VERSION ""

NS_ :

BS_ :

BU_ : CAB FED HAD JDL OBT OBT_FA PDU POD VTV XCP DC1 MTU

BO_ 2565406513 Acknowledgment_CAB: 8 CAB

BO_ 2565406664 Acknowledgment_DC1: 8 DC1

BO_ 2565406698 Acknowledgment_FED: 8 FED

BO_ 2565406699 Acknowledgment_HAD: 8 HAD

BO_ 2565406555 Acknowledgment_POD: 8 POD

BO_ 2565392433 Acknowledgment_TX_CAB_RX_DC1: 8 CAB

BO_ 2565401137 Acknowledgment_TX_CAB_RX_FED: 8 CAB

BO_ 2565401393 Acknowledgment_TX_CAB_RX_HAD: 8 CAB

BO_ 2565364529 Acknowledgment_TX_CAB_RX_POD: 8 CAB

BO_ 2565353928 Acknowledgment_TX_DC1_RX_CAB: 8 DC1

BO_ 2565401288 Acknowledgment_TX_DC1_RX_FED: 8 DC1

BO_ 2565401544 Acknowledgment_TX_DC1_RX_HAD: 8 DC1

BO_ 2565364680 Acknowledgment_TX_DC1_RX_POD: 8 DC1

BO_ 2565353962 Acknowledgment_TX_FED_RX_CAB: 8 FED

BO_ 2565392618 Acknowledgment_TX_FED_RX_DC1: 8 FED

BO_ 2565401578 Acknowledgment_TX_FED_RX_HAD: 8 FED

BO_ 2565364714 Acknowledgment_TX_FED_RX_POD: 8 FED

BO_ 2565353963 Acknowledgment_TX_HAD_RX_CAB: 8 HAD

BO_ 2565392619 Acknowledgment_TX_HAD_RX_DC1: 8 HAD

BO_ 2565401323 Acknowledgment_TX_HAD_RX_FED: 8 HAD

BO_ 2565364715 Acknowledgment_TX_HAD_RX_POD: 8 HAD

BO_ 2565353819 Acknowledgment_TX_POD_RX_CAB: 8 POD

BO_ 2565392475 Acknowledgment_TX_POD_RX_DC1: 8 POD

BO_ 2565401179 Acknowledgment_TX_POD_RX_FED: 8 POD

BO_ 2565401435 Acknowledgment_TX_POD_RX_HAD: 8 POD

BO_ 2565799729 Address_Claimed_CAB: 8 CAB

BO_ 2565799880 Address_Claimed_DC1: 8 DC1

BO_ 2565799914 Address_Claimed_FED: 8 FED

BO_ 2565799915 Address_Claimed_HAD: 8 HAD

BO_ 2565799771 Address_Claimed_POD: 8 POD

BO_ 2566757374 AfteDiesExhaFluiInfo_Vector__XXX: 8 Vector__XXX
 SG_ AftrtrtmntDEFConc : 8|8@1+ (0.25,0) [0|62.5] ""  JDL
 SG_ AftrtrtmntDEFProp : 40|4@1+ (1,0) [0|15] ""  JDL

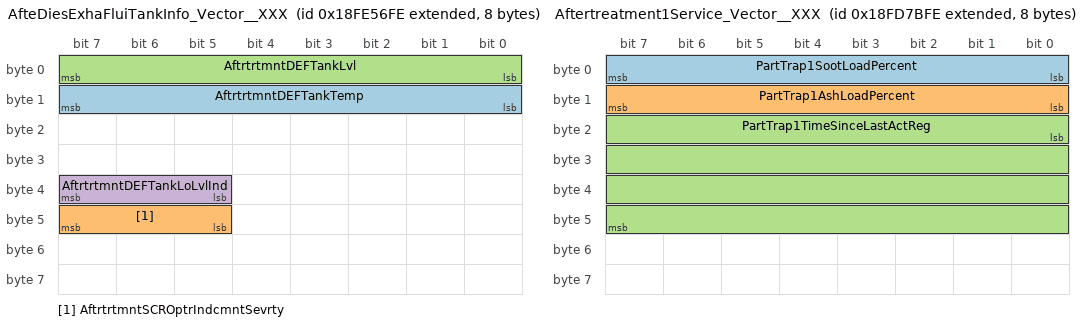
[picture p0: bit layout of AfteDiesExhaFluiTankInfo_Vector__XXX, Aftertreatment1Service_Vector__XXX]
BO_ 2566805246 AfteDiesExhaFluiTankInfo_Vector__XXX: 8 Vector__XXX
 SG_ AftrtrtmntDEFTankTemp : 8|8@1+ (1,-40) [-40|210] ""  JDL
 SG_ AftrtrtmntSCROptrIndcmntSevrty : 45|3@1+ (1,0) [0|7] ""  JDL
 SG_ AftrtrtmntDEFTankLvl : 0|8@1+ (0.4,0) [0|100] ""  PDU
 SG_ AftrtrtmntDEFTankLoLvlInd : 37|3@1+ (1,0) [0|7] ""  PDU

BO_ 2566749182 Aftertreatment1Service_Vector__XXX: 8 Vector__XXX
 SG_ PartTrap1SootLoadPercent : 0|8@1+ (1,0) [0|2.5] ""  JDL
 SG_ PartTrap1AshLoadPercent : 8|8@1+ (1,0) [0|2.5] ""  JDL
 SG_ PartTrap1TimeSinceLastActReg : 16|32@1+ (1,0) [0|4211081215] ""  JDL

BO_ 2566763518 AftertreatmentOutletGas2_Vector__XXX: 8 Vector__XXX
 SG_ AftrDiesPartFltrOutlGasTemp : 16|16@1+ (0.03125,-273) [-273|1735] ""  JDL

BO_ 2566700542 AfteSCRServInfo2_Vector__XXX: 8 Vector__XXX
 SG_ AftrtrtmntTotalDEFUsed : 0|32@1+ (0.5,0) [0|2105540607.5] ""  JDL

BO_ 2565874686 AfteTreaSCRDosiSystInfo_Vector__XXX: 8 Vector__XXX
 SG_ AftrTrtmDiesExhsFldActDsngQty : 0|16@1+ (0.3,0) [0|19276.5] ""  JDL

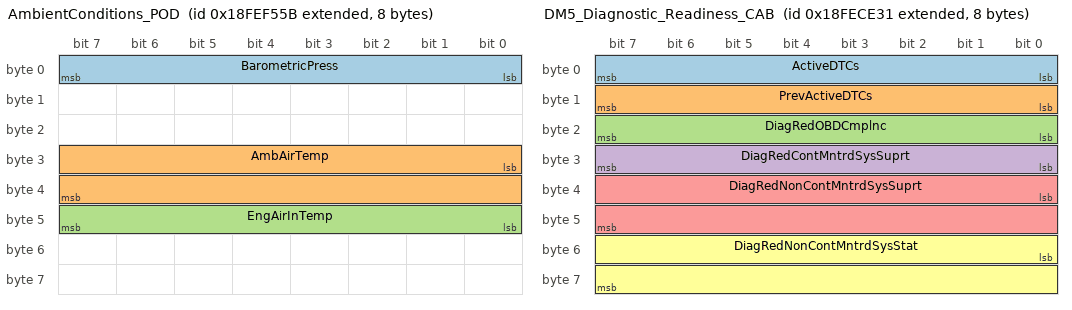
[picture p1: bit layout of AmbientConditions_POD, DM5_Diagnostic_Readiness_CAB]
BO_ 2566845787 AmbientConditions_POD: 8 POD
 SG_ BarometricPress : 0|8@1+ (0.5,0) [0|125] ""  CAB
 SG_ AmbAirTemp : 24|16@1+ (0.03125,-273) [-273|1735] "NoUnit3"  CAB,HAD
 SG_ EngAirInTemp : 40|8@1+ (1,-40) [-40|210] ""  CAB,HAD

BO_ 2564292401 Binary_Data_Transfer_CAB: 8 CAB

BO_ 2628399614 ClieECUtoFileServ_TX_Vector__XXX_RX_CAB: 8 Vector__XXX

BO_ 2628438270 ClieECUtoFileServ_TX_Vector__XXX_RX_DC1: 8 Vector__XXX

BO_ 2628446974 ClieECUtoFileServ_TX_Vector__XXX_RX_FED: 8 Vector__XXX

BO_ 2628447230 ClieECUtoFileServ_TX_Vector__XXX_RX_HAD: 8 Vector__XXX

BO_ 2628410366 ClieECUtoFileServ_TX_Vector__XXX_RX_POD: 8 Vector__XXX

BO_ 2628452350 Client_ECU_to_File_Server_Vector__XXX: 8 Vector__XXX

BO_ 2432635995 ClosSyst5JDHWSmarFeedNewSp_POD: 8 POD
 SG_ HarvestSmartPauseResumeCmd : 58|2@1+ (1,0) [0|3] ""  VTV

BO_ 2566838321 Commanded_Address_CAB: 9 CAB

BO_ 2566838472 Commanded_Address_DC1: 9 DC1

BO_ 2566838506 Commanded_Address_FED: 9 FED

BO_ 2566838507 Commanded_Address_HAD: 9 HAD

BO_ 2566838363 Commanded_Address_POD: 9 POD

BO_ 2298409307 CruiseControlVehicleSpeed_POD: 8 POD
 SG_ WheelBasedVehicleSpeed : 8|16@1+ (0.00390625,0) [0|250.996] "KiloMtrPerHr"  CAB,FED,HAD,PDU,VTV,DC1
 SG_ BrakeSwitch : 28|2@1+ (1,0) [0|3] ""  CAB,VTV

BO_ 2499738715 DashDisplay_POD: 8 POD
 SG_ FuelLevel : 8|8@1+ (0.4,0) [0|100] ""  PDU,VTV

BO_ 2566850865 DiagDeviIdenTLA_CAB: 8 CAB
 SG_ DIAGTLA : 0|24@1+ (1,0) [0|0] ""  FED,HAD,POD,DC1

BO_ 2566851016 DiagDeviIdenTLA_DC1: 8 DC1
 SG_ DIAGTLA : 0|24@1+ (1,0) [0|0] ""  CAB,FED,HAD,POD

BO_ 2566851050 DiagDeviIdenTLA_FED: 8 FED
 SG_ DIAGTLA : 0|24@1+ (1,0) [0|0] ""  CAB,HAD,POD,DC1

BO_ 2566851051 DiagDeviIdenTLA_HAD: 8 HAD
 SG_ DIAGTLA : 0|24@1+ (1,0) [0|0] ""  CAB,FED,POD,DC1

BO_ 2566850907 DiagDeviIdenTLA_POD: 8 POD
 SG_ DIAGTLA : 0|24@1+ (1,0) [0|0] ""  CAB,FED,HAD,DC1

BO_ 2566730440 Diagnostic_Protocol_DC1: 8 DC1

BO_ 2566730474 Diagnostic_Protocol_FED: 8 FED

BO_ 2566730475 Diagnostic_Protocol_HAD: 8 HAD

BO_ 2566730331 Diagnostic_Protocol_POD: 8 POD

BO_ 2562719537 Diagnostic_Window_Shade_CAB: 8 CAB

BO_ 2562719722 Diagnostic_Window_Shade_FED: 8 FED

BO_ 2562719723 Diagnostic_Window_Shade_HAD: 8 HAD

BO_ 2562719579 Diagnostic_Window_Shade_POD: 8 POD

BO_ 2566749438 DiesPartFiltCont1_Vector__XXX: 8 Vector__XXX
 SG_ CANExhstSysHighTempLmpCmd : 50|3@1+ (1,0) [0|7] ""  PDU

BO_ 2566719270 DirectLampControlCommand_VTV: 8 VTV
 SG_ EngRedStopLmpCmd : 4|2@1+ (1,0) [0|3] ""  FED,HAD,POD

BO_ 2566837041 DM11ClearResetofActiveDTCs_CAB: 8 CAB

BO_ 2566837192 DM11ClearResetofActiveDTCs_DC1: 8 DC1

BO_ 2566837226 DM11ClearResetofActiveDTCs_FED: 8 FED

BO_ 2566837227 DM11ClearResetofActiveDTCs_HAD: 8 HAD

BO_ 2566837083 DM11ClearResetofActiveDTCs_POD: 8 POD

BO_ 2564816894 DM13_StopStart_Broadcast_Vector__XXX: 8 Vector__XXX

BO_ 2566834737 DM1ActiDiagTrouCode_CAB: 6 CAB

BO_ 2566834888 DM1ActiDiagTrouCode_DC1: 6 DC1

BO_ 2566834922 DM1ActiDiagTrouCode_FED: 6 FED

BO_ 2566834923 DM1ActiDiagTrouCode_HAD: 6 HAD

BO_ 2566834779 DM1ActiDiagTrouCode_POD: 6 POD

BO_ 2566834993 DM2PrevActiDiagTrouCode_CAB: 6 CAB

BO_ 2566835144 DM2PrevActiDiagTrouCode_DC1: 6 DC1

BO_ 2566835178 DM2PrevActiDiagTrouCode_FED: 6 FED

BO_ 2566835179 DM2PrevActiDiagTrouCode_HAD: 6 HAD

BO_ 2566835035 DM2PrevActiDiagTrouCode_POD: 6 POD

BO_ 2566835249 DM3CleaResePrevActiDTCs_CAB: 8 CAB

BO_ 2566835400 DM3CleaResePrevActiDTCs_DC1: 8 DC1

BO_ 2566835434 DM3CleaResePrevActiDTCs_FED: 8 FED

BO_ 2566835435 DM3CleaResePrevActiDTCs_HAD: 8 HAD

BO_ 2566835291 DM3CleaResePrevActiDTCs_POD: 8 POD

BO_ 2566835690 DM4_Freeze_Frame_FED: 14 FED

BO_ 2566835691 DM4_Freeze_Frame_HAD: 14 HAD

BO_ 2566835547 DM4_Freeze_Frame_POD: 14 POD

BO_ 2566835761 DM5_Diagnostic_Readiness_CAB: 8 CAB
 SG_ ActiveDTCs : 0|8@1+ (1,0) [0|0] ""  Vector__XXX
 SG_ PrevActiveDTCs : 8|8@1+ (1,0) [0|0] ""  Vector__XXX
 SG_ DiagRedOBDCmplnc : 16|8@1+ (1,0) [0|0] ""  Vector__XXX
 SG_ DiagRedContMntrdSysSuprt : 24|8@1+ (1,0) [0|0] ""  Vector__XXX
 SG_ DiagRedNonContMntrdSysSuprt : 32|16@1+ (1,0) [0|0] ""  Vector__XXX
 SG_ DiagRedNonContMntrdSysStat : 48|16@1+ (1,0) [0|0] ""  Vector__XXX

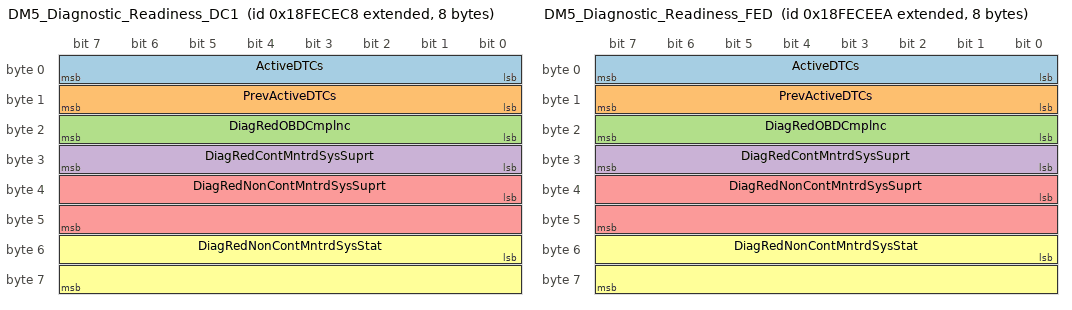
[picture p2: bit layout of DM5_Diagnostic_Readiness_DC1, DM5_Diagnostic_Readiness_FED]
BO_ 2566835912 DM5_Diagnostic_Readiness_DC1: 8 DC1
 SG_ ActiveDTCs : 0|8@1+ (1,0) [0|0] ""  Vector__XXX
 SG_ PrevActiveDTCs : 8|8@1+ (1,0) [0|0] ""  Vector__XXX
 SG_ DiagRedOBDCmplnc : 16|8@1+ (1,0) [0|0] ""  Vector__XXX
 SG_ DiagRedContMntrdSysSuprt : 24|8@1+ (1,0) [0|0] ""  Vector__XXX
 SG_ DiagRedNonContMntrdSysSuprt : 32|16@1+ (1,0) [0|0] ""  Vector__XXX
 SG_ DiagRedNonContMntrdSysStat : 48|16@1+ (1,0) [0|0] ""  Vector__XXX

BO_ 2566835946 DM5_Diagnostic_Readiness_FED: 8 FED
 SG_ ActiveDTCs : 0|8@1+ (1,0) [0|0] ""  Vector__XXX
 SG_ PrevActiveDTCs : 8|8@1+ (1,0) [0|0] ""  Vector__XXX
 SG_ DiagRedOBDCmplnc : 16|8@1+ (1,0) [0|0] ""  Vector__XXX
 SG_ DiagRedContMntrdSysSuprt : 24|8@1+ (1,0) [0|0] ""  Vector__XXX
 SG_ DiagRedNonContMntrdSysSuprt : 32|16@1+ (1,0) [0|0] ""  Vector__XXX
 SG_ DiagRedNonContMntrdSysStat : 48|16@1+ (1,0) [0|0] ""  Vector__XXX

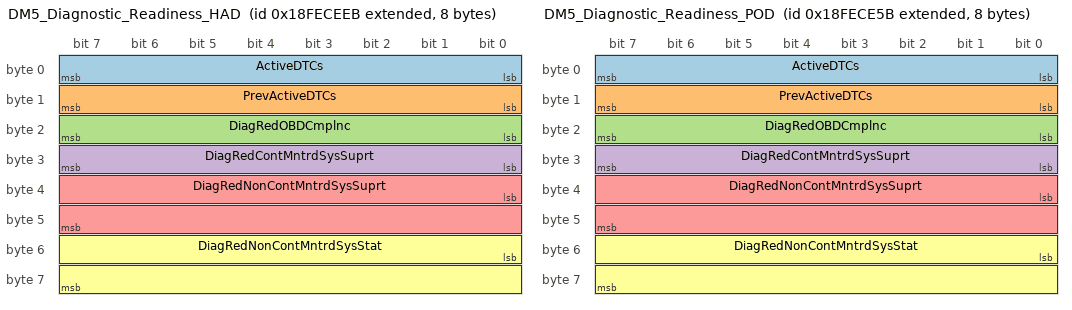
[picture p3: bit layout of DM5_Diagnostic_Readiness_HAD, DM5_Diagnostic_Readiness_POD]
BO_ 2566835947 DM5_Diagnostic_Readiness_HAD: 8 HAD
 SG_ ActiveDTCs : 0|8@1+ (1,0) [0|0] ""  Vector__XXX
 SG_ PrevActiveDTCs : 8|8@1+ (1,0) [0|0] ""  Vector__XXX
 SG_ DiagRedOBDCmplnc : 16|8@1+ (1,0) [0|0] ""  Vector__XXX
 SG_ DiagRedContMntrdSysSuprt : 24|8@1+ (1,0) [0|0] ""  Vector__XXX
 SG_ DiagRedNonContMntrdSysSuprt : 32|16@1+ (1,0) [0|0] ""  Vector__XXX
 SG_ DiagRedNonContMntrdSysStat : 48|16@1+ (1,0) [0|0] ""  Vector__XXX

BO_ 2566835803 DM5_Diagnostic_Readiness_POD: 8 POD
 SG_ ActiveDTCs : 0|8@1+ (1,0) [0|0] ""  Vector__XXX
 SG_ PrevActiveDTCs : 8|8@1+ (1,0) [0|0] ""  Vector__XXX
 SG_ DiagRedOBDCmplnc : 16|8@1+ (1,0) [0|0] ""  Vector__XXX
 SG_ DiagRedContMntrdSysSuprt : 24|8@1+ (1,0) [0|0] ""  Vector__XXX
 SG_ DiagRedNonContMntrdSysSuprt : 32|16@1+ (1,0) [0|0] ""  Vector__XXX
 SG_ DiagRedNonContMntrdSysStat : 48|16@1+ (1,0) [0|0] ""  Vector__XXX

BO_ 2566767921 ECUIdentificationInformation_CAB: 1 CAB

BO_ 2566768072 ECUIdentificationInformation_DC1: 1 DC1

BO_ 2566768106 ECUIdentificationInformation_FED: 1 FED

BO_ 2566768107 ECUIdentificationInformation_HAD: 1 HAD

BO_ 2566768088 ECUIdentificationInformation_MTU: 1 MTU

BO_ 2566767963 ECUIdentificationInformation_POD: 1 POD

BO_ 2565326897 ECUtoVirtTerm_TX_CAB_RX_DC1: 8 CAB

BO_ 2565335601 ECUtoVirtTerm_TX_CAB_RX_FED: 8 CAB

BO_ 2565335857 ECUtoVirtTerm_TX_CAB_RX_HAD: 8 CAB

BO_ 2565298993 ECUtoVirtTerm_TX_CAB_RX_POD: 8 CAB

BO_ 2565288392 ECUtoVirtTerm_TX_DC1_RX_CAB: 8 DC1

BO_ 2565335752 ECUtoVirtTerm_TX_DC1_RX_FED: 8 DC1

BO_ 2565336008 ECUtoVirtTerm_TX_DC1_RX_HAD: 8 DC1

BO_ 2565299144 ECUtoVirtTerm_TX_DC1_RX_POD: 8 DC1

BO_ 2565288426 ECUtoVirtTerm_TX_FED_RX_CAB: 8 FED

BO_ 2565327082 ECUtoVirtTerm_TX_FED_RX_DC1: 8 FED

BO_ 2565336042 ECUtoVirtTerm_TX_FED_RX_HAD: 8 FED

BO_ 2565299178 ECUtoVirtTerm_TX_FED_RX_POD: 8 FED

BO_ 2565288427 ECUtoVirtTerm_TX_HAD_RX_CAB: 8 HAD

BO_ 2565327083 ECUtoVirtTerm_TX_HAD_RX_DC1: 8 HAD

BO_ 2565335787 ECUtoVirtTerm_TX_HAD_RX_FED: 8 HAD

BO_ 2565299179 ECUtoVirtTerm_TX_HAD_RX_POD: 8 HAD

BO_ 2565288283 ECUtoVirtTerm_TX_POD_RX_CAB: 8 POD

BO_ 2565326939 ECUtoVirtTerm_TX_POD_RX_DC1: 8 POD

BO_ 2565335643 ECUtoVirtTerm_TX_POD_RX_FED: 8 POD

BO_ 2565335899 ECUtoVirtTerm_TX_POD_RX_HAD: 8 POD

BO_ 2565340977 ECUtoVirtual_Terminal_CAB: 8 CAB

BO_ 2565341128 ECUtoVirtual_Terminal_DC1: 8 DC1

BO_ 2565341162 ECUtoVirtual_Terminal_FED: 8 FED

BO_ 2565341163 ECUtoVirtual_Terminal_HAD: 8 HAD

BO_ 2565341019 ECUtoVirtual_Terminal_POD: 8 POD

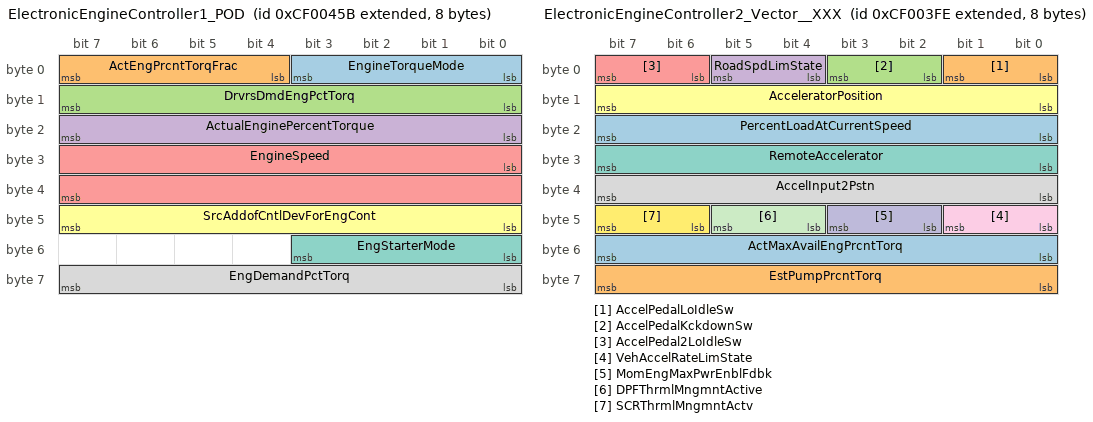
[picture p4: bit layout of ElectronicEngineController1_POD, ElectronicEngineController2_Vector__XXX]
BO_ 2364539995 ElectronicEngineController1_POD: 8 POD
 SG_ EngineTorqueMode : 0|4@1+ (1,0) [0|15] ""  JDL,VTV
 SG_ ActEngPrcntTorqFrac : 4|4@1+ (0.125,0) [0|1.625] ""  JDL,VTV
 SG_ DrvrsDmdEngPctTorq : 8|8@1+ (1,-125) [0|0] ""  JDL,VTV
 SG_ ActualEnginePercentTorque : 16|8@1+ (1,-125) [0|0] ""  JDL,VTV
 SG_ EngineSpeed : 24|16@1+ (0.125,0) [0|8031.875] ""  CAB,FED,HAD,JDL,PDU,VTV,DC1
 SG_ SrcAddofCntlDevForEngCont : 40|8@1+ (1,0) [0|255] ""  JDL,VTV
 SG_ EngStarterMode : 48|4@1+ (1,0) [0|15] ""  CAB,JDL,VTV
 SG_ EngDemandPctTorq : 56|8@1+ (1,-125) [0|0] ""  JDL,VTV

BO_ 2364539902 ElectronicEngineController2_Vector__XXX: 8 Vector__XXX
 SG_ PercentLoadAtCurrentSpeed : 16|8@1+ (1,0) [0|250] ""  HAD
 SG_ AccelPedalLoIdleSw : 0|2@1+ (1,0) [0|3] ""  JDL
 SG_ AccelPedalKckdownSw : 2|2@1+ (1,0) [0|3] ""  JDL
 SG_ RoadSpdLimState : 4|2@1+ (1,0) [0|3] ""  JDL
 SG_ AccelPedal2LoIdleSw : 6|2@1+ (1,0) [0|3] ""  JDL
 SG_ AcceleratorPosition : 8|8@1+ (0.4,0) [0|100] ""  JDL
 SG_ RemoteAccelerator : 24|8@1+ (0.4,0) [0|100] ""  JDL
 SG_ AccelInput2Pstn : 32|8@1+ (0.4,0) [0|100] ""  JDL
 SG_ VehAccelRateLimState : 40|2@1+ (1,0) [0|3] ""  JDL
 SG_ MomEngMaxPwrEnblFdbk : 42|2@1+ (1,0) [0|3] ""  JDL
 SG_ DPFThrmlMngmntActive : 44|2@1+ (1,0) [0|3] ""  JDL
 SG_ SCRThrmlMngmntActv : 46|2@1+ (1,0) [0|3] ""  JDL
 SG_ ActMaxAvailEngPrcntTorq : 48|8@1+ (0.4,0) [0|100] ""  JDL
 SG_ EstPumpPrcntTorq : 56|8@1+ (1,-125) [0|0] ""  JDL

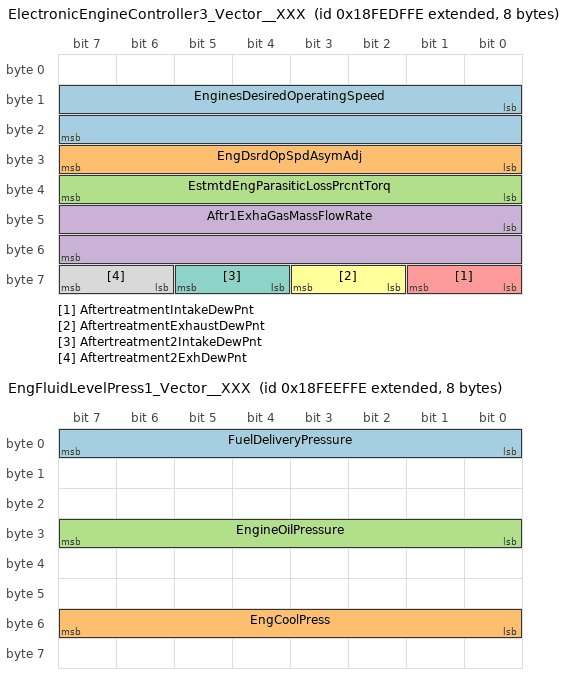
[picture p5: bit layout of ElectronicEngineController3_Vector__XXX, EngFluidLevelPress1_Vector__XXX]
BO_ 2566840318 ElectronicEngineController3_Vector__XXX: 8 Vector__XXX
 SG_ EnginesDesiredOperatingSpeed : 8|16@1+ (0.125,0) [0|8031.875] ""  HAD,POD,VTV
 SG_ EngDsrdOpSpdAsymAdj : 24|8@1+ (1,0) [0|250] ""  JDL
 SG_ EstmtdEngParasiticLossPrcntTorq : 32|8@1+ (1,-125) [0|0] ""  JDL
 SG_ Aftr1ExhaGasMassFlowRate : 40|16@1+ (0.2,0) [0|12851] ""  JDL
 SG_ AftertreatmentIntakeDewPnt : 56|2@1+ (1,0) [0|3] ""  JDL
 SG_ AftertreatmentExhaustDewPnt : 58|2@1+ (1,0) [0|3] ""  JDL
 SG_ Aftertreatment2IntakeDewPnt : 60|2@1+ (1,0) [0|3] ""  JDL
 SG_ Aftertreatment2ExhDewPnt : 62|2@1+ (1,0) [0|3] ""  JDL

BO_ 2662541034 EncrNetwKey_TX_FED_RX_VTV: 32 FED

BO_ 2662591014 EncrNetwKey_TX_VTV_RX_FED: 32 VTV

BO_ 2662596586 EncryptedNetworkKey_FED: 32 FED

BO_ 2662596390 EncryptedNetworkKey_VTV: 32 VTV

BO_ 2566844414 EngFluidLevelPress1_Vector__XXX: 8 Vector__XXX
 SG_ FuelDeliveryPressure : 0|8@1+ (4,0) [0|1000] "KiloPa"  JDL
 SG_ EngCoolPress : 48|8@1+ (2,0) [0|500] "KiloPa"  JDL
 SG_ EngineOilPressure : 24|8@1+ (4,0) [0|1000] "KiloPa"  VTV

BO_ 2566841854 Engine_Hours_Revolutions_Vector__XXX: 8 Vector__XXX
 SG_ EngineHours : 0|32@1+ (0.05,0) [0|210554060.75] ""  CAB,FED,HAD,DC1

BO_ 2566843995 Engine_Temperature_POD: 8 POD
 SG_ EngineCoolantTemperature : 0|8@1+ (1,-40) [-40|210] ""  HAD,PDU
 SG_ FuelTemperature : 8|8@1+ (1,-40) [-40|210] ""  PDU

BO_ 2432537179 EngineOperatingInformation_POD: 8 POD
 SG_ EngOpState : 0|4@1+ (1,0) [0|15] ""  FED,HAD,VTV

BO_ 2431708465 EngineStartControlConsent_CAB: 8 CAB
 SG_ EngineStartRequest : 0|2@1+ (1,0) [0|3] ""  Vector__XXX

BO_ 2431708651 EngineStartControlConsent_HAD: 8 HAD
 SG_ EngineStartConsent : 2|3@1+ (1,0) [0|7] ""  CAB

BO_ 2431708507 EngineStartControlConsent_POD: 8 POD
 SG_ EngineStartConsent : 2|3@1+ (1,0) [0|7] ""  CAB

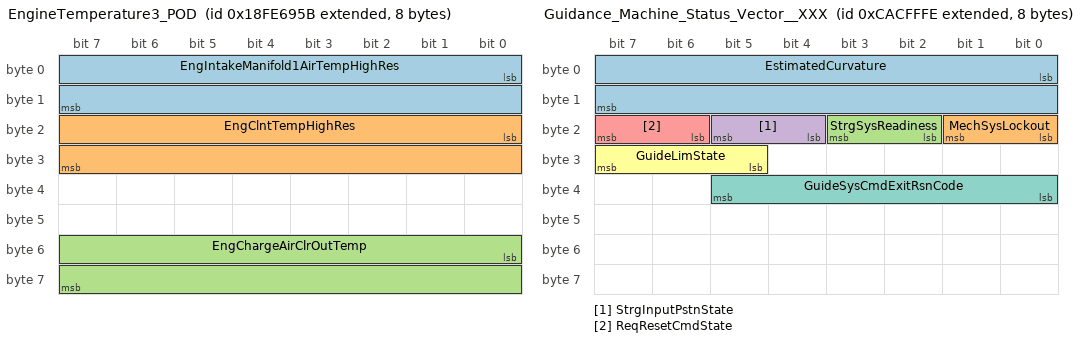
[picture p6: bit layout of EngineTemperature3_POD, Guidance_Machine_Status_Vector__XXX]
BO_ 2566809947 EngineTemperature3_POD: 8 POD
 SG_ EngIntakeManifold1AirTempHighRes : 0|16@1+ (0.03125,-273) [-273|1735] ""  CAB,JDL
 SG_ EngClntTempHighRes : 16|16@1+ (0.03125,-273) [-273|1735] ""  CAB,JDL
 SG_ EngChargeAirClrOutTemp : 48|16@1+ (0.03125,-273) [-273|1735] ""  CAB,JDL

BO_ 2563309361 ExteTranProtConnMana_CAB: 8 CAB

BO_ 2563309512 ExteTranProtConnMana_DC1: 8 DC1

BO_ 2563309546 ExteTranProtConnMana_FED: 8 FED

BO_ 2563309547 ExteTranProtConnMana_HAD: 8 HAD

BO_ 2563309403 ExteTranProtConnMana_POD: 8 POD

BO_ 2563295281 ExteTranProtConnMana_TX_CAB_RX_DC1: 8 CAB

BO_ 2563303985 ExteTranProtConnMana_TX_CAB_RX_FED: 8 CAB

BO_ 2563304241 ExteTranProtConnMana_TX_CAB_RX_HAD: 8 CAB

BO_ 2563267377 ExteTranProtConnMana_TX_CAB_RX_POD: 8 CAB

BO_ 2563256776 ExteTranProtConnMana_TX_DC1_RX_CAB: 8 DC1

BO_ 2563304136 ExteTranProtConnMana_TX_DC1_RX_FED: 8 DC1

BO_ 2563304392 ExteTranProtConnMana_TX_DC1_RX_HAD: 8 DC1

BO_ 2563267528 ExteTranProtConnMana_TX_DC1_RX_POD: 8 DC1

BO_ 2563256810 ExteTranProtConnMana_TX_FED_RX_CAB: 8 FED

BO_ 2563295466 ExteTranProtConnMana_TX_FED_RX_DC1: 8 FED

BO_ 2563304426 ExteTranProtConnMana_TX_FED_RX_HAD: 8 FED

BO_ 2563267562 ExteTranProtConnMana_TX_FED_RX_POD: 8 FED

BO_ 2563256811 ExteTranProtConnMana_TX_HAD_RX_CAB: 8 HAD

BO_ 2563295467 ExteTranProtConnMana_TX_HAD_RX_DC1: 8 HAD

BO_ 2563304171 ExteTranProtConnMana_TX_HAD_RX_FED: 8 HAD

BO_ 2563267563 ExteTranProtConnMana_TX_HAD_RX_POD: 8 HAD

BO_ 2563256667 ExteTranProtConnMana_TX_POD_RX_CAB: 8 POD

BO_ 2563295323 ExteTranProtConnMana_TX_POD_RX_DC1: 8 POD

BO_ 2563304027 ExteTranProtConnMana_TX_POD_RX_FED: 8 POD

BO_ 2563304283 ExteTranProtConnMana_TX_POD_RX_HAD: 8 POD

BO_ 2563243825 ExteTranProtDataTran_CAB: 8 CAB

BO_ 2563243976 ExteTranProtDataTran_DC1: 8 DC1

BO_ 2563244010 ExteTranProtDataTran_FED: 8 FED

BO_ 2563244011 ExteTranProtDataTran_HAD: 8 HAD

BO_ 2563243867 ExteTranProtDataTran_POD: 8 POD

BO_ 2563229745 ExteTranProtDataTran_TX_CAB_RX_DC1: 8 CAB

BO_ 2563238449 ExteTranProtDataTran_TX_CAB_RX_FED: 8 CAB

BO_ 2563238705 ExteTranProtDataTran_TX_CAB_RX_HAD: 8 CAB

BO_ 2563201841 ExteTranProtDataTran_TX_CAB_RX_POD: 8 CAB

BO_ 2563191240 ExteTranProtDataTran_TX_DC1_RX_CAB: 8 DC1

BO_ 2563238600 ExteTranProtDataTran_TX_DC1_RX_FED: 8 DC1

BO_ 2563238856 ExteTranProtDataTran_TX_DC1_RX_HAD: 8 DC1

BO_ 2563201992 ExteTranProtDataTran_TX_DC1_RX_POD: 8 DC1

BO_ 2563191274 ExteTranProtDataTran_TX_FED_RX_CAB: 8 FED

BO_ 2563229930 ExteTranProtDataTran_TX_FED_RX_DC1: 8 FED

BO_ 2563238890 ExteTranProtDataTran_TX_FED_RX_HAD: 8 FED

BO_ 2563202026 ExteTranProtDataTran_TX_FED_RX_POD: 8 FED

BO_ 2563191275 ExteTranProtDataTran_TX_HAD_RX_CAB: 8 HAD

BO_ 2563229931 ExteTranProtDataTran_TX_HAD_RX_DC1: 8 HAD

BO_ 2563238635 ExteTranProtDataTran_TX_HAD_RX_FED: 8 HAD

BO_ 2563202027 ExteTranProtDataTran_TX_HAD_RX_POD: 8 HAD

BO_ 2563191131 ExteTranProtDataTran_TX_POD_RX_CAB: 8 POD

BO_ 2563229787 ExteTranProtDataTran_TX_POD_RX_DC1: 8 POD

BO_ 2563238491 ExteTranProtDataTran_TX_POD_RX_FED: 8 POD

BO_ 2563238747 ExteTranProtDataTran_TX_POD_RX_HAD: 8 POD

BO_ 2628517681 File_Server_to_Client_ECU_CAB: 8 CAB

BO_ 2628517832 File_Server_to_Client_ECU_DC1: 8 DC1

BO_ 2628517866 File_Server_to_Client_ECU_FED: 8 FED

BO_ 2628517867 File_Server_to_Client_ECU_HAD: 8 HAD

BO_ 2628517723 File_Server_to_Client_ECU_POD: 8 POD

BO_ 2628503601 FileServClieECU_TX_CAB_RX_DC1: 8 CAB

BO_ 2628512305 FileServClieECU_TX_CAB_RX_FED: 8 CAB

BO_ 2628512561 FileServClieECU_TX_CAB_RX_HAD: 8 CAB

BO_ 2628475697 FileServClieECU_TX_CAB_RX_POD: 8 CAB

BO_ 2628465096 FileServClieECU_TX_DC1_RX_CAB: 8 DC1

BO_ 2628512456 FileServClieECU_TX_DC1_RX_FED: 8 DC1

BO_ 2628512712 FileServClieECU_TX_DC1_RX_HAD: 8 DC1

BO_ 2628475848 FileServClieECU_TX_DC1_RX_POD: 8 DC1

BO_ 2628465130 FileServClieECU_TX_FED_RX_CAB: 8 FED

BO_ 2628503786 FileServClieECU_TX_FED_RX_DC1: 8 FED

BO_ 2628512746 FileServClieECU_TX_FED_RX_HAD: 8 FED

BO_ 2628475882 FileServClieECU_TX_FED_RX_POD: 8 FED

BO_ 2628465131 FileServClieECU_TX_HAD_RX_CAB: 8 HAD

BO_ 2628503787 FileServClieECU_TX_HAD_RX_DC1: 8 HAD

BO_ 2628512491 FileServClieECU_TX_HAD_RX_FED: 8 HAD

BO_ 2628475883 FileServClieECU_TX_HAD_RX_POD: 8 HAD

BO_ 2628464987 FileServClieECU_TX_POD_RX_CAB: 8 POD

BO_ 2628503643 FileServClieECU_TX_POD_RX_DC1: 8 POD

BO_ 2628512347 FileServClieECU_TX_POD_RX_FED: 8 POD

BO_ 2628512603 FileServClieECU_TX_POD_RX_HAD: 8 POD

BO_ 2662475498 FollCert_TX_FED_RX_VTV: 816 FED

BO_ 2662525478 FollCert_TX_VTV_RX_FED: 816 VTV

BO_ 2662531050 FollowerCertificate_FED: 816 FED

BO_ 2662530854 FollowerCertificate_VTV: 816 VTV

BO_ 2566842878 FuelConsumption_Vector__XXX: 8 Vector__XXX
 SG_ TotalFuelUsed : 32|32@1+ (0.5,0) [0|2105540607.5] "Litre"  JDL

BO_ 2566845182 FuelEconomyLiq_Vector__XXX: 8 Vector__XXX
 SG_ EngFuelRate : 0|16@1+ (0.05,0) [0|0] "LPerHr"  VTV

BO_ 2360147966 Guidance_Machine_Status_Vector__XXX: 8 Vector__XXX
 SG_ EstimatedCurvature : 0|16@1+ (0.25,-8032) [-8032|8031.75] "rad/km"  VTV
 SG_ MechSysLockout : 16|2@1+ (1,0) [0|3] ""  VTV
 SG_ StrgSysReadiness : 18|2@1+ (1,0) [0|3] ""  VTV
 SG_ StrgInputPstnState : 20|2@1+ (1,0) [0|3] ""  VTV
 SG_ ReqResetCmdState : 22|2@1+ (1,0) [0|3] ""  VTV
 SG_ GuideLimState : 29|3@1+ (1,0) [0|7] ""  VTV
 SG_ GuideSysCmdExitRsnCode : 32|6@1+ (1,0) [0|63] ""  VTV

BO_ 2360213286 Guidance_System_Command_VTV: 8 VTV
 SG_ CurvCmd : 0|16@1+ (0.25,-8032) [-8032|8031.75] "rad/km"  Vector__XXX
 SG_ CurvatureCmdState : 16|2@1+ (1,0) [0|3] ""  Vector__XXX

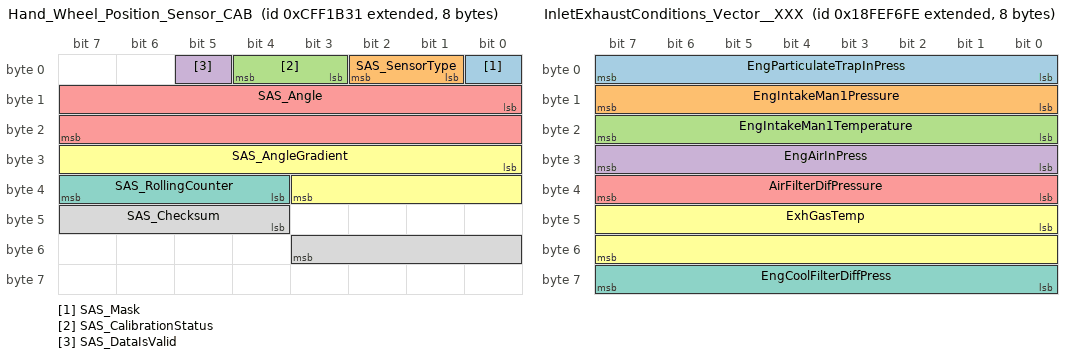
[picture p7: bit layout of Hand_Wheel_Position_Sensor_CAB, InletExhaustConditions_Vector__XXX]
BO_ 2365528881 Hand_Wheel_Position_Sensor_CAB: 8 CAB
 SG_ SAS_Mask : 0|1@1+ (1,0) [0|1] ""  Vector__XXX
 SG_ SAS_SensorType : 1|2@1+ (1,0) [0|3] ""  Vector__XXX
 SG_ SAS_CalibrationStatus : 3|2@1+ (1,0) [0|3] ""  Vector__XXX
 SG_ SAS_DataIsValid : 5|1@1+ (1,0) [0|1] ""  Vector__XXX
 SG_ SAS_Angle : 8|16@1+ (0.0625,-2048) [-2048|2047] "deg"  Vector__XXX
 SG_ SAS_AngleGradient : 24|12@1+ (1,0) [0|0] ""  Vector__XXX
 SG_ SAS_RollingCounter : 36|4@1+ (1,0) [0|15] "Count"  Vector__XXX
 SG_ SAS_Checksum : 44|8@1+ (1,0) [0|255] "Count"  Vector__XXX

BO_ 2361850878 HLVGenePurpValvEstiFlow_TX_Vector__XXX_RX_JDL: 8 Vector__XXX
 SG_ HeaderLiftValveStateFeedback : 16|4@1+ (1,0) [0|15] ""  JDL

BO_ 2361851902 HLVGenePurpValvEstiFlow_Vector__XXX: 8 Vector__XXX
 SG_ HeaderLiftValveStateFeedback : 16|4@1+ (1,0) [0|15] ""  JDL

BO_ 2566846206 InletExhaustConditions_Vector__XXX: 8 Vector__XXX
 SG_ EngParticulateTrapInPress : 0|8@1+ (0.5,0) [0|125] ""  JDL
 SG_ EngIntakeMan1Pressure : 8|8@1+ (1,-32000) [-32000|255] ""  JDL
 SG_ EngIntakeMan1Temperature : 16|8@1+ (1,-32000) [-32000|255] ""  JDL
 SG_ EngAirInPress : 24|8@1+ (2,0) [0|500] ""  JDL
 SG_ AirFilterDifPressure : 32|8@1+ (0.05,0) [0|12.5] "kPa"  JDL
 SG_ ExhGasTemp : 40|16@1+ (0.03125,-273) [0|0] ""  JDL
 SG_ EngCoolFilterDiffPress : 56|8@1+ (0.5,0) [0|125] ""  JDL

BO_ 2566734536 ISOBUSCompCert_DC1: 8 DC1

BO_ 2566734570 ISOBUSCompCert_FED: 8 FED

BO_ 2566734571 ISOBUSCompCert_HAD: 8 HAD

BO_ 2566734427 ISOBUSCompCert_POD: 8 POD

BO_ 2566878001 JD_Product_Identification_CAB: 8 CAB

BO_ 2566878152 JD_Product_Identification_DC1: 8 DC1

BO_ 2566878186 JD_Product_Identification_FED: 8 FED

BO_ 2566878187 JD_Product_Identification_HAD: 8 HAD

BO_ 2566878043 JD_Product_Identification_POD: 8 POD

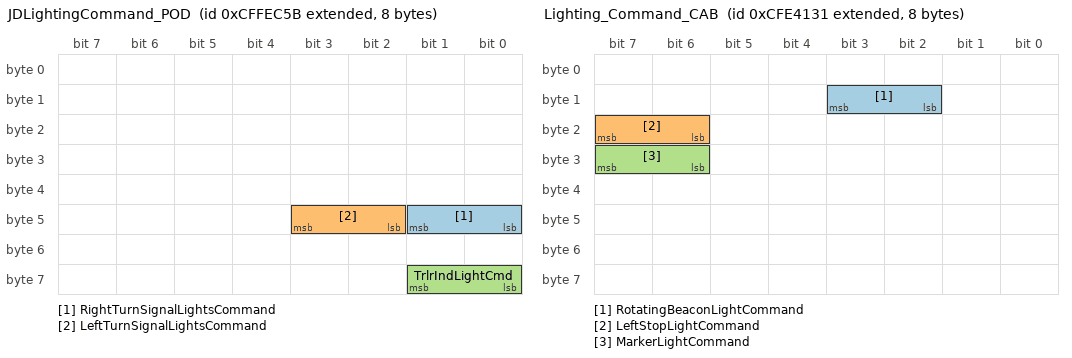
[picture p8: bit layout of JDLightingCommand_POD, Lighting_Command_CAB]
BO_ 2365582427 JDLightingCommand_POD: 8 POD
 SG_ RightTurnSignalLightsCommand : 40|2@1+ (1,0) [0|3] ""  PDU
 SG_ LeftTurnSignalLightsCommand : 42|2@1+ (1,0) [0|3] ""  PDU
 SG_ TrlrIndLightCmd : 56|2@1+ (1,0) [0|3] ""  CAB

BO_ 2566786865 Language_Command_CAB: 8 CAB

BO_ 2566787016 Language_Command_DC1: 8 DC1

BO_ 2566787050 Language_Command_FED: 8 FED

BO_ 2566787051 Language_Command_HAD: 8 HAD

BO_ 2566786907 Language_Command_POD: 8 POD

BO_ 2662465514 LeaderCertificate_FED: 816 FED

BO_ 2662409962 LeaderCertificate_TX_FED_RX_VTV: 816 FED

BO_ 2662459942 LeaderCertificate_TX_VTV_RX_FED: 816 VTV

BO_ 2662465318 LeaderCertificate_VTV: 816 VTV

BO_ 2365473073 Lighting_Command_CAB: 8 CAB
 SG_ RotatingBeaconLightCommand : 10|2@1+ (1,0) [0|3] ""  POD
 SG_ LeftStopLightCommand : 22|2@1+ (1,0) [0|3] ""  POD
 SG_ MarkerLightCommand : 30|2@1+ (1,0) [0|3] ""  POD

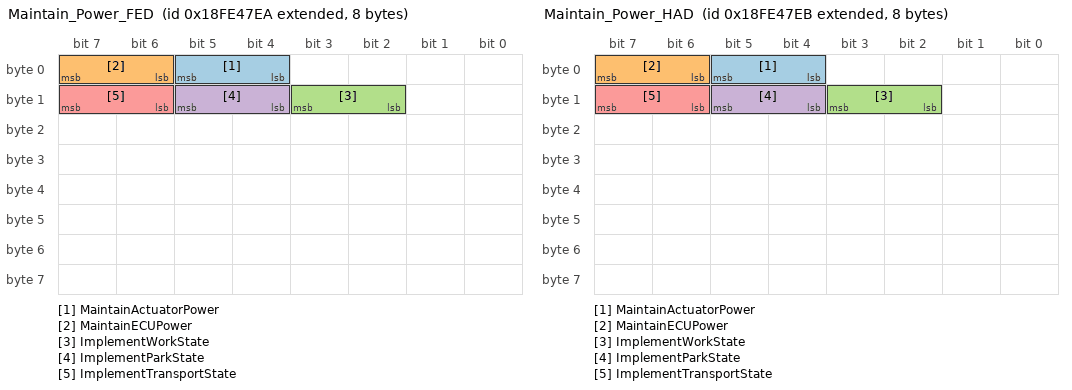
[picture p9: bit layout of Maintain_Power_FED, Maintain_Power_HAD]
BO_ 2566801386 Maintain_Power_FED: 8 FED
 SG_ MaintainActuatorPower : 4|2@1+ (1,0) [0|3] ""  Vector__XXX
 SG_ MaintainECUPower : 6|2@1+ (1,0) [0|3] ""  Vector__XXX
 SG_ ImplementWorkState : 10|2@1+ (1,0) [0|3] ""  Vector__XXX
 SG_ ImplementParkState : 12|2@1+ (1,0) [0|3] ""  Vector__XXX
 SG_ ImplementTransportState : 14|2@1+ (1,0) [0|3] ""  Vector__XXX

BO_ 2566801387 Maintain_Power_HAD: 8 HAD
 SG_ MaintainActuatorPower : 4|2@1+ (1,0) [0|3] ""  Vector__XXX
 SG_ MaintainECUPower : 6|2@1+ (1,0) [0|3] ""  Vector__XXX
 SG_ ImplementWorkState : 10|2@1+ (1,0) [0|3] ""  Vector__XXX
 SG_ ImplementParkState : 12|2@1+ (1,0) [0|3] ""  Vector__XXX
 SG_ ImplementTransportState : 14|2@1+ (1,0) [0|3] ""  Vector__XXX

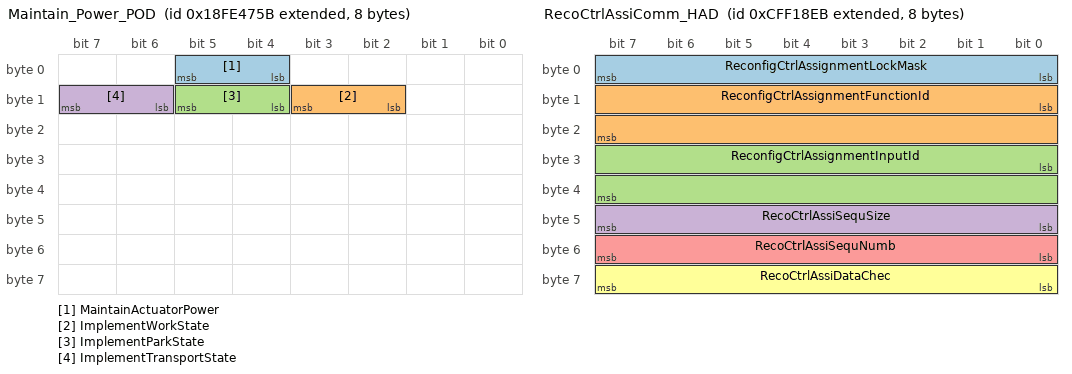
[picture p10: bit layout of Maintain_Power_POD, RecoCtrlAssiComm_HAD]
BO_ 2566801243 Maintain_Power_POD: 8 POD
 SG_ MaintainActuatorPower : 4|2@1+ (1,0) [0|3] ""  Vector__XXX
 SG_ ImplementWorkState : 10|2@1+ (1,0) [0|3] ""  Vector__XXX
 SG_ ImplementParkState : 12|2@1+ (1,0) [0|3] ""  Vector__XXX
 SG_ ImplementTransportState : 14|2@1+ (1,0) [0|3] ""  Vector__XXX

BO_ 2662727658 MemberNonce_FED: 32 FED

BO_ 2662672106 MemberNonce_TX_FED_RX_VTV: 32 FED

BO_ 2662722086 MemberNonce_TX_VTV_RX_FED: 32 VTV

BO_ 2662727462 MemberNonce_VTV: 32 VTV

BO_ 2564423473 Memory_Access_Request_CAB: 8 CAB

BO_ 2564423624 Memory_Access_Request_DC1: 8 DC1

BO_ 2564423658 Memory_Access_Request_FED: 8 FED

BO_ 2564423659 Memory_Access_Request_HAD: 8 HAD

BO_ 2564423515 Memory_Access_Request_POD: 8 POD

BO_ 2564357937 Memory_Access_Response_CAB: 8 CAB

BO_ 2564358088 Memory_Access_Response_DC1: 8 DC1

BO_ 2564358122 Memory_Access_Response_FED: 8 FED

BO_ 2564358123 Memory_Access_Response_HAD: 8 HAD

BO_ 2564357979 Memory_Access_Response_POD: 8 POD

BO_ 2662399978 NetworkKeyHash_FED: 16 FED

BO_ 2662344426 NetworkKeyHash_TX_FED_RX_VTV: 16 FED

BO_ 2662394406 NetworkKeyHash_TX_VTV_RX_FED: 16 VTV

BO_ 2662399782 NetworkKeyHash_VTV: 16 VTV

BO_ 2362179377 Process_Data_Message_CAB: 8 CAB

BO_ 2362179528 Process_Data_Message_DC1: 8 DC1

BO_ 2362179562 Process_Data_Message_FED: 8 FED

BO_ 2362179563 Process_Data_Message_HAD: 8 HAD

BO_ 2362179419 Process_Data_Message_POD: 8 POD

BO_ 2566688200 ProdIdenInfo_DC1: 8 DC1

BO_ 2566688234 ProdIdenInfo_FED: 8 FED

BO_ 2566688235 ProdIdenInfo_HAD: 8 HAD

BO_ 2566688091 ProdIdenInfo_POD: 8 POD

BO_ 2365528299 RecoCtrlAssiComm_HAD: 8 HAD
 SG_ ReconfigCtrlAssignmentLockMask : 0|8@1+ (1,0) [0|255] ""  FED,POD
 SG_ ReconfigCtrlAssignmentFunctionId : 8|16@1+ (1,0) [0|65279] ""  FED,POD
 SG_ ReconfigCtrlAssignmentInputId : 24|16@1+ (1,0) [0|65279] ""  FED,POD
 SG_ RecoCtrlAssiSequSize : 40|8@1+ (1,0) [0|255] ""  FED,POD
 SG_ RecoCtrlAssiSequNumb : 48|8@1+ (1,0) [0|255] ""  FED,POD
 SG_ RecoCtrlAssiDataChec : 56|8@1+ (1,0) [0|255] ""  FED,POD

BO_ 2563374897 Request_2_CAB: 8 CAB

BO_ 2563375048 Request_2_DC1: 8 DC1

BO_ 2563375082 Request_2_FED: 8 FED

BO_ 2563375083 Request_2_HAD: 8 HAD

BO_ 2563374939 Request_2_POD: 8 POD

BO_ 2563360817 Request_2_TX_CAB_RX_DC1: 8 CAB

BO_ 2563369521 Request_2_TX_CAB_RX_FED: 8 CAB

BO_ 2563369777 Request_2_TX_CAB_RX_HAD: 8 CAB

BO_ 2563332913 Request_2_TX_CAB_RX_POD: 8 CAB

BO_ 2563322312 Request_2_TX_DC1_RX_CAB: 8 DC1

BO_ 2563369672 Request_2_TX_DC1_RX_FED: 8 DC1

BO_ 2563369928 Request_2_TX_DC1_RX_HAD: 8 DC1

BO_ 2563333064 Request_2_TX_DC1_RX_POD: 8 DC1

BO_ 2563322346 Request_2_TX_FED_RX_CAB: 8 FED

BO_ 2563361002 Request_2_TX_FED_RX_DC1: 8 FED

BO_ 2563369962 Request_2_TX_FED_RX_HAD: 8 FED

BO_ 2563333098 Request_2_TX_FED_RX_POD: 8 FED

BO_ 2563322347 Request_2_TX_HAD_RX_CAB: 8 HAD

BO_ 2563361003 Request_2_TX_HAD_RX_DC1: 8 HAD

BO_ 2563369707 Request_2_TX_HAD_RX_FED: 8 HAD

BO_ 2563333099 Request_2_TX_HAD_RX_POD: 8 HAD

BO_ 2563322203 Request_2_TX_POD_RX_CAB: 8 POD

BO_ 2563360859 Request_2_TX_POD_RX_DC1: 8 POD

BO_ 2563369563 Request_2_TX_POD_RX_FED: 8 POD

BO_ 2563369819 Request_2_TX_POD_RX_HAD: 8 POD

BO_ 2565537585 Request_PGN_CAB: 3 CAB

BO_ 2565537736 Request_PGN_DC1: 3 DC1

BO_ 2565537770 Request_PGN_FED: 3 FED

BO_ 2565537771 Request_PGN_HAD: 3 HAD

BO_ 2565537627 Request_PGN_POD: 3 POD

BO_ 2565537574 Request_PGN_VTV: 3 VTV

BO_ 2358116145 SequContClieSequContMast_CAB: 8 CAB

BO_ 2358116296 SequContClieSequContMast_DC1: 8 DC1

BO_ 2358116330 SequContClieSequContMast_FED: 8 FED

BO_ 2358116331 SequContClieSequContMast_HAD: 8 HAD

BO_ 2358116187 SequContClieSequContMast_POD: 8 POD

BO_ 2358102065 SequContClieSequContMast_TX_CAB_RX_DC1: 8 CAB

BO_ 2358110769 SequContClieSequContMast_TX_CAB_RX_FED: 8 CAB

BO_ 2358111025 SequContClieSequContMast_TX_CAB_RX_HAD: 8 CAB

BO_ 2358074161 SequContClieSequContMast_TX_CAB_RX_POD: 8 CAB

BO_ 2358063560 SequContClieSequContMast_TX_DC1_RX_CAB: 8 DC1

BO_ 2358110920 SequContClieSequContMast_TX_DC1_RX_FED: 8 DC1

BO_ 2358111176 SequContClieSequContMast_TX_DC1_RX_HAD: 8 DC1

BO_ 2358074312 SequContClieSequContMast_TX_DC1_RX_POD: 8 DC1

BO_ 2358063594 SequContClieSequContMast_TX_FED_RX_CAB: 8 FED

BO_ 2358102250 SequContClieSequContMast_TX_FED_RX_DC1: 8 FED

BO_ 2358111210 SequContClieSequContMast_TX_FED_RX_HAD: 8 FED

BO_ 2358074346 SequContClieSequContMast_TX_FED_RX_POD: 8 FED

BO_ 2358063595 SequContClieSequContMast_TX_HAD_RX_CAB: 8 HAD

BO_ 2358102251 SequContClieSequContMast_TX_HAD_RX_DC1: 8 HAD

BO_ 2358110955 SequContClieSequContMast_TX_HAD_RX_FED: 8 HAD

BO_ 2358074347 SequContClieSequContMast_TX_HAD_RX_POD: 8 HAD

BO_ 2358063451 SequContClieSequContMast_TX_POD_RX_CAB: 8 POD

BO_ 2358102107 SequContClieSequContMast_TX_POD_RX_DC1: 8 POD

BO_ 2358110811 SequContClieSequContMast_TX_POD_RX_FED: 8 POD

BO_ 2358111067 SequContClieSequContMast_TX_POD_RX_HAD: 8 POD

BO_ 2358181681 SequContMastSequContClie_CAB: 8 CAB

BO_ 2358181832 SequContMastSequContClie_DC1: 8 DC1

BO_ 2358181866 SequContMastSequContClie_FED: 8 FED

BO_ 2358181867 SequContMastSequContClie_HAD: 8 HAD

BO_ 2358181723 SequContMastSequContClie_POD: 8 POD

BO_ 2358167601 SequContMastSequContClie_TX_CAB_RX_DC1: 8 CAB

BO_ 2358176305 SequContMastSequContClie_TX_CAB_RX_FED: 8 CAB

BO_ 2358176561 SequContMastSequContClie_TX_CAB_RX_HAD: 8 CAB

BO_ 2358139697 SequContMastSequContClie_TX_CAB_RX_POD: 8 CAB

BO_ 2358129096 SequContMastSequContClie_TX_DC1_RX_CAB: 8 DC1

BO_ 2358176456 SequContMastSequContClie_TX_DC1_RX_FED: 8 DC1

BO_ 2358176712 SequContMastSequContClie_TX_DC1_RX_HAD: 8 DC1

BO_ 2358139848 SequContMastSequContClie_TX_DC1_RX_POD: 8 DC1

BO_ 2358129130 SequContMastSequContClie_TX_FED_RX_CAB: 8 FED

BO_ 2358167786 SequContMastSequContClie_TX_FED_RX_DC1: 8 FED

BO_ 2358176746 SequContMastSequContClie_TX_FED_RX_HAD: 8 FED

BO_ 2358139882 SequContMastSequContClie_TX_FED_RX_POD: 8 FED

BO_ 2358129131 SequContMastSequContClie_TX_HAD_RX_CAB: 8 HAD

BO_ 2358167787 SequContMastSequContClie_TX_HAD_RX_DC1: 8 HAD

BO_ 2358176491 SequContMastSequContClie_TX_HAD_RX_FED: 8 HAD

BO_ 2358139883 SequContMastSequContClie_TX_HAD_RX_POD: 8 HAD

BO_ 2358128987 SequContMastSequContClie_TX_POD_RX_CAB: 8 POD

BO_ 2358167643 SequContMastSequContClie_TX_POD_RX_DC1: 8 POD

BO_ 2358176347 SequContMastSequContClie_TX_POD_RX_FED: 8 POD

BO_ 2358176603 SequContMastSequContClie_TX_POD_RX_HAD: 8 POD

BO_ 2566838833 Software_Identification_CAB: 3 CAB

BO_ 2566838984 Software_Identification_DC1: 3 DC1

BO_ 2566839018 Software_Identification_FED: 3 FED

BO_ 2566839019 Software_Identification_HAD: 3 HAD

BO_ 2566839000 Software_Identification_MTU: 3 MTU

BO_ 2566838875 Software_Identification_POD: 3 POD

BO_ 2662662122 StartRekey_FED: 8 FED

BO_ 2662606570 StartRekey_TX_FED_RX_VTV: 8 FED

BO_ 2662656550 StartRekey_TX_VTV_RX_FED: 8 VTV

BO_ 2662661926 StartRekey_VTV: 8 VTV

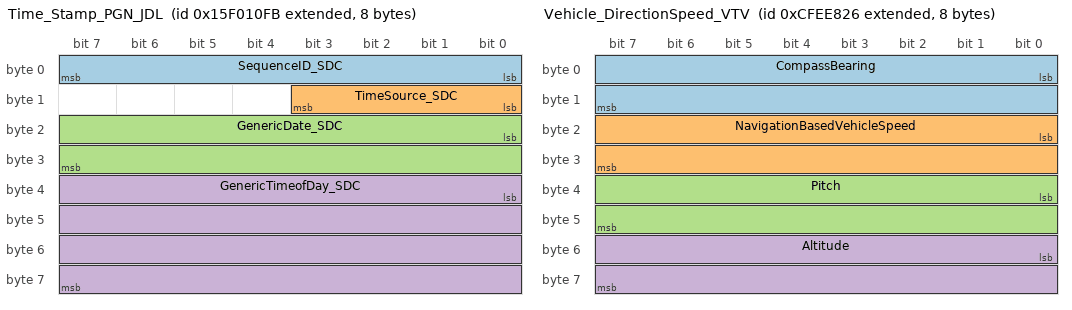
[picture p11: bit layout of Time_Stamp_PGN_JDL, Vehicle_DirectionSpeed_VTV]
BO_ 2515538171 Time_Stamp_PGN_JDL: 8 JDL
 SG_ SequenceID_SDC : 0|8@1+ (1,0) [0|255] "Count"  FED,HAD,POD
 SG_ TimeSource_SDC : 8|4@1+ (1,0) [0|15] ""  FED,HAD,POD
 SG_ GenericDate_SDC : 16|16@1+ (1,0) [0|0] "day"  FED,HAD,POD
 SG_ GenericTimeofDay_SDC : 32|32@1+ (0.0001,0) [0|86401] "s"  FED,HAD,POD

BO_ 2632777521 TranProtConnMana_CAB: 8 CAB

BO_ 2632777672 TranProtConnMana_DC1: 8 DC1

BO_ 2632777706 TranProtConnMana_FED: 8 FED

BO_ 2632777707 TranProtConnMana_HAD: 8 HAD

BO_ 2632777563 TranProtConnMana_POD: 8 POD

BO_ 2632777510 TranProtConnMana_VTV: 8 VTV

BO_ 2632711985 TranProtDataTran_CAB: 8 CAB

BO_ 2632712136 TranProtDataTran_DC1: 8 DC1

BO_ 2632712170 TranProtDataTran_FED: 8 FED

BO_ 2632712171 TranProtDataTran_HAD: 8 HAD

BO_ 2632712027 TranProtDataTran_POD: 8 POD

BO_ 2632711974 TranProtDataTran_VTV: 8 VTV

BO_ 2564549610 UDSFuncRequResp_TX_FED_RX_HAD: 6 FED

BO_ 2564512746 UDSFuncRequResp_TX_FED_RX_POD: 6 FED

BO_ 2564549355 UDSFuncRequResp_TX_HAD_RX_FED: 6 HAD

BO_ 2564512747 UDSFuncRequResp_TX_HAD_RX_POD: 6 HAD

BO_ 2564549211 UDSFuncRequResp_TX_POD_RX_FED: 6 POD

BO_ 2564549467 UDSFuncRequResp_TX_POD_RX_HAD: 6 POD

BO_ 2564554730 UDSFunctionalRequestResponse_FED: 6 FED

BO_ 2564554731 UDSFunctionalRequestResponse_HAD: 6 HAD

BO_ 2564554587 UDSFunctionalRequestResponse_POD: 6 POD

BO_ 2564489194 UDSPhysicalRequestResponse_FED: 6 FED

BO_ 2564489195 UDSPhysicalRequestResponse_HAD: 6 HAD

BO_ 2564489051 UDSPhysicalRequestResponse_POD: 6 POD

BO_ 2564484074 UDSPhysRequResp_TX_FED_RX_HAD: 6 FED

BO_ 2564447210 UDSPhysRequResp_TX_FED_RX_POD: 6 FED

BO_ 2564483819 UDSPhysRequResp_TX_HAD_RX_FED: 6 HAD

BO_ 2564447211 UDSPhysRequResp_TX_HAD_RX_POD: 6 HAD

BO_ 2564483675 UDSPhysRequResp_TX_POD_RX_FED: 6 POD

BO_ 2564483931 UDSPhysRequResp_TX_POD_RX_HAD: 6 POD

BO_ 2365515814 Vehicle_DirectionSpeed_VTV: 8 VTV
 SG_ CompassBearing : 0|16@1+ (0.0078125,0) [0|501.99] "deg"  HAD
 SG_ NavigationBasedVehicleSpeed : 16|16@1+ (0.00390625,0) [0|250.996] "km/h"  Vector__XXX
 SG_ Pitch : 32|16@1+ (0.007813,-200) [-200|301.99] "deg"  Vector__XXX
 SG_ Altitude : 48|16@1+ (0.125,-2500) [-2500|5531.875] ""  Vector__XXX

BO_ 2633952305 Vehicle_Identification_CAB: 1 CAB

BO_ 2633952456 Vehicle_Identification_DC1: 1 DC1

BO_ 2633952490 Vehicle_Identification_FED: 1 FED

BO_ 2633952491 Vehicle_Identification_HAD: 1 HAD

BO_ 2633952347 Vehicle_Identification_POD: 1 POD

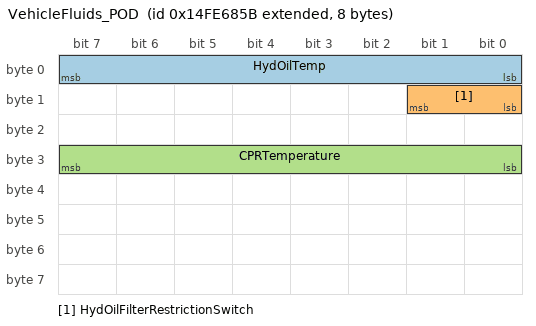
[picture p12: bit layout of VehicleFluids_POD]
BO_ 2499700827 VehicleFluids_POD: 8 POD
 SG_ HydOilTemp : 0|8@1+ (1,-40) [-40|210] "DegCgrd"  FED,HAD,VTV
 SG_ HydOilFilterRestrictionSwitch : 8|2@1+ (1,0) [0|3] ""  Vector__XXX
 SG_ CPRTemperature : 24|8@1+ (1,-40) [-40|210] "DegCgrd"  FED,HAD,VTV

BO_ 2566842161 VehicleHours_CAB: 8 CAB
 SG_ VehHrs : 0|32@1+ (0.05,0) [0|210554060.75] ""  POD

BO_ 2632370225 VirtTermECU_TX_CAB_RX_DC1: 8 CAB

BO_ 2632378929 VirtTermECU_TX_CAB_RX_FED: 8 CAB

BO_ 2632379185 VirtTermECU_TX_CAB_RX_HAD: 8 CAB

BO_ 2632342321 VirtTermECU_TX_CAB_RX_POD: 8 CAB

BO_ 2632331720 VirtTermECU_TX_DC1_RX_CAB: 8 DC1

BO_ 2632379080 VirtTermECU_TX_DC1_RX_FED: 8 DC1

BO_ 2632379336 VirtTermECU_TX_DC1_RX_HAD: 8 DC1

BO_ 2632342472 VirtTermECU_TX_DC1_RX_POD: 8 DC1

BO_ 2632331754 VirtTermECU_TX_FED_RX_CAB: 8 FED

BO_ 2632370410 VirtTermECU_TX_FED_RX_DC1: 8 FED

BO_ 2632379370 VirtTermECU_TX_FED_RX_HAD: 8 FED

BO_ 2632342506 VirtTermECU_TX_FED_RX_POD: 8 FED

BO_ 2632331755 VirtTermECU_TX_HAD_RX_CAB: 8 HAD

BO_ 2632370411 VirtTermECU_TX_HAD_RX_DC1: 8 HAD

BO_ 2632379115 VirtTermECU_TX_HAD_RX_FED: 8 HAD

BO_ 2632342507 VirtTermECU_TX_HAD_RX_POD: 8 HAD

BO_ 2632331611 VirtTermECU_TX_POD_RX_CAB: 8 POD

BO_ 2632370267 VirtTermECU_TX_POD_RX_DC1: 8 POD

BO_ 2632378971 VirtTermECU_TX_POD_RX_FED: 8 POD

BO_ 2632379227 VirtTermECU_TX_POD_RX_HAD: 8 POD

BO_ 2632384305 Virtual_TerminaltoECU_CAB: 8 CAB

BO_ 2632384456 Virtual_TerminaltoECU_DC1: 8 DC1

BO_ 2632384490 Virtual_TerminaltoECU_FED: 8 FED

BO_ 2632384491 Virtual_TerminaltoECU_HAD: 8 HAD

BO_ 2632384347 Virtual_TerminaltoECU_POD: 8 POD

BO_ 2365475070 WheelBasedSpeedandDistance_Vector__XXX: 8 Vector__XXX

BO_ 2566786353 Working_Set_Master_CAB: 8 CAB

BO_ 2566786504 Working_Set_Master_DC1: 8 DC1

BO_ 2566786538 Working_Set_Master_FED: 8 FED

BO_ 2566786539 Working_Set_Master_HAD: 8 HAD

BO_ 2566786395 Working_Set_Master_POD: 8 POD

BO_ 2566786097 Working_Set_Member_CAB: 8 CAB

BO_ 2566786248 Working_Set_Member_DC1: 8 DC1

BO_ 2566786282 Working_Set_Member_FED: 8 FED

BO_ 2566786283 Working_Set_Member_HAD: 8 HAD

BO_ 2566786139 Working_Set_Member_POD: 8 POD

BO_ 2559377386 XCP_Command_Receive_Object_FED: 8 FED
 SG_ CRO_DatParms : 0|64@1+ (1,0) [0|0] ""  HAD,OBT,OBT_FA,POD,XCP,DC1

BO_ 2559377387 XCP_Command_Receive_Object_HAD: 8 HAD
 SG_ CRO_DatParms : 0|64@1+ (1,0) [0|0] ""  FED,OBT,OBT_FA,POD,XCP,DC1

BO_ 2559377401 XCP_Command_Receive_Object_OBT: 8 OBT
 SG_ CRO_DatParms : 0|64@1+ (1,0) [0|0] ""  FED,HAD,OBT_FA,POD,XCP,DC1

BO_ 2559377402 XCP_Command_Receive_Object_OBT_FA: 8 OBT_FA
 SG_ CRO_DatParms : 0|64@1+ (1,0) [0|0] ""  FED,HAD,OBT,POD,XCP,DC1

BO_ 2559377243 XCP_Command_Receive_Object_POD: 8 POD
 SG_ CRO_DatParms : 0|64@1+ (1,0) [0|0] ""  FED,HAD,OBT,OBT_FA,XCP,DC1

BO_ 2559377370 XCP_Command_Receive_Object_XCP: 8 XCP
 SG_ CRO_DatParms : 0|64@1+ (1,0) [0|0] ""  FED,HAD,OBT,OBT_FA,POD,DC1

BO_ 2559311816 XCP_Data_Transmission_Object_DC1: 8 DC1
 SG_ DTO_DatParms : 0|64@1+ (1,0) [0|0] ""  FED,HAD,OBT,OBT_FA,POD,XCP

BO_ 2559311850 XCP_Data_Transmission_Object_FED: 8 FED
 SG_ DTO_DatParms : 0|64@1+ (1,0) [0|0] ""  HAD,OBT,OBT_FA,POD,XCP

BO_ 2559311851 XCP_Data_Transmission_Object_HAD: 8 HAD
 SG_ DTO_DatParms : 0|64@1+ (1,0) [0|0] ""  FED,OBT,OBT_FA,POD,XCP

BO_ 2559311865 XCP_Data_Transmission_Object_OBT: 8 OBT
 SG_ DTO_DatParms : 0|64@1+ (1,0) [0|0] ""  FED,HAD,OBT_FA,POD,XCP

BO_ 2559311866 XCP_Data_Transmission_Object_OBT_FA: 8 OBT_FA
 SG_ DTO_DatParms : 0|64@1+ (1,0) [0|0] ""  FED,HAD,OBT,POD,XCP

BO_ 2559311707 XCP_Data_Transmission_Object_POD: 8 POD
 SG_ DTO_DatParms : 0|64@1+ (1,0) [0|0] ""  FED,HAD,OBT,OBT_FA,XCP

BO_ 2559311834 XCP_Data_Transmission_Object_XCP: 8 XCP
 SG_ DTO_DatParms : 0|64@1+ (1,0) [0|0] ""  FED,HAD,OBT,OBT_FA,POD

BO_ 2559363306 XCPCommReceObje_TX_FED_RX_DC1: 8 FED
 SG_ CRO_DatParms : 0|64@1+ (1,0) [0|0] ""  DC1

BO_ 2559372266 XCPCommReceObje_TX_FED_RX_HAD: 8 FED
 SG_ CRO_DatParms : 0|64@1+ (1,0) [0|0] ""  HAD

BO_ 2559375850 XCPCommReceObje_TX_FED_RX_OBT: 8 FED
 SG_ CRO_DatParms : 0|64@1+ (1,0) [0|0] ""  OBT

BO_ 2559376106 XCPCommReceObje_TX_FED_RX_OBT_FA: 8 FED
 SG_ CRO_DatParms : 0|64@1+ (1,0) [0|0] ""  OBT_FA

BO_ 2559335402 XCPCommReceObje_TX_FED_RX_POD: 8 FED
 SG_ CRO_DatParms : 0|64@1+ (1,0) [0|0] ""  POD

BO_ 2559367914 XCPCommReceObje_TX_FED_RX_XCP: 8 FED
 SG_ CRO_DatParms : 0|64@1+ (1,0) [0|0] ""  XCP

BO_ 2559363307 XCPCommReceObje_TX_HAD_RX_DC1: 8 HAD
 SG_ CRO_DatParms : 0|64@1+ (1,0) [0|0] ""  DC1

BO_ 2559372011 XCPCommReceObje_TX_HAD_RX_FED: 8 HAD
 SG_ CRO_DatParms : 0|64@1+ (1,0) [0|0] ""  FED

BO_ 2559375851 XCPCommReceObje_TX_HAD_RX_OBT: 8 HAD
 SG_ CRO_DatParms : 0|64@1+ (1,0) [0|0] ""  OBT

BO_ 2559376107 XCPCommReceObje_TX_HAD_RX_OBT_FA: 8 HAD
 SG_ CRO_DatParms : 0|64@1+ (1,0) [0|0] ""  OBT_FA

BO_ 2559335403 XCPCommReceObje_TX_HAD_RX_POD: 8 HAD
 SG_ CRO_DatParms : 0|64@1+ (1,0) [0|0] ""  POD

BO_ 2559367915 XCPCommReceObje_TX_HAD_RX_XCP: 8 HAD
 SG_ CRO_DatParms : 0|64@1+ (1,0) [0|0] ""  XCP

BO_ 2559363322 XCPCommReceObje_TX_OBT_FA_RX_DC1: 8 OBT_FA
 SG_ CRO_DatParms : 0|64@1+ (1,0) [0|0] ""  DC1

BO_ 2559372026 XCPCommReceObje_TX_OBT_FA_RX_FED: 8 OBT_FA
 SG_ CRO_DatParms : 0|64@1+ (1,0) [0|0] ""  FED

BO_ 2559372282 XCPCommReceObje_TX_OBT_FA_RX_HAD: 8 OBT_FA
 SG_ CRO_DatParms : 0|64@1+ (1,0) [0|0] ""  HAD

BO_ 2559375866 XCPCommReceObje_TX_OBT_FA_RX_OBT: 8 OBT_FA
 SG_ CRO_DatParms : 0|64@1+ (1,0) [0|0] ""  OBT

BO_ 2559335418 XCPCommReceObje_TX_OBT_FA_RX_POD: 8 OBT_FA
 SG_ CRO_DatParms : 0|64@1+ (1,0) [0|0] ""  POD

BO_ 2559367930 XCPCommReceObje_TX_OBT_FA_RX_XCP: 8 OBT_FA
 SG_ CRO_DatParms : 0|64@1+ (1,0) [0|0] ""  XCP

BO_ 2559363321 XCPCommReceObje_TX_OBT_RX_DC1: 8 OBT
 SG_ CRO_DatParms : 0|64@1+ (1,0) [0|0] ""  DC1

BO_ 2559372025 XCPCommReceObje_TX_OBT_RX_FED: 8 OBT
 SG_ CRO_DatParms : 0|64@1+ (1,0) [0|0] ""  FED

BO_ 2559372281 XCPCommReceObje_TX_OBT_RX_HAD: 8 OBT
 SG_ CRO_DatParms : 0|64@1+ (1,0) [0|0] ""  HAD

BO_ 2559376121 XCPCommReceObje_TX_OBT_RX_OBT_FA: 8 OBT
 SG_ CRO_DatParms : 0|64@1+ (1,0) [0|0] ""  OBT_FA

BO_ 2559335417 XCPCommReceObje_TX_OBT_RX_POD: 8 OBT
 SG_ CRO_DatParms : 0|64@1+ (1,0) [0|0] ""  POD

BO_ 2559367929 XCPCommReceObje_TX_OBT_RX_XCP: 8 OBT
 SG_ CRO_DatParms : 0|64@1+ (1,0) [0|0] ""  XCP

BO_ 2559363163 XCPCommReceObje_TX_POD_RX_DC1: 8 POD
 SG_ CRO_DatParms : 0|64@1+ (1,0) [0|0] ""  DC1

BO_ 2559371867 XCPCommReceObje_TX_POD_RX_FED: 8 POD
 SG_ CRO_DatParms : 0|64@1+ (1,0) [0|0] ""  FED

BO_ 2559372123 XCPCommReceObje_TX_POD_RX_HAD: 8 POD
 SG_ CRO_DatParms : 0|64@1+ (1,0) [0|0] ""  HAD

BO_ 2559375707 XCPCommReceObje_TX_POD_RX_OBT: 8 POD
 SG_ CRO_DatParms : 0|64@1+ (1,0) [0|0] ""  OBT

BO_ 2559375963 XCPCommReceObje_TX_POD_RX_OBT_FA: 8 POD
 SG_ CRO_DatParms : 0|64@1+ (1,0) [0|0] ""  OBT_FA

BO_ 2559367771 XCPCommReceObje_TX_POD_RX_XCP: 8 POD
 SG_ CRO_DatParms : 0|64@1+ (1,0) [0|0] ""  XCP

BO_ 2559363290 XCPCommReceObje_TX_XCP_RX_DC1: 8 XCP
 SG_ CRO_DatParms : 0|64@1+ (1,0) [0|0] ""  DC1

BO_ 2559371994 XCPCommReceObje_TX_XCP_RX_FED: 8 XCP
 SG_ CRO_DatParms : 0|64@1+ (1,0) [0|0] ""  FED

BO_ 2559372250 XCPCommReceObje_TX_XCP_RX_HAD: 8 XCP
 SG_ CRO_DatParms : 0|64@1+ (1,0) [0|0] ""  HAD

BO_ 2559375834 XCPCommReceObje_TX_XCP_RX_OBT: 8 XCP
 SG_ CRO_DatParms : 0|64@1+ (1,0) [0|0] ""  OBT

BO_ 2559376090 XCPCommReceObje_TX_XCP_RX_OBT_FA: 8 XCP
 SG_ CRO_DatParms : 0|64@1+ (1,0) [0|0] ""  OBT_FA

BO_ 2559335386 XCPCommReceObje_TX_XCP_RX_POD: 8 XCP
 SG_ CRO_DatParms : 0|64@1+ (1,0) [0|0] ""  POD

BO_ 2559306440 XCPDataTranObje_TX_DC1_RX_FED: 8 DC1
 SG_ DTO_DatParms : 0|64@1+ (1,0) [0|0] ""  FED

BO_ 2559306696 XCPDataTranObje_TX_DC1_RX_HAD: 8 DC1
 SG_ DTO_DatParms : 0|64@1+ (1,0) [0|0] ""  HAD

BO_ 2559310280 XCPDataTranObje_TX_DC1_RX_OBT: 8 DC1
 SG_ DTO_DatParms : 0|64@1+ (1,0) [0|0] ""  OBT

BO_ 2559310536 XCPDataTranObje_TX_DC1_RX_OBT_FA: 8 DC1
 SG_ DTO_DatParms : 0|64@1+ (1,0) [0|0] ""  OBT_FA

BO_ 2559269832 XCPDataTranObje_TX_DC1_RX_POD: 8 DC1
 SG_ DTO_DatParms : 0|64@1+ (1,0) [0|0] ""  POD

BO_ 2559302344 XCPDataTranObje_TX_DC1_RX_XCP: 8 DC1
 SG_ DTO_DatParms : 0|64@1+ (1,0) [0|0] ""  XCP

BO_ 2559306730 XCPDataTranObje_TX_FED_RX_HAD: 8 FED
 SG_ DTO_DatParms : 0|64@1+ (1,0) [0|0] ""  HAD

BO_ 2559310314 XCPDataTranObje_TX_FED_RX_OBT: 8 FED
 SG_ DTO_DatParms : 0|64@1+ (1,0) [0|0] ""  OBT

BO_ 2559310570 XCPDataTranObje_TX_FED_RX_OBT_FA: 8 FED
 SG_ DTO_DatParms : 0|64@1+ (1,0) [0|0] ""  OBT_FA

BO_ 2559269866 XCPDataTranObje_TX_FED_RX_POD: 8 FED
 SG_ DTO_DatParms : 0|64@1+ (1,0) [0|0] ""  POD

BO_ 2559302378 XCPDataTranObje_TX_FED_RX_XCP: 8 FED
 SG_ DTO_DatParms : 0|64@1+ (1,0) [0|0] ""  XCP

BO_ 2559306475 XCPDataTranObje_TX_HAD_RX_FED: 8 HAD
 SG_ DTO_DatParms : 0|64@1+ (1,0) [0|0] ""  FED

BO_ 2559310315 XCPDataTranObje_TX_HAD_RX_OBT: 8 HAD
 SG_ DTO_DatParms : 0|64@1+ (1,0) [0|0] ""  OBT

BO_ 2559310571 XCPDataTranObje_TX_HAD_RX_OBT_FA: 8 HAD
 SG_ DTO_DatParms : 0|64@1+ (1,0) [0|0] ""  OBT_FA

BO_ 2559269867 XCPDataTranObje_TX_HAD_RX_POD: 8 HAD
 SG_ DTO_DatParms : 0|64@1+ (1,0) [0|0] ""  POD

BO_ 2559302379 XCPDataTranObje_TX_HAD_RX_XCP: 8 HAD
 SG_ DTO_DatParms : 0|64@1+ (1,0) [0|0] ""  XCP

BO_ 2559306490 XCPDataTranObje_TX_OBT_FA_RX_FED: 8 OBT_FA
 SG_ DTO_DatParms : 0|64@1+ (1,0) [0|0] ""  FED

BO_ 2559306746 XCPDataTranObje_TX_OBT_FA_RX_HAD: 8 OBT_FA
 SG_ DTO_DatParms : 0|64@1+ (1,0) [0|0] ""  HAD

BO_ 2559310330 XCPDataTranObje_TX_OBT_FA_RX_OBT: 8 OBT_FA
 SG_ DTO_DatParms : 0|64@1+ (1,0) [0|0] ""  OBT

BO_ 2559269882 XCPDataTranObje_TX_OBT_FA_RX_POD: 8 OBT_FA
 SG_ DTO_DatParms : 0|64@1+ (1,0) [0|0] ""  POD

BO_ 2559302394 XCPDataTranObje_TX_OBT_FA_RX_XCP: 8 OBT_FA
 SG_ DTO_DatParms : 0|64@1+ (1,0) [0|0] ""  XCP

BO_ 2559306489 XCPDataTranObje_TX_OBT_RX_FED: 8 OBT
 SG_ DTO_DatParms : 0|64@1+ (1,0) [0|0] ""  FED

BO_ 2559306745 XCPDataTranObje_TX_OBT_RX_HAD: 8 OBT
 SG_ DTO_DatParms : 0|64@1+ (1,0) [0|0] ""  HAD

BO_ 2559310585 XCPDataTranObje_TX_OBT_RX_OBT_FA: 8 OBT
 SG_ DTO_DatParms : 0|64@1+ (1,0) [0|0] ""  OBT_FA

BO_ 2559269881 XCPDataTranObje_TX_OBT_RX_POD: 8 OBT
 SG_ DTO_DatParms : 0|64@1+ (1,0) [0|0] ""  POD

BO_ 2559302393 XCPDataTranObje_TX_OBT_RX_XCP: 8 OBT
 SG_ DTO_DatParms : 0|64@1+ (1,0) [0|0] ""  XCP

BO_ 2559306331 XCPDataTranObje_TX_POD_RX_FED: 8 POD
 SG_ DTO_DatParms : 0|64@1+ (1,0) [0|0] ""  FED

BO_ 2559306587 XCPDataTranObje_TX_POD_RX_HAD: 8 POD
 SG_ DTO_DatParms : 0|64@1+ (1,0) [0|0] ""  HAD

BO_ 2559310171 XCPDataTranObje_TX_POD_RX_OBT: 8 POD
 SG_ DTO_DatParms : 0|64@1+ (1,0) [0|0] ""  OBT

BO_ 2559310427 XCPDataTranObje_TX_POD_RX_OBT_FA: 8 POD
 SG_ DTO_DatParms : 0|64@1+ (1,0) [0|0] ""  OBT_FA

BO_ 2559302235 XCPDataTranObje_TX_POD_RX_XCP: 8 POD
 SG_ DTO_DatParms : 0|64@1+ (1,0) [0|0] ""  XCP

BO_ 2559306458 XCPDataTranObje_TX_XCP_RX_FED: 8 XCP
 SG_ DTO_DatParms : 0|64@1+ (1,0) [0|0] ""  FED

BO_ 2559306714 XCPDataTranObje_TX_XCP_RX_HAD: 8 XCP
 SG_ DTO_DatParms : 0|64@1+ (1,0) [0|0] ""  HAD

BO_ 2559310298 XCPDataTranObje_TX_XCP_RX_OBT: 8 XCP
 SG_ DTO_DatParms : 0|64@1+ (1,0) [0|0] ""  OBT

BO_ 2559310554 XCPDataTranObje_TX_XCP_RX_OBT_FA: 8 XCP
 SG_ DTO_DatParms : 0|64@1+ (1,0) [0|0] ""  OBT_FA

BO_ 2559269850 XCPDataTranObje_TX_XCP_RX_POD: 8 XCP
 SG_ DTO_DatParms : 0|64@1+ (1,0) [0|0] ""  POD

BO_ 2566912766 Mx_FFFA_P6_0xFE: 8 Vector__XXX
 SG_ CmdBytePGN65530_Vector_XXX M : 0|16@1+ (1,0) [0|0] ""  JDL
 SG_ AcceleratedDOCInletTemperature m329 : 16|16@1+ (0.03125,-50) [-50|1997.9688] ""  JDL
 SG_ AcceleratedDOCOutletTemperature m329 : 32|16@1+ (0.03125,-50) [-50|1997.9688] ""  JDL
 SG_ AcceleratedSCRInletTemperature m329 : 48|16@1+ (0.03125,-50) [-50|1997.9688] ""  JDL
 SG_ AcceleratedDPFOutletNOx m585 : 16|16@1+ (0.03125,0) [0|2047.031] ""  JDL
 SG_ AcceleratedSCROutletNOx m585 : 32|16@1+ (0.03125,0) [0|2047.031] ""  JDL
 SG_ SCRWarmUpRequestedTimer m585 : 48|16@1+ (0.03125,0) [0|2047.031] ""  JDL
 SG_ CurrentNumberofStarts m17153 : 16|16@1+ (1,1) [0|65535] ""  JDL
 SG_ DesiredFuel m17153 : 32|16@1+ (0.0625,0) [0|4095.9375] ""  JDL
 SG_ EngineOperatingCondition m17153 : 48|8@1+ (1,1) [0|255] ""  JDL
 SG_ DEFFlowRate m17153 : 56|8@1+ (0.03125,0) [0|7.96875] ""  JDL
 SG_ DPFDeltaPressure m17409 : 16|16@1+ (0.125,0) [0|4095.9375] ""  JDL
 SG_ FiltNormDPFDeltPresAfteActiRege m17409 : 32|8@1+ (0.125,0) [0|31.875] ""  JDL
 SG_ SCRAdapContAdjuFact m17409 : 40|8@1+ (0.015625,0) [0|3.984375] ""  JDL
 SG_ MaximumAllowedNH3FlowRate m17409 : 48|16@1+ (0.0078125,0) [0|511.9922] ""  JDL
 SG_ CharAirCoolEffeLongTermCorrFact m20483 : 16|8@1+ (0.015625,0) [0|3.984375] ""  JDL
 SG_ CompInlePresCorrFact m20483 : 24|8@1+ (0.015625,0) [0|3.984375] ""  JDL
 SG_ EGRCoolEffeLongTermCorrFact m20483 : 32|8@1+ (0.015625,0) [0|3.984375] ""  JDL
 SG_ VTGPosiLongTermCorrOffs m20483 : 40|8@1+ (0.015625,0) [0|3.984375] ""  JDL
 SG_ RailPCtrlClsdLoopCmd m20483 : 48|16@1- (0.015625,-500) [-500|-523.9843] ""  JDL
 SG_ IntaManiTempSensEstiUnco m20739 : 16|8@1+ (1,-40) [-40|215] ""  JDL
 SG_ CharAirCoolOutlTempSensEstiUnco m20739 : 24|8@1+ (1,-40) [-40|215] ""  JDL
 SG_ EGRCoolOutlTempSensEstiUnco m20739 : 32|8@1+ (2,-40) [-40|470] ""  JDL
 SG_ EGRGasTemperatureSensor m20739 : 40|8@1+ (2,-40) [-40|470] ""  JDL
 SG_ IntaManiPresEstiUnco m20995 : 16|16@1+ (0.015625,0) [0|1023.94375] ""  JDL
 SG_ ExhaManiPresSensEstiUnco m20995 : 32|8@1+ (3,0) [0|765] ""  JDL
 SG_ ExhaManiPresSensRead m20995 : 40|8@1+ (3,0) [0|765] ""  JDL
 SG_ CompInteTempSensEstiUnco m21507 : 16|8@1+ (2,-50) [0|450] ""  JDL
 SG_ InteCompOutlTempSensRead m21507 : 24|8@1+ (2,-50) [0|450] ""  JDL
 SG_ CylinderPressurePeak m21507 : 32|16@1+ (1,0) [0|65535] ""  JDL
 SG_ ExhaManiTempTherEsti m21507 : 48|16@1+ (0.03125,0) [0|2047.96875] ""  JDL

BO_ 2298478129 Mx_FFFE_P2_0x31: 8 CAB
 SG_ CmdBytePGN65534_CAB M : 0|8@1+ (1,0) [0|0] ""  POD,FED,PDU
 SG_ ACCompressorRequest m5 : 8|2@1+ (1,0) [0|3] ""  POD
 SG_ OptrCtrlEncdrInc m253 : 8|8@1+ (1,0) [0|250] ""  FED
 SG_ OptrCtrlEncdrDec m253 : 16|8@1+ (1,0) [0|250] ""  FED
 SG_ OptrCtrlEncdr2Inc m253 : 24|8@1+ (1,0) [0|250] ""  FED,PDU
 SG_ OptrCtrlEncdr2Dec m253 : 32|8@1+ (1,0) [0|250] ""  FED,PDU

BO_ 2566912038 Mx_FFF8_P6_0x26: 8 VTV
 SG_ CmdBytePGN65528_VTV M : 0|8@1+ (1,0) [0|0] ""  HAD,JDL
 SG_ FlowIndicator m106 : 8|8@1+ (1,0) [0|0] "count"  Vector__XXX
 SG_ Flow1PTW m106 : 16|8@1+ (1,0) [0|0] "count"  Vector__XXX
 SG_ Flow2PTW m106 : 24|8@1+ (1,0) [0|0] "count"  Vector__XXX
 SG_ Flow3PTW m106 : 32|8@1+ (1,0) [0|0] "count"  Vector__XXX
 SG_ Flow4PTW m106 : 40|8@1+ (1,0) [0|0] "count"  Vector__XXX
 SG_ Flow5PTW m106 : 48|8@1+ (1,0) [0|0] "count"  Vector__XXX
 SG_ ActiveYieldState m106 : 56|4@1+ (1,0) [0|15] ""  Vector__XXX
 SG_ PartialTankWeightState m106 : 60|4@1+ (1,0) [0|0] "count"  Vector__XXX
 SG_ TailBypaPercCleaGraiFilt1 m198 : 24|16@1+ (0.002,0) [0|100] "%"  JDL
 SG_ TailBypaPercCleaGraiFilt2 m198 : 40|16@1+ (0.002,0) [0|100] "%"  JDL
 SG_ IPMOperationalStatus m202 : 44|4@1+ (1,0) [0|15] ""  Vector__XXX
 SG_ GQMReportingState m202 : 48|2@1+ (1,0) [0|3] ""  HAD
 SG_ CleanGrainCameraUnavailable m202 : 50|2@1+ (1,0) [0|3] ""  Vector__XXX
 SG_ CleanGrainCameraHardware m202 : 56|2@1+ (1,0) [0|3] ""  Vector__XXX

BO_ 2634021630 Mx_FFFA_P7_0xFE: 8 Vector__XXX
 SG_ CmdBytePGN65530_Vector_XXX M : 0|16@1+ (1,0) [0|0] ""  JDL
 SG_ ExhaManiPresSensFiltOffs m21251 : 16|8@1+ (0.125,-15) [-15|16.875] ""  JDL
 SG_ CompressorFlowCorrectionFactor m21251 : 24|8@1+ (0.015625,0) [0|3.984375] ""  JDL
 SG_ WastMassFlowLongTermCorrFact m21251 : 32|8@1+ (1,0) [0|3.984375] ""  JDL
 SG_ ExhaThroPosiLongTermCorrOffs m21251 : 40|8@1+ (0.003906,-0.5) [-0.5|0.49609375] ""  JDL
 SG_ AECDActiveStatusAll m21251 : 48|8@1+ (1,0) [0|255] ""  JDL
 SG_ WastActuPresLongTermCorrOf m21251 : 56|8@1+ (1,-70) [-70|185] ""  JDL
 SG_ IntaManiTempEGRFlowCorrStat m21763 : 16|8@1+ (1,0) [0|6] ""  JDL
 SG_ AirModeAirThrottleMode m21763 : 24|8@1+ (1,0) [0|31] ""  JDL
 SG_ AirSystObseInpuConfLeve m21763 : 32|8@1+ (1,0) [0|2] ""  JDL
 SG_ NOxBasedEGRFlowCorrectionState m21763 : 40|8@1+ (1,0) [0|6] ""  JDL
 SG_ EGRFlowCorrectionActionRequest m21763 : 48|8@1+ (1,0) [0|6] ""  JDL
 SG_ AirModeEGRValveMode m22019 : 16|8@1+ (1,0) [0|31] ""  JDL
 SG_ AirModeWastegateSolenoidMode m22019 : 24|8@1+ (1,0) [0|31] ""  JDL
 SG_ AirModeExhaustThrottleMode m22019 : 32|8@1+ (1,0) [0|31] ""  JDL
 SG_ AirModeVTGMode m22019 : 40|8@1+ (1,0) [0|31] ""  JDL
 SG_ CharAirCoolMassFlowLongTermCorrFact m22275 : 16|8@1+ (1,0) [0|3.984375] ""  JDL
 SG_ EGRFlowCorrFactLongTermCorrOffs m22275 : 24|8@1+ (1,0) [0|3.984375] ""  JDL
 SG_ EGRFlowCorrectionFactor m22275 : 32|8@1+ (0.007813,0) [0|1.992188] ""  JDL
 SG_ TurbMapMassFlowLongTermCorrFact m22275 : 40|8@1+ (0.015625,0) [0|3.984375] ""  JDL
 SG_ AirThroPosiLongTermCorrOffs m22275 : 48|8@1+ (0.003906,-0.1) [0|0] ""  JDL
 SG_ EGRValvPosiLongTermCorrOffs m22275 : 56|8@1+ (0.003906,-0.1) [0|0] ""  JDL

BO_ 2365587454 AdvaGuidStatResp_Vector__XXX: 8 Vector__XXX
 SG_ CmdBytePGN65535_Vector_XXX M : 0|8@1+ (1,0) [0|0] ""  VTV
 SG_ AutoTracWheelbase_AGSR m147 : 8|8@1+ (0.05,0) [0|12.5] "m"  VTV
 SG_ AutoTracSysCtlrLoSpdLim m147 : 16|8@1+ (0.00390625,0) [0|0.9765625] "km/h"  VTV
 SG_ AutoTracSysCtlrUpSpdLim m147 : 24|8@1+ (0.5,0) [0|125] "km/h"  VTV
 SG_ AutoTracSysCtlrUnlimitRevCapable m147 : 32|2@1+ (1,0) [0|3] ""  VTV
 SG_ AuxResuCap m147 : 34|2@1+ (1,0) [0|3] ""  VTV
 SG_ WASType m147 : 36|4@1+ (1,0) [0|15] ""  VTV
 SG_ MaxReverseSpeed m147 : 40|8@1+ (0.5,0) [0|125] "km/h"  VTV
 SG_ ConfigMachineClass m147 : 48|5@1+ (1,0) [0|31] ""  VTV
 SG_ SIDType m147 : 53|3@1+ (1,0) [0|7] ""  VTV
 SG_ ActuatorType m147 : 56|3@1+ (1,0) [0|7] ""  VTV
 SG_ StarfireFwdCfg_AGSR m147 : 59|3@1+ (1,0) [0|7] ""  VTV

BO_ 2432696113 Mx_FFFF_P4_0x31: 8 CAB
 SG_ CmdBytePGN65535_CAB M : 0|8@1+ (1,0) [0|0] ""  FED,HAD,POD,VTV
 SG_ QuickStopSwitch m6 : 62|2@1+ (1,0) [0|3] ""  FED,HAD,POD,VTV
 SG_ OperatorSeatSwitch m236 : 40|2@1+ (1,0) [0|3] ""  FED,HAD,POD,VTV

BO_ 2566913841 ArmrestControlUnitStatus2_CAB: 8 CAB
 SG_ CmdBytePGN65535_CAB M : 0|8@1+ (1,0) [0|0] ""  HAD
 SG_ WasherPumpCmdFrnt m135 : 16|2@1+ (1,0) [0|3] ""  HAD
 SG_ WasherPumpCmdRight m135 : 20|2@1+ (1,0) [0|3] ""  HAD

BO_ 2566912561 Mx_FFFA_P6_0x31: 8 CAB
 SG_ CmdBytePGN65530_CAB M : 0|16@1+ (1,0) [0|0] ""  HAD,VTV,FED,POD
 SG_ WorkLight1LeftCmd m28673 : 16|2@1+ (1,0) [0|3] ""  Vector__XXX
 SG_ WorkLight4LeftCmd m28673 : 22|2@1+ (1,0) [0|3] ""  FED,HAD
 SG_ WorkLight9LeftCmd m28673 : 32|2@1+ (1,0) [0|3] ""  Vector__XXX
 SG_ WorkLight10LeftCmd m28673 : 34|2@1+ (1,0) [0|3] ""  HAD
 SG_ WorkLight13LeftCmd m28673 : 40|2@1+ (1,0) [0|3] ""  POD
 SG_ WorkLight22LeftCmd m28673 : 58|2@1+ (1,0) [0|3] ""  HAD
 SG_ WorkLight1RightCmd m28929 : 16|2@1+ (1,0) [0|3] ""  Vector__XXX
 SG_ WorkLight4RightCmd m28929 : 22|2@1+ (1,0) [0|3] ""  FED,HAD
 SG_ WorkLight9RightCmd m28929 : 32|2@1+ (1,0) [0|3] ""  Vector__XXX
 SG_ WorkLight10RightCmd m28929 : 34|2@1+ (1,0) [0|3] ""  HAD
 SG_ WorkLight13RightCmd m28929 : 40|2@1+ (1,0) [0|3] ""  POD
 SG_ WorkLight19RightCmd m28929 : 52|2@1+ (1,0) [0|3] ""  HAD
 SG_ WorkLight20RightCmd m28929 : 54|2@1+ (1,0) [0|3] ""  HAD
 SG_ WorkLight21RightCmd m28929 : 56|2@1+ (1,0) [0|3] ""  FED
 SG_ WorkLight22RightCmd m28929 : 58|2@1+ (1,0) [0|3] ""  HAD
 SG_ FrshAirIntTempAct m38914 : 40|8@1+ (0.5,-10) [-10|105] "DegCgrd"  HAD,VTV

BO_ 2634021118 ATNOxCEStatistics_Vector__XXX: 8 Vector__XXX
 SG_ CmdBytePGN65528_Vector_XXX M : 0|8@1+ (1,0) [0|0] ""  JDL
 SG_ AftrtrtmntSCRObsNOxCnvrsnEff m150 : 8|16@1+ (1,0) [0|5] ""  JDL
 SG_ AftrtrtmntOutNOxTailCnt m150 : 24|16@1+ (1,0) [0|5] ""  JDL
 SG_ SCRNOXCEMonState m150 : 42|2@1+ (1,0) [0|3] ""  JDL
 SG_ SCRAdapConDisable m150 : 44|2@1+ (1,0) [0|3] ""  JDL
 SG_ SCRAdapConAdjFactor m150 : 48|16@1+ (1,-32768) [-32768|32767] ""  JDL

BO_ 2499803902 Mx_FFFA_P5_0xFE: 8 Vector__XXX
 SG_ CmdBytePGN65530_Vector_XXX M : 0|16@1+ (1,0) [0|0] ""  CAB,OBT,VTV,JDL
 SG_ RawMedianVoltage m514 : 16|16@1+ (0.0001,-1) [-1|5] ""  JDL
 SG_ RawMeanVoltage m514 : 32|16@1+ (0.0001,-1) [-1|5] ""  JDL
 SG_ RawSupplyVoltage m514 : 48|16@1+ (0.0001,-1) [-1|5] ""  JDL
 SG_ PTWEstimatedWeight m770 : 16|16@1+ (0.25,0) [0|16384] "kg"  JDL
 SG_ ActiveYieldWeight m770 : 32|16@1+ (0.25,0) [0|16384] "kg"  JDL
 SG_ ManualCalWeight m770 : 48|16@1+ (0.25,0) [0|16384] "kg"  JDL
 SG_ ForeMateRelaDispValu m1286 : 16|16@1+ (0.01,0) [0|200] ""  JDL
 SG_ BrokGraiRelaDispValu m1286 : 32|16@1+ (0.01,0) [0|200] ""  JDL
 SG_ IC2SeveritySeparatorLoss m1542 : 16|16@1+ (0.001,-32) [-32|33.535] ""  JDL
 SG_ IC2SeverityShoeLoss m1542 : 32|16@1+ (0.001,-32) [-32|33.535] ""  JDL
 SG_ IC2SeverityDamagedGrain m1542 : 48|16@1+ (0.001,-32) [-32|33.535] ""  JDL
 SG_ IC2SeverityMOGLight m1798 : 16|16@1+ (0.001,-32) [-32|33.535] ""  JDL
 SG_ IC2SeverityMOGHeavy m1798 : 32|16@1+ (0.001,-32) [-32|33.535] ""  JDL
 SG_ IC2SeverityUnthrGrain m1798 : 48|16@1+ (0.001,-32) [-32|33.535] ""  JDL
 SG_ LeftAttaFramPresSens m1799 : 16|16@1+ (1,0) [0|65535] ""  CAB,OBT
 SG_ RighAttaFramPresSens m1799 : 32|16@1+ (1,0) [0|65535] ""  CAB,OBT
 SG_ AttachmentFrameServiceStatus m1799 : 48|4@1+ (1,0) [0|15] ""  CAB,OBT
 SG_ IC2SeverityMassflow m2054 : 16|16@1+ (0.001,-32) [-32|33.535] ""  JDL
 SG_ SOExhaustedStateModel m2054 : 32|4@1+ (1,0) [0|15] ""  JDL
 SG_ SOStableStatus m2054 : 36|4@1+ (1,0) [0|15] ""  JDL
 SG_ LeftWingPressureSensor m2055 : 16|16@1+ (1,0) [0|65535] ""  CAB,OBT
 SG_ RightWingPressureSensor m2055 : 32|16@1+ (1,0) [0|65535] ""  CAB,OBT
 SG_ LeftWingServiceStatus m2055 : 48|4@1+ (1,0) [0|15] ""  CAB,OBT
 SG_ RightWingServiceStatus m2055 : 52|4@1+ (1,0) [0|15] ""  CAB,OBT
 SG_ Filter1MOGLightAdjusted m2310 : 16|16@1+ (0.002,0) [0|100] ""  JDL
 SG_ Filter1MOGHeavyAdjusted m2310 : 32|16@1+ (0.002,0) [0|100] ""  JDL
 SG_ Filter1UnthreshedAdjusted m2310 : 48|16@1+ (0.002,0) [0|100] ""  JDL
 SG_ ManualCalFactorInUse m2818 : 32|16@1+ (0.01,0) [0|655.35] "kg/V"  JDL
 SG_ ActiveYieldCalFactorInUse m2818 : 48|16@1+ (0.01,0) [0|655.35] "kg/V"  JDL
 SG_ SOAutoAdjustEnabled_CleaningFan m4102 : 16|4@1+ (1,0) [0|15] ""  JDL
 SG_ SOAutoAdjuEnabSievClea m4102 : 20|4@1+ (1,0) [0|15] ""  JDL
 SG_ SOAutoAdjuEnabChafClea m4102 : 24|4@1+ (1,0) [0|15] ""  JDL
 SG_ SOAutoAdjuEnabThreClea m4102 : 28|4@1+ (1,0) [0|15] ""  JDL
 SG_ SOAutoAdjuEnabThreSpee m4102 : 32|4@1+ (1,0) [0|15] ""  JDL
 SG_ ReelCenterTubeFLPSysHealth m13057 : 48|4@1+ (1,0) [0|15] ""  JDL
 SG_ NmbrCalLoads m16131 : 16|4@1+ (1,0) [0|15] ""  JDL
 SG_ MsgSeqIndex m16131 : 20|4@1+ (1,0) [0|15] ""  JDL
 SG_ CalLoadDesignator m16131 : 24|4@1+ (1,0) [0|15] ""  JDL
 SG_ CalLoadSelected m16131 : 28|2@1+ (1,0) [0|3] ""  JDL
 SG_ YldMonForceSum m16131 : 32|16@1+ (0.01,0) [0|655.35] "V"  JDL
 SG_ YldMonDeltaT m16131 : 48|16@1+ (0.1,0) [0|6553.5] "s"  JDL
 SG_ AutoDeckplateEnable m21505 : 20|4@1+ (1,0) [0|15] ""  VTV
 SG_ AutoDeckplateCmdFromHCU m21505 : 24|2@1+ (1,0) [0|3] ""  VTV
 SG_ HdrAutomationFeaturesStatus m21505 : 28|4@1+ (1,0) [0|15] ""  VTV
 SG_ AutoDeckPlatTighLeveFromHCU m21505 : 32|4@1+ (1,0) [0|15] ""  VTV
 SG_ AutoDeckPlateOptionInstalled m21505 : 36|2@1+ (1,0) [0|3] ""  VTV
 SG_ ForeignMaterialLimitData m30976 : 16|16@1+ (0.1,0) [0|100] ""  JDL
 SG_ BrokenGrainLimitData m30976 : 32|16@1+ (0.1,0) [0|100] ""  JDL
 SG_ GrainLossRelativeDisplayedTotal m30976 : 48|16@1+ (0.01,0) [0|200] ""  JDL
 SG_ TotalGrainLossAreaDefinedLimit m31232 : 16|16@1+ (0.0008,0) [0|51.404] ""  JDL
 SG_ TotalGrainLossAreaFilter1 m31232 : 32|16@1+ (0.0008,0) [0|51.404] ""  JDL
 SG_ TotalGrainLossMassDefinedLimit m31488 : 16|16@1+ (0.0008,0) [0|51.404] ""  JDL
 SG_ TotalGrainLossMassFilter1 m31488 : 32|16@1+ (0.0008,0) [0|51.404] ""  JDL
 SG_ SDAStatusLED_GSA_Sense m34560 : 16|4@1+ (1,0) [0|15] ""  JDL
 SG_ SDAStatusLED_GSA_Decide m34560 : 20|4@1+ (1,0) [0|15] ""  JDL
 SG_ SDAStatusLED_GSA_Act m34560 : 24|4@1+ (1,0) [0|15] ""  JDL
 SG_ SDAStatusLED_HSA_Sense m34560 : 28|4@1+ (1,0) [0|15] ""  JDL
 SG_ SDAStatusLED_HSA_Decide m34560 : 32|4@1+ (1,0) [0|15] ""  JDL
 SG_ SDAStatusLED_HSA_Act m34560 : 36|4@1+ (1,0) [0|15] ""  JDL
 SG_ SDAStatusLED_TSA_Sense m34816 : 16|4@1+ (1,0) [0|15] ""  JDL
 SG_ SDAStatusLED_TSA_Decide m34816 : 20|4@1+ (1,0) [0|15] ""  JDL
 SG_ SDAStatusLED_TSA_Act m34816 : 24|4@1+ (1,0) [0|15] ""  JDL
 SG_ ThreshingConditionModifier m36610 : 16|4@1+ (1,0) [0|15] ""  JDL
 SG_ StrawConditionModifier m36610 : 20|4@1+ (1,0) [0|15] ""  JDL

CM_ "DBC file created from Harvester_Combine_Mercury_MY25_CAN.csv with CAN2DBC 4.5.1 on NoDate";
CM_ BO_ 2566912766 "AcceleratedDOCSCRTemperatures; AcceleratedDPFSCROutletNOx; AirSystemObserverCorrectionFactors1; AirSystemObserverPlausibility1; AirSystemObserverPlausibility2; EngineTemperaturesAndPressures; MTGAftertreatmentControl1; MTGEngineConsumptionAndOperation";
CM_ BO_ 2298478129 "ACsystem; OperatorControlsEncoders";
CM_ BO_ 2566912038 "Active_Yield_Assist_Status; Grain_Quality_Diagnostic_Information_1; TailingsBypassCleanGrainInformation1";
CM_ BO_ 2634021630 "ActuatorAirModes; AirSystemStates; AirSystemObserverCorrectionFactors2; AirSystemObserverCorrectionFactors3";
CM_ BO_ 2365587454 "Advanced_Guidance_Status_Response";
CM_ BO_ 2432696113 "ArmrestCoverMatrixInputs1Combine; OperatorSeatData";
CM_ BO_ 2566913841 "ArmrestControlUnitStatus2";
CM_ BO_ 2566912561 "ATCSystemTemperatures1; JD_Configurable_Lighting_Command_Left_Hand_Work_Lights; JD_Configurable_Lighting_Command_Right_Hand_Work_Lights";
CM_ BO_ 2634021118 "ATNOxCEStatistics";
CM_ BO_ 2499803902 "AttachmentFramePressureSensors; AutoDeckPlateParameters3; Calibration_Load_Information_4; Estimated_Harvested_Weight; Filter1MOGAdjusted; GrainLossAreaInformation; GrainLossMassInformation; HarvestMetrics1; HarvestMetrics2; HSAAutoAdjustEnableStatus; HSAConditionModifiers; HSASeverity; HSASeverity2; PerceptionSystemStatus; SDAStatusLED1; SDAStatusLED2; SODataMessage; WingPressureSensors; Yield_Calibration_Factor; Yield_Monitoring_System_Information";
BA_DEF_ SG_ "SigType" ENUM "Default", "Range", "RangeSigned", "ASCII", "Discrete", "Control", "ReferencePGN", "DTC", "StringDelimiter", "StringLength", "StringLengthControl", "MessageCounter", "MessageChecksum";
BA_DEF_ SG_ "GenSigSendType" ENUM "Cyclic", "OnWrite", "OnWriteWithRepetition", "OnChange", "OnChangeWithRepetition", "IfActive", "IfActiveWithRepetition", "NoSigSendType";
BA_DEF_ SG_ "GenSigTimeoutTime_ECU" INT 0 3600000;
BA_DEF_ SG_ "GenSigILSupport" ENUM "Yes", "No";
BA_DEF_ SG_ "GenSigEVName" STRING ;
BA_DEF_ BO_ "GenMsgILSupport" ENUM "Yes", "No";
BA_DEF_ BO_ "GenMsgSendType" ENUM "cyclic", "reserved", "cyclicIfActive", "reserved", "reserved", "reserved", "reserved", "reserved", "NoMsgSendType";
BA_DEF_ BO_ "VFrameFormat" ENUM "StandardCAN", "ExtendedCAN", "reserved", "J1939PG";
BA_DEF_ BO_ "SingleFrame" INT 0 1;
BA_DEF_ BO_ "GenMsgCycleTime" INT 0 3600000;
BA_DEF_ BO_ "GenMsgCycleTimeFast" INT 0 3600000;
BA_DEF_ BU_ "NmStationAddress" INT 0 255;
BA_DEF_ BU_ "NmJ1939AAC" INT 0 1;
BA_DEF_ BU_ "NmJ1939IndustryGroup" INT 0 7;
BA_DEF_ BU_ "NmJ1939System" INT 0 127;
BA_DEF_ BU_ "NmJ1939SystemInstance" INT 0 15;
BA_DEF_ BU_ "NmJ1939Function" INT 0 255;
BA_DEF_ BU_ "NmJ1939FunctionInstance" INT 0 7;
BA_DEF_ BU_ "NmJ1939ECUInstance" INT 0 3;
BA_DEF_ BU_ "NmJ1939ManufacturerCode" INT 0 2047;
BA_DEF_ BU_ "NmJ1939IdentityNumber" INT 0 2097151;
BA_DEF_ BU_ "ECU" STRING ;
BA_DEF_ BU_ "AddressClaimSimulated" ENUM "no", "yes";
BA_DEF_  "DBName" STRING ;
BA_DEF_  "DatabaseVersion" STRING ;
BA_DEF_  "Baudrate" INT 100000 1000000;
BA_DEF_  "BusType" STRING ;
BA_DEF_  "ProtocolType" STRING ;
BA_DEF_  "SAE_J1939_75_SpecVersion" STRING ;
BA_DEF_  "SAE_J1939_21_SpecVersion" STRING ;
BA_DEF_  "SAE_J1939_73_SpecVersion" STRING ;
BA_DEF_  "SAE_J1939_71_SpecVersion" STRING ;
BA_DEF_DEF_ "SigType" "Default";
BA_DEF_DEF_ "GenSigSendType" "NoSigSendType";
BA_DEF_DEF_ "GenSigTimeoutTime_ECU" 0;
BA_DEF_DEF_ "GenSigILSupport" "Yes";
BA_DEF_DEF_ "GenSigEVName" "Env@Nodename_@Signame";
BA_DEF_DEF_ "GenMsgILSupport" "Yes";
BA_DEF_DEF_ "GenMsgSendType" "NoMsgSendType";
BA_DEF_DEF_ "VFrameFormat" "J1939PG";
BA_DEF_DEF_ "SingleFrame" 0;
BA_DEF_DEF_ "GenMsgCycleTime" 0;
BA_DEF_DEF_ "GenMsgCycleTimeFast" 0;
BA_DEF_DEF_ "NmStationAddress" 254;
BA_DEF_DEF_ "NmJ1939AAC" 0;
BA_DEF_DEF_ "NmJ1939IndustryGroup" 0;
BA_DEF_DEF_ "NmJ1939System" 0;
BA_DEF_DEF_ "NmJ1939SystemInstance" 0;
BA_DEF_DEF_ "NmJ1939Function" 0;
BA_DEF_DEF_ "NmJ1939FunctionInstance" 0;
BA_DEF_DEF_ "NmJ1939ECUInstance" 0;
BA_DEF_DEF_ "NmJ1939ManufacturerCode" 0;
BA_DEF_DEF_ "NmJ1939IdentityNumber" 0;
BA_DEF_DEF_ "ECU" "";
BA_DEF_DEF_ "AddressClaimSimulated" "no";
BA_DEF_DEF_ "DBName" "J1939Network";
BA_DEF_DEF_ "DatabaseVersion" "";
BA_DEF_DEF_ "Baudrate" 500000;
BA_DEF_DEF_ "BusType" "CAN";
BA_DEF_DEF_ "ProtocolType" "J1939";
BA_DEF_DEF_ "SAE_J1939_75_SpecVersion" "";
BA_DEF_DEF_ "SAE_J1939_21_SpecVersion" "";
BA_DEF_DEF_ "SAE_J1939_73_SpecVersion" "";
BA_DEF_DEF_ "SAE_J1939_71_SpecVersion" "";
BA_ "GenSigTimeoutTime_ECU" SG_ 2566757374 AftrtrtmntDEFConc 5000;
BA_ "GenSigSendType" SG_ 2566757374 AftrtrtmntDEFConc 0;
BA_ "GenSigTimeoutTime_ECU" SG_ 2566757374 AftrtrtmntDEFProp 5000;
BA_ "GenSigSendType" SG_ 2566757374 AftrtrtmntDEFProp 0;
BA_ "GenSigTimeoutTime_ECU" SG_ 2566805246 AftrtrtmntDEFTankTemp 5000;
BA_ "GenSigSendType" SG_ 2566805246 AftrtrtmntDEFTankTemp 0;
BA_ "GenSigTimeoutTime_ECU" SG_ 2566805246 AftrtrtmntSCROptrIndcmntSevrty 5000;
BA_ "GenSigSendType" SG_ 2566805246 AftrtrtmntSCROptrIndcmntSevrty 0;
BA_ "GenSigTimeoutTime_ECU" SG_ 2566805246 AftrtrtmntDEFTankLvl 5000;
BA_ "GenSigSendType" SG_ 2566805246 AftrtrtmntDEFTankLvl 0;
BA_ "GenSigTimeoutTime_ECU" SG_ 2566805246 AftrtrtmntDEFTankLoLvlInd 5000;
BA_ "GenSigSendType" SG_ 2566805246 AftrtrtmntDEFTankLoLvlInd 0;
BA_ "GenSigTimeoutTime_ECU" SG_ 2566749182 PartTrap1SootLoadPercent 60000;
BA_ "GenSigSendType" SG_ 2566749182 PartTrap1SootLoadPercent 0;
BA_ "GenSigTimeoutTime_ECU" SG_ 2566749182 PartTrap1AshLoadPercent 60000;
BA_ "GenSigSendType" SG_ 2566749182 PartTrap1AshLoadPercent 0;
BA_ "GenSigTimeoutTime_ECU" SG_ 2566749182 PartTrap1TimeSinceLastActReg 60000;
BA_ "GenSigSendType" SG_ 2566749182 PartTrap1TimeSinceLastActReg 0;
BA_ "GenSigTimeoutTime_ECU" SG_ 2566763518 AftrDiesPartFltrOutlGasTemp 2500;
BA_ "GenSigSendType" SG_ 2566763518 AftrDiesPartFltrOutlGasTemp 0;
BA_ "GenSigTimeoutTime_ECU" SG_ 2566700542 AftrtrtmntTotalDEFUsed 60000;
BA_ "GenSigSendType" SG_ 2566700542 AftrtrtmntTotalDEFUsed 0;
BA_ "GenSigTimeoutTime_ECU" SG_ 2565874686 AftrTrtmDiesExhsFldActDsngQty 250;
BA_ "GenSigSendType" SG_ 2565874686 AftrTrtmDiesExhsFldActDsngQty 0;
BA_ "GenSigTimeoutTime_ECU" SG_ 2566845787 BarometricPress 5000;
BA_ "GenSigSendType" SG_ 2566845787 BarometricPress 0;
BA_ "GenSigTimeoutTime_ECU" SG_ 2566845787 AmbAirTemp 5000;
BA_ "GenSigSendType" SG_ 2566845787 AmbAirTemp 0;
BA_ "GenSigTimeoutTime_ECU" SG_ 2566845787 EngAirInTemp 5000;
BA_ "GenSigSendType" SG_ 2566845787 EngAirInTemp 0;
BA_ "GenSigTimeoutTime_ECU" SG_ 2432635995 HarvestSmartPauseResumeCmd 500;
BA_ "GenSigSendType" SG_ 2432635995 HarvestSmartPauseResumeCmd 0;
BA_ "GenSigTimeoutTime_ECU" SG_ 2298409307 WheelBasedVehicleSpeed 500;
BA_ "GenSigSendType" SG_ 2298409307 WheelBasedVehicleSpeed 0;
BA_ "GenSigTimeoutTime_ECU" SG_ 2298409307 BrakeSwitch 500;
BA_ "GenSigSendType" SG_ 2298409307 BrakeSwitch 0;
BA_ "GenSigTimeoutTime_ECU" SG_ 2499738715 FuelLevel 5000;
BA_ "GenSigSendType" SG_ 2499738715 FuelLevel 0;
BA_ "GenSigTimeoutTime_ECU" SG_ 2566749438 CANExhstSysHighTempLmpCmd 5000;
BA_ "GenSigSendType" SG_ 2566749438 CANExhstSysHighTempLmpCmd 0;
BA_ "GenSigTimeoutTime_ECU" SG_ 2566719270 EngRedStopLmpCmd 5000;
BA_ "GenSigSendType" SG_ 2566719270 EngRedStopLmpCmd 0;
BA_ "GenSigTimeoutTime_ECU" SG_ 2364539995 EngineTorqueMode 100;
BA_ "GenSigSendType" SG_ 2364539995 EngineTorqueMode 0;
BA_ "GenSigTimeoutTime_ECU" SG_ 2364539995 ActEngPrcntTorqFrac 100;
BA_ "GenSigSendType" SG_ 2364539995 ActEngPrcntTorqFrac 0;
BA_ "GenSigTimeoutTime_ECU" SG_ 2364539995 DrvrsDmdEngPctTorq 100;
BA_ "GenSigSendType" SG_ 2364539995 DrvrsDmdEngPctTorq 0;
BA_ "GenSigTimeoutTime_ECU" SG_ 2364539995 ActualEnginePercentTorque 100;
BA_ "GenSigSendType" SG_ 2364539995 ActualEnginePercentTorque 0;
BA_ "GenSigTimeoutTime_ECU" SG_ 2364539995 EngineSpeed 100;
BA_ "GenSigSendType" SG_ 2364539995 EngineSpeed 0;
BA_ "GenSigTimeoutTime_ECU" SG_ 2364539995 SrcAddofCntlDevForEngCont 100;
BA_ "GenSigSendType" SG_ 2364539995 SrcAddofCntlDevForEngCont 0;
BA_ "GenSigTimeoutTime_ECU" SG_ 2364539995 EngStarterMode 100;
BA_ "GenSigSendType" SG_ 2364539995 EngStarterMode 0;
BA_ "GenSigTimeoutTime_ECU" SG_ 2364539995 EngDemandPctTorq 100;
BA_ "GenSigSendType" SG_ 2364539995 EngDemandPctTorq 0;
BA_ "GenSigTimeoutTime_ECU" SG_ 2364539902 PercentLoadAtCurrentSpeed 250;
BA_ "GenSigSendType" SG_ 2364539902 PercentLoadAtCurrentSpeed 0;
BA_ "GenSigTimeoutTime_ECU" SG_ 2364539902 AccelPedalLoIdleSw 250;
BA_ "GenSigSendType" SG_ 2364539902 AccelPedalLoIdleSw 0;
BA_ "GenSigTimeoutTime_ECU" SG_ 2364539902 AccelPedalKckdownSw 250;
BA_ "GenSigSendType" SG_ 2364539902 AccelPedalKckdownSw 0;
BA_ "GenSigTimeoutTime_ECU" SG_ 2364539902 RoadSpdLimState 250;
BA_ "GenSigSendType" SG_ 2364539902 RoadSpdLimState 0;
BA_ "GenSigTimeoutTime_ECU" SG_ 2364539902 AccelPedal2LoIdleSw 250;
BA_ "GenSigSendType" SG_ 2364539902 AccelPedal2LoIdleSw 0;
BA_ "GenSigTimeoutTime_ECU" SG_ 2364539902 AcceleratorPosition 250;
BA_ "GenSigSendType" SG_ 2364539902 AcceleratorPosition 0;
BA_ "GenSigTimeoutTime_ECU" SG_ 2364539902 RemoteAccelerator 250;
BA_ "GenSigSendType" SG_ 2364539902 RemoteAccelerator 0;
BA_ "GenSigTimeoutTime_ECU" SG_ 2364539902 AccelInput2Pstn 250;
BA_ "GenSigSendType" SG_ 2364539902 AccelInput2Pstn 0;
BA_ "GenSigTimeoutTime_ECU" SG_ 2364539902 VehAccelRateLimState 250;
BA_ "GenSigSendType" SG_ 2364539902 VehAccelRateLimState 0;
BA_ "GenSigTimeoutTime_ECU" SG_ 2364539902 MomEngMaxPwrEnblFdbk 250;
BA_ "GenSigSendType" SG_ 2364539902 MomEngMaxPwrEnblFdbk 0;
BA_ "GenSigTimeoutTime_ECU" SG_ 2364539902 DPFThrmlMngmntActive 250;
BA_ "GenSigSendType" SG_ 2364539902 DPFThrmlMngmntActive 0;
BA_ "GenSigTimeoutTime_ECU" SG_ 2364539902 SCRThrmlMngmntActv 250;
BA_ "GenSigSendType" SG_ 2364539902 SCRThrmlMngmntActv 0;
BA_ "GenSigTimeoutTime_ECU" SG_ 2364539902 ActMaxAvailEngPrcntTorq 250;
BA_ "GenSigSendType" SG_ 2364539902 ActMaxAvailEngPrcntTorq 0;
BA_ "GenSigTimeoutTime_ECU" SG_ 2364539902 EstPumpPrcntTorq 250;
BA_ "GenSigSendType" SG_ 2364539902 EstPumpPrcntTorq 0;
BA_ "GenSigTimeoutTime_ECU" SG_ 2566840318 EnginesDesiredOperatingSpeed 500;
BA_ "GenSigSendType" SG_ 2566840318 EnginesDesiredOperatingSpeed 0;
BA_ "GenSigTimeoutTime_ECU" SG_ 2566840318 EngDsrdOpSpdAsymAdj 500;
BA_ "GenSigSendType" SG_ 2566840318 EngDsrdOpSpdAsymAdj 0;
BA_ "GenSigTimeoutTime_ECU" SG_ 2566840318 EstmtdEngParasiticLossPrcntTorq 500;
BA_ "GenSigSendType" SG_ 2566840318 EstmtdEngParasiticLossPrcntTorq 0;
BA_ "GenSigTimeoutTime_ECU" SG_ 2566840318 Aftr1ExhaGasMassFlowRate 500;
BA_ "GenSigSendType" SG_ 2566840318 Aftr1ExhaGasMassFlowRate 0;
BA_ "GenSigTimeoutTime_ECU" SG_ 2566840318 AftertreatmentIntakeDewPnt 500;
BA_ "GenSigSendType" SG_ 2566840318 AftertreatmentIntakeDewPnt 0;
BA_ "GenSigTimeoutTime_ECU" SG_ 2566840318 AftertreatmentExhaustDewPnt 500;
BA_ "GenSigSendType" SG_ 2566840318 AftertreatmentExhaustDewPnt 0;
BA_ "GenSigTimeoutTime_ECU" SG_ 2566840318 Aftertreatment2IntakeDewPnt 500;
BA_ "GenSigSendType" SG_ 2566840318 Aftertreatment2IntakeDewPnt 0;
BA_ "GenSigTimeoutTime_ECU" SG_ 2566840318 Aftertreatment2ExhDewPnt 500;
BA_ "GenSigSendType" SG_ 2566840318 Aftertreatment2ExhDewPnt 0;
BA_ "GenSigTimeoutTime_ECU" SG_ 2566844414 FuelDeliveryPressure 2500;
BA_ "GenSigSendType" SG_ 2566844414 FuelDeliveryPressure 0;
BA_ "GenSigTimeoutTime_ECU" SG_ 2566844414 EngCoolPress 2500;
BA_ "GenSigSendType" SG_ 2566844414 EngCoolPress 0;
BA_ "GenSigTimeoutTime_ECU" SG_ 2566844414 EngineOilPressure 2500;
BA_ "GenSigSendType" SG_ 2566844414 EngineOilPressure 0;
BA_ "GenSigTimeoutTime_ECU" SG_ 2566841854 EngineHours 60000;
BA_ "GenSigSendType" SG_ 2566841854 EngineHours 0;
BA_ "GenSigTimeoutTime_ECU" SG_ 2566843995 EngineCoolantTemperature 5000;
BA_ "GenSigSendType" SG_ 2566843995 EngineCoolantTemperature 0;
BA_ "GenSigTimeoutTime_ECU" SG_ 2566843995 FuelTemperature 5000;
BA_ "GenSigSendType" SG_ 2566843995 FuelTemperature 0;
BA_ "GenSigTimeoutTime_ECU" SG_ 2432537179 EngOpState 1250;
BA_ "GenSigSendType" SG_ 2432537179 EngOpState 0;
BA_ "GenSigTimeoutTime_ECU" SG_ 2431708465 EngineStartRequest 5000;
BA_ "GenSigSendType" SG_ 2431708465 EngineStartRequest 0;
BA_ "GenSigTimeoutTime_ECU" SG_ 2431708651 EngineStartConsent 5000;
BA_ "GenSigSendType" SG_ 2431708651 EngineStartConsent 0;
BA_ "GenSigTimeoutTime_ECU" SG_ 2431708507 EngineStartConsent 5000;
BA_ "GenSigSendType" SG_ 2431708507 EngineStartConsent 0;
BA_ "GenSigTimeoutTime_ECU" SG_ 2566809947 EngIntakeManifold1AirTempHighRes 5000;
BA_ "GenSigSendType" SG_ 2566809947 EngIntakeManifold1AirTempHighRes 0;
BA_ "GenSigTimeoutTime_ECU" SG_ 2566809947 EngClntTempHighRes 5000;
BA_ "GenSigSendType" SG_ 2566809947 EngClntTempHighRes 0;
BA_ "GenSigTimeoutTime_ECU" SG_ 2566809947 EngChargeAirClrOutTemp 5000;
BA_ "GenSigSendType" SG_ 2566809947 EngChargeAirClrOutTemp 0;
BA_ "GenSigTimeoutTime_ECU" SG_ 2566842878 TotalFuelUsed 25000;
BA_ "GenSigSendType" SG_ 2566842878 TotalFuelUsed 0;
BA_ "GenSigTimeoutTime_ECU" SG_ 2566845182 EngFuelRate 500;
BA_ "GenSigSendType" SG_ 2566845182 EngFuelRate 0;
BA_ "GenSigTimeoutTime_ECU" SG_ 2360147966 EstimatedCurvature 500;
BA_ "GenSigSendType" SG_ 2360147966 EstimatedCurvature 0;
BA_ "GenSigTimeoutTime_ECU" SG_ 2360147966 MechSysLockout 500;
BA_ "GenSigSendType" SG_ 2360147966 MechSysLockout 0;
BA_ "GenSigTimeoutTime_ECU" SG_ 2360147966 StrgSysReadiness 500;
BA_ "GenSigSendType" SG_ 2360147966 StrgSysReadiness 0;
BA_ "GenSigTimeoutTime_ECU" SG_ 2360147966 StrgInputPstnState 500;
BA_ "GenSigSendType" SG_ 2360147966 StrgInputPstnState 0;
BA_ "GenSigTimeoutTime_ECU" SG_ 2360147966 ReqResetCmdState 500;
BA_ "GenSigSendType" SG_ 2360147966 ReqResetCmdState 0;
BA_ "GenSigTimeoutTime_ECU" SG_ 2360147966 GuideLimState 500;
BA_ "GenSigSendType" SG_ 2360147966 GuideLimState 0;
BA_ "GenSigTimeoutTime_ECU" SG_ 2360147966 GuideSysCmdExitRsnCode 500;
BA_ "GenSigSendType" SG_ 2360147966 GuideSysCmdExitRsnCode 0;
BA_ "GenSigTimeoutTime_ECU" SG_ 2360213286 CurvCmd 500;
BA_ "GenSigSendType" SG_ 2360213286 CurvCmd 0;
BA_ "GenSigTimeoutTime_ECU" SG_ 2360213286 CurvatureCmdState 500;
BA_ "GenSigSendType" SG_ 2360213286 CurvatureCmdState 0;
BA_ "GenSigTimeoutTime_ECU" SG_ 2365528881 SAS_Mask 250;
BA_ "GenSigSendType" SG_ 2365528881 SAS_Mask 0;
BA_ "GenSigTimeoutTime_ECU" SG_ 2365528881 SAS_SensorType 250;
BA_ "GenSigSendType" SG_ 2365528881 SAS_SensorType 0;
BA_ "GenSigTimeoutTime_ECU" SG_ 2365528881 SAS_CalibrationStatus 250;
BA_ "GenSigSendType" SG_ 2365528881 SAS_CalibrationStatus 0;
BA_ "GenSigTimeoutTime_ECU" SG_ 2365528881 SAS_DataIsValid 250;
BA_ "GenSigSendType" SG_ 2365528881 SAS_DataIsValid 0;
BA_ "GenSigTimeoutTime_ECU" SG_ 2365528881 SAS_Angle 250;
BA_ "GenSigSendType" SG_ 2365528881 SAS_Angle 0;
BA_ "GenSigTimeoutTime_ECU" SG_ 2365528881 SAS_AngleGradient 250;
BA_ "GenSigSendType" SG_ 2365528881 SAS_AngleGradient 0;
BA_ "GenSigTimeoutTime_ECU" SG_ 2365528881 SAS_RollingCounter 250;
BA_ "GenSigSendType" SG_ 2365528881 SAS_RollingCounter 0;
BA_ "GenSigTimeoutTime_ECU" SG_ 2365528881 SAS_Checksum 250;
BA_ "GenSigSendType" SG_ 2365528881 SAS_Checksum 0;
BA_ "GenSigTimeoutTime_ECU" SG_ 2361850878 HeaderLiftValveStateFeedback 500;
BA_ "GenSigSendType" SG_ 2361850878 HeaderLiftValveStateFeedback 0;
BA_ "GenSigTimeoutTime_ECU" SG_ 2361851902 HeaderLiftValveStateFeedback 500;
BA_ "GenSigSendType" SG_ 2361851902 HeaderLiftValveStateFeedback 0;
BA_ "GenSigTimeoutTime_ECU" SG_ 2566846206 EngParticulateTrapInPress 2500;
BA_ "GenSigSendType" SG_ 2566846206 EngParticulateTrapInPress 0;
BA_ "GenSigTimeoutTime_ECU" SG_ 2566846206 EngIntakeMan1Pressure 2500;
BA_ "GenSigSendType" SG_ 2566846206 EngIntakeMan1Pressure 0;
BA_ "GenSigTimeoutTime_ECU" SG_ 2566846206 EngIntakeMan1Temperature 2500;
BA_ "GenSigSendType" SG_ 2566846206 EngIntakeMan1Temperature 0;
BA_ "GenSigTimeoutTime_ECU" SG_ 2566846206 EngAirInPress 2500;
BA_ "GenSigSendType" SG_ 2566846206 EngAirInPress 0;
BA_ "GenSigTimeoutTime_ECU" SG_ 2566846206 AirFilterDifPressure 2500;
BA_ "GenSigSendType" SG_ 2566846206 AirFilterDifPressure 0;
BA_ "GenSigTimeoutTime_ECU" SG_ 2566846206 ExhGasTemp 2500;
BA_ "GenSigSendType" SG_ 2566846206 ExhGasTemp 0;
BA_ "GenSigTimeoutTime_ECU" SG_ 2566846206 EngCoolFilterDiffPress 2500;
BA_ "GenSigSendType" SG_ 2566846206 EngCoolFilterDiffPress 0;
BA_ "GenSigTimeoutTime_ECU" SG_ 2365582427 RightTurnSignalLightsCommand 500;
BA_ "GenSigSendType" SG_ 2365582427 RightTurnSignalLightsCommand 0;
BA_ "GenSigTimeoutTime_ECU" SG_ 2365582427 LeftTurnSignalLightsCommand 500;
BA_ "GenSigSendType" SG_ 2365582427 LeftTurnSignalLightsCommand 0;
BA_ "GenSigTimeoutTime_ECU" SG_ 2365582427 TrlrIndLightCmd 500;
BA_ "GenSigSendType" SG_ 2365582427 TrlrIndLightCmd 0;
BA_ "GenSigTimeoutTime_ECU" SG_ 2365473073 RotatingBeaconLightCommand 5000;
BA_ "GenSigSendType" SG_ 2365473073 RotatingBeaconLightCommand 0;
BA_ "GenSigTimeoutTime_ECU" SG_ 2365473073 LeftStopLightCommand 5000;
BA_ "GenSigSendType" SG_ 2365473073 LeftStopLightCommand 0;
BA_ "GenSigTimeoutTime_ECU" SG_ 2365473073 MarkerLightCommand 5000;
BA_ "GenSigSendType" SG_ 2365473073 MarkerLightCommand 0;
BA_ "GenSigTimeoutTime_ECU" SG_ 2566801386 MaintainActuatorPower 2600;
BA_ "GenSigSendType" SG_ 2566801386 MaintainActuatorPower 0;
BA_ "GenSigTimeoutTime_ECU" SG_ 2566801386 MaintainECUPower 2600;
BA_ "GenSigSendType" SG_ 2566801386 MaintainECUPower 0;
BA_ "GenSigTimeoutTime_ECU" SG_ 2566801386 ImplementWorkState 2600;
BA_ "GenSigSendType" SG_ 2566801386 ImplementWorkState 0;
BA_ "GenSigTimeoutTime_ECU" SG_ 2566801386 ImplementParkState 2600;
BA_ "GenSigSendType" SG_ 2566801386 ImplementParkState 0;
BA_ "GenSigTimeoutTime_ECU" SG_ 2566801386 ImplementTransportState 2600;
BA_ "GenSigSendType" SG_ 2566801386 ImplementTransportState 0;
BA_ "GenSigTimeoutTime_ECU" SG_ 2566801387 MaintainActuatorPower 2600;
BA_ "GenSigSendType" SG_ 2566801387 MaintainActuatorPower 0;
BA_ "GenSigTimeoutTime_ECU" SG_ 2566801387 MaintainECUPower 2600;
BA_ "GenSigSendType" SG_ 2566801387 MaintainECUPower 0;
BA_ "GenSigTimeoutTime_ECU" SG_ 2566801387 ImplementWorkState 2600;
BA_ "GenSigSendType" SG_ 2566801387 ImplementWorkState 0;
BA_ "GenSigTimeoutTime_ECU" SG_ 2566801387 ImplementParkState 2600;
BA_ "GenSigSendType" SG_ 2566801387 ImplementParkState 0;
BA_ "GenSigTimeoutTime_ECU" SG_ 2566801387 ImplementTransportState 2600;
BA_ "GenSigSendType" SG_ 2566801387 ImplementTransportState 0;
BA_ "GenSigTimeoutTime_ECU" SG_ 2566801243 MaintainActuatorPower 2600;
BA_ "GenSigSendType" SG_ 2566801243 MaintainActuatorPower 0;
BA_ "GenSigTimeoutTime_ECU" SG_ 2566801243 ImplementWorkState 2600;
BA_ "GenSigSendType" SG_ 2566801243 ImplementWorkState 0;
BA_ "GenSigTimeoutTime_ECU" SG_ 2566801243 ImplementParkState 2600;
BA_ "GenSigSendType" SG_ 2566801243 ImplementParkState 0;
BA_ "GenSigTimeoutTime_ECU" SG_ 2566801243 ImplementTransportState 2600;
BA_ "GenSigSendType" SG_ 2566801243 ImplementTransportState 0;
BA_ "GenSigTimeoutTime_ECU" SG_ 2365528299 ReconfigCtrlAssignmentLockMask 500;
BA_ "GenSigTimeoutTime_ECU" SG_ 2365528299 ReconfigCtrlAssignmentFunctionId 500;
BA_ "GenSigTimeoutTime_ECU" SG_ 2365528299 ReconfigCtrlAssignmentInputId 500;
BA_ "GenSigTimeoutTime_ECU" SG_ 2365528299 RecoCtrlAssiSequSize 500;
BA_ "GenSigTimeoutTime_ECU" SG_ 2365528299 RecoCtrlAssiSequNumb 500;
BA_ "GenSigTimeoutTime_ECU" SG_ 2365528299 RecoCtrlAssiDataChec 500;
BA_ "GenSigTimeoutTime_ECU" SG_ 2515538171 SequenceID_SDC 5000;
BA_ "GenSigSendType" SG_ 2515538171 SequenceID_SDC 0;
BA_ "GenSigTimeoutTime_ECU" SG_ 2515538171 TimeSource_SDC 5000;
BA_ "GenSigSendType" SG_ 2515538171 TimeSource_SDC 0;
BA_ "GenSigTimeoutTime_ECU" SG_ 2515538171 GenericDate_SDC 5000;
BA_ "GenSigSendType" SG_ 2515538171 GenericDate_SDC 0;
BA_ "GenSigTimeoutTime_ECU" SG_ 2515538171 GenericTimeofDay_SDC 5000;
BA_ "GenSigSendType" SG_ 2515538171 GenericTimeofDay_SDC 0;
BA_ "GenSigTimeoutTime_ECU" SG_ 2365515814 CompassBearing 1000;
BA_ "GenSigSendType" SG_ 2365515814 CompassBearing 0;
BA_ "GenSigTimeoutTime_ECU" SG_ 2365515814 NavigationBasedVehicleSpeed 1000;
BA_ "GenSigSendType" SG_ 2365515814 NavigationBasedVehicleSpeed 0;
BA_ "GenSigTimeoutTime_ECU" SG_ 2365515814 Pitch 1000;
BA_ "GenSigSendType" SG_ 2365515814 Pitch 0;
BA_ "GenSigTimeoutTime_ECU" SG_ 2365515814 Altitude 1000;
BA_ "GenSigSendType" SG_ 2365515814 Altitude 0;
BA_ "GenSigTimeoutTime_ECU" SG_ 2499700827 HydOilTemp 5000;
BA_ "GenSigSendType" SG_ 2499700827 HydOilTemp 0;
BA_ "GenSigTimeoutTime_ECU" SG_ 2499700827 HydOilFilterRestrictionSwitch 5000;
BA_ "GenSigSendType" SG_ 2499700827 HydOilFilterRestrictionSwitch 0;
BA_ "GenSigTimeoutTime_ECU" SG_ 2499700827 CPRTemperature 5000;
BA_ "GenSigSendType" SG_ 2499700827 CPRTemperature 0;
BA_ "GenSigTimeoutTime_ECU" SG_ 2566842161 VehHrs 25000;
BA_ "GenSigSendType" SG_ 2566842161 VehHrs 0;
BA_ "GenSigTimeoutTime_ECU" SG_ 2559377386 CRO_DatParms 60000;
BA_ "GenSigTimeoutTime_ECU" SG_ 2559377387 CRO_DatParms 60000;
BA_ "GenSigTimeoutTime_ECU" SG_ 2559377401 CRO_DatParms 60000;
BA_ "GenSigTimeoutTime_ECU" SG_ 2559377402 CRO_DatParms 60000;
BA_ "GenSigTimeoutTime_ECU" SG_ 2559377243 CRO_DatParms 60000;
BA_ "GenSigTimeoutTime_ECU" SG_ 2559377370 CRO_DatParms 60000;
BA_ "GenSigTimeoutTime_ECU" SG_ 2559311816 DTO_DatParms 60000;
BA_ "GenSigTimeoutTime_ECU" SG_ 2559311850 DTO_DatParms 60000;
BA_ "GenSigTimeoutTime_ECU" SG_ 2559311851 DTO_DatParms 60000;
BA_ "GenSigTimeoutTime_ECU" SG_ 2559311865 DTO_DatParms 60000;
BA_ "GenSigTimeoutTime_ECU" SG_ 2559311866 DTO_DatParms 60000;
BA_ "GenSigTimeoutTime_ECU" SG_ 2559311707 DTO_DatParms 60000;
BA_ "GenSigTimeoutTime_ECU" SG_ 2559311834 DTO_DatParms 60000;
BA_ "GenSigTimeoutTime_ECU" SG_ 2559363306 CRO_DatParms 60000;
BA_ "GenSigTimeoutTime_ECU" SG_ 2559372266 CRO_DatParms 60000;
BA_ "GenSigTimeoutTime_ECU" SG_ 2559375850 CRO_DatParms 60000;
BA_ "GenSigTimeoutTime_ECU" SG_ 2559376106 CRO_DatParms 60000;
BA_ "GenSigTimeoutTime_ECU" SG_ 2559335402 CRO_DatParms 60000;
BA_ "GenSigTimeoutTime_ECU" SG_ 2559367914 CRO_DatParms 60000;
BA_ "GenSigTimeoutTime_ECU" SG_ 2559363307 CRO_DatParms 60000;
BA_ "GenSigTimeoutTime_ECU" SG_ 2559372011 CRO_DatParms 60000;
BA_ "GenSigTimeoutTime_ECU" SG_ 2559375851 CRO_DatParms 60000;
BA_ "GenSigTimeoutTime_ECU" SG_ 2559376107 CRO_DatParms 60000;
BA_ "GenSigTimeoutTime_ECU" SG_ 2559335403 CRO_DatParms 60000;
BA_ "GenSigTimeoutTime_ECU" SG_ 2559367915 CRO_DatParms 60000;
BA_ "GenSigTimeoutTime_ECU" SG_ 2559363322 CRO_DatParms 60000;
BA_ "GenSigTimeoutTime_ECU" SG_ 2559372026 CRO_DatParms 60000;
BA_ "GenSigTimeoutTime_ECU" SG_ 2559372282 CRO_DatParms 60000;
BA_ "GenSigTimeoutTime_ECU" SG_ 2559375866 CRO_DatParms 60000;
BA_ "GenSigTimeoutTime_ECU" SG_ 2559335418 CRO_DatParms 60000;
BA_ "GenSigTimeoutTime_ECU" SG_ 2559367930 CRO_DatParms 60000;
BA_ "GenSigTimeoutTime_ECU" SG_ 2559363321 CRO_DatParms 60000;
BA_ "GenSigTimeoutTime_ECU" SG_ 2559372025 CRO_DatParms 60000;
BA_ "GenSigTimeoutTime_ECU" SG_ 2559372281 CRO_DatParms 60000;
BA_ "GenSigTimeoutTime_ECU" SG_ 2559376121 CRO_DatParms 60000;
BA_ "GenSigTimeoutTime_ECU" SG_ 2559335417 CRO_DatParms 60000;
BA_ "GenSigTimeoutTime_ECU" SG_ 2559367929 CRO_DatParms 60000;
BA_ "GenSigTimeoutTime_ECU" SG_ 2559363163 CRO_DatParms 60000;
BA_ "GenSigTimeoutTime_ECU" SG_ 2559371867 CRO_DatParms 60000;
BA_ "GenSigTimeoutTime_ECU" SG_ 2559372123 CRO_DatParms 60000;
BA_ "GenSigTimeoutTime_ECU" SG_ 2559375707 CRO_DatParms 60000;
BA_ "GenSigTimeoutTime_ECU" SG_ 2559375963 CRO_DatParms 60000;
BA_ "GenSigTimeoutTime_ECU" SG_ 2559367771 CRO_DatParms 60000;
BA_ "GenSigTimeoutTime_ECU" SG_ 2559363290 CRO_DatParms 60000;
BA_ "GenSigTimeoutTime_ECU" SG_ 2559371994 CRO_DatParms 60000;
BA_ "GenSigTimeoutTime_ECU" SG_ 2559372250 CRO_DatParms 60000;
BA_ "GenSigTimeoutTime_ECU" SG_ 2559375834 CRO_DatParms 60000;
BA_ "GenSigTimeoutTime_ECU" SG_ 2559376090 CRO_DatParms 60000;
BA_ "GenSigTimeoutTime_ECU" SG_ 2559335386 CRO_DatParms 60000;
BA_ "GenSigTimeoutTime_ECU" SG_ 2559306440 DTO_DatParms 60000;
BA_ "GenSigTimeoutTime_ECU" SG_ 2559306696 DTO_DatParms 60000;
BA_ "GenSigTimeoutTime_ECU" SG_ 2559310280 DTO_DatParms 60000;
BA_ "GenSigTimeoutTime_ECU" SG_ 2559310536 DTO_DatParms 60000;
BA_ "GenSigTimeoutTime_ECU" SG_ 2559269832 DTO_DatParms 60000;
BA_ "GenSigTimeoutTime_ECU" SG_ 2559302344 DTO_DatParms 60000;
BA_ "GenSigTimeoutTime_ECU" SG_ 2559306730 DTO_DatParms 60000;
BA_ "GenSigTimeoutTime_ECU" SG_ 2559310314 DTO_DatParms 60000;
BA_ "GenSigTimeoutTime_ECU" SG_ 2559310570 DTO_DatParms 60000;
BA_ "GenSigTimeoutTime_ECU" SG_ 2559269866 DTO_DatParms 60000;
BA_ "GenSigTimeoutTime_ECU" SG_ 2559302378 DTO_DatParms 60000;
BA_ "GenSigTimeoutTime_ECU" SG_ 2559306475 DTO_DatParms 60000;
BA_ "GenSigTimeoutTime_ECU" SG_ 2559310315 DTO_DatParms 60000;
BA_ "GenSigTimeoutTime_ECU" SG_ 2559310571 DTO_DatParms 60000;
BA_ "GenSigTimeoutTime_ECU" SG_ 2559269867 DTO_DatParms 60000;
BA_ "GenSigTimeoutTime_ECU" SG_ 2559302379 DTO_DatParms 60000;
BA_ "GenSigTimeoutTime_ECU" SG_ 2559306490 DTO_DatParms 60000;
BA_ "GenSigTimeoutTime_ECU" SG_ 2559306746 DTO_DatParms 60000;
BA_ "GenSigTimeoutTime_ECU" SG_ 2559310330 DTO_DatParms 60000;
BA_ "GenSigTimeoutTime_ECU" SG_ 2559269882 DTO_DatParms 60000;
BA_ "GenSigTimeoutTime_ECU" SG_ 2559302394 DTO_DatParms 60000;
BA_ "GenSigTimeoutTime_ECU" SG_ 2559306489 DTO_DatParms 60000;
BA_ "GenSigTimeoutTime_ECU" SG_ 2559306745 DTO_DatParms 60000;
BA_ "GenSigTimeoutTime_ECU" SG_ 2559310585 DTO_DatParms 60000;
BA_ "GenSigTimeoutTime_ECU" SG_ 2559269881 DTO_DatParms 60000;
BA_ "GenSigTimeoutTime_ECU" SG_ 2559302393 DTO_DatParms 60000;
BA_ "GenSigTimeoutTime_ECU" SG_ 2559306331 DTO_DatParms 60000;
BA_ "GenSigTimeoutTime_ECU" SG_ 2559306587 DTO_DatParms 60000;
BA_ "GenSigTimeoutTime_ECU" SG_ 2559310171 DTO_DatParms 60000;
BA_ "GenSigTimeoutTime_ECU" SG_ 2559310427 DTO_DatParms 60000;
BA_ "GenSigTimeoutTime_ECU" SG_ 2559302235 DTO_DatParms 60000;
BA_ "GenSigTimeoutTime_ECU" SG_ 2559306458 DTO_DatParms 60000;
BA_ "GenSigTimeoutTime_ECU" SG_ 2559306714 DTO_DatParms 60000;
BA_ "GenSigTimeoutTime_ECU" SG_ 2559310298 DTO_DatParms 60000;
BA_ "GenSigTimeoutTime_ECU" SG_ 2559310554 DTO_DatParms 60000;
BA_ "GenSigTimeoutTime_ECU" SG_ 2559269850 DTO_DatParms 60000;
BA_ "GenSigTimeoutTime_ECU" SG_ 2566912766 CmdBytePGN65530_Vector_XXX 5000;
BA_ "GenSigTimeoutTime_ECU" SG_ 2566912766 AcceleratedDOCInletTemperature 5000;
BA_ "GenSigSendType" SG_ 2566912766 AcceleratedDOCInletTemperature 0;
BA_ "GenSigTimeoutTime_ECU" SG_ 2566912766 AcceleratedDOCOutletTemperature 5000;
BA_ "GenSigSendType" SG_ 2566912766 AcceleratedDOCOutletTemperature 0;
BA_ "GenSigTimeoutTime_ECU" SG_ 2566912766 AcceleratedSCRInletTemperature 5000;
BA_ "GenSigSendType" SG_ 2566912766 AcceleratedSCRInletTemperature 0;
BA_ "GenSigTimeoutTime_ECU" SG_ 2566912766 AcceleratedDPFOutletNOx 5000;
BA_ "GenSigSendType" SG_ 2566912766 AcceleratedDPFOutletNOx 0;
BA_ "GenSigTimeoutTime_ECU" SG_ 2566912766 AcceleratedSCROutletNOx 5000;
BA_ "GenSigSendType" SG_ 2566912766 AcceleratedSCROutletNOx 0;
BA_ "GenSigTimeoutTime_ECU" SG_ 2566912766 SCRWarmUpRequestedTimer 5000;
BA_ "GenSigSendType" SG_ 2566912766 SCRWarmUpRequestedTimer 0;
BA_ "GenSigTimeoutTime_ECU" SG_ 2566912766 CurrentNumberofStarts 5000;
BA_ "GenSigSendType" SG_ 2566912766 CurrentNumberofStarts 0;
BA_ "GenSigTimeoutTime_ECU" SG_ 2566912766 DesiredFuel 5000;
BA_ "GenSigSendType" SG_ 2566912766 DesiredFuel 0;
BA_ "GenSigTimeoutTime_ECU" SG_ 2566912766 EngineOperatingCondition 5000;
BA_ "GenSigSendType" SG_ 2566912766 EngineOperatingCondition 0;
BA_ "GenSigTimeoutTime_ECU" SG_ 2566912766 DEFFlowRate 5000;
BA_ "GenSigSendType" SG_ 2566912766 DEFFlowRate 0;
BA_ "GenSigTimeoutTime_ECU" SG_ 2566912766 DPFDeltaPressure 5000;
BA_ "GenSigSendType" SG_ 2566912766 DPFDeltaPressure 0;
BA_ "GenSigTimeoutTime_ECU" SG_ 2566912766 FiltNormDPFDeltPresAfteActiRege 5000;
BA_ "GenSigSendType" SG_ 2566912766 FiltNormDPFDeltPresAfteActiRege 0;
BA_ "GenSigTimeoutTime_ECU" SG_ 2566912766 SCRAdapContAdjuFact 5000;
BA_ "GenSigSendType" SG_ 2566912766 SCRAdapContAdjuFact 0;
BA_ "GenSigTimeoutTime_ECU" SG_ 2566912766 MaximumAllowedNH3FlowRate 5000;
BA_ "GenSigSendType" SG_ 2566912766 MaximumAllowedNH3FlowRate 0;
BA_ "GenSigTimeoutTime_ECU" SG_ 2566912766 CharAirCoolEffeLongTermCorrFact 5000;
BA_ "GenSigSendType" SG_ 2566912766 CharAirCoolEffeLongTermCorrFact 0;
BA_ "GenSigTimeoutTime_ECU" SG_ 2566912766 CompInlePresCorrFact 5000;
BA_ "GenSigSendType" SG_ 2566912766 CompInlePresCorrFact 0;
BA_ "GenSigTimeoutTime_ECU" SG_ 2566912766 EGRCoolEffeLongTermCorrFact 5000;
BA_ "GenSigSendType" SG_ 2566912766 EGRCoolEffeLongTermCorrFact 0;
BA_ "GenSigTimeoutTime_ECU" SG_ 2566912766 VTGPosiLongTermCorrOffs 5000;
BA_ "GenSigSendType" SG_ 2566912766 VTGPosiLongTermCorrOffs 0;
BA_ "GenSigTimeoutTime_ECU" SG_ 2566912766 RailPCtrlClsdLoopCmd 5000;
BA_ "GenSigSendType" SG_ 2566912766 RailPCtrlClsdLoopCmd 0;
BA_ "GenSigTimeoutTime_ECU" SG_ 2566912766 IntaManiTempSensEstiUnco 5000;
BA_ "GenSigSendType" SG_ 2566912766 IntaManiTempSensEstiUnco 0;
BA_ "GenSigTimeoutTime_ECU" SG_ 2566912766 CharAirCoolOutlTempSensEstiUnco 5000;
BA_ "GenSigSendType" SG_ 2566912766 CharAirCoolOutlTempSensEstiUnco 0;
BA_ "GenSigTimeoutTime_ECU" SG_ 2566912766 EGRCoolOutlTempSensEstiUnco 5000;
BA_ "GenSigSendType" SG_ 2566912766 EGRCoolOutlTempSensEstiUnco 0;
BA_ "GenSigTimeoutTime_ECU" SG_ 2566912766 EGRGasTemperatureSensor 5000;
BA_ "GenSigSendType" SG_ 2566912766 EGRGasTemperatureSensor 0;
BA_ "GenSigTimeoutTime_ECU" SG_ 2566912766 IntaManiPresEstiUnco 5000;
BA_ "GenSigSendType" SG_ 2566912766 IntaManiPresEstiUnco 0;
BA_ "GenSigTimeoutTime_ECU" SG_ 2566912766 ExhaManiPresSensEstiUnco 5000;
BA_ "GenSigSendType" SG_ 2566912766 ExhaManiPresSensEstiUnco 0;
BA_ "GenSigTimeoutTime_ECU" SG_ 2566912766 ExhaManiPresSensRead 5000;
BA_ "GenSigSendType" SG_ 2566912766 ExhaManiPresSensRead 0;
BA_ "GenSigTimeoutTime_ECU" SG_ 2566912766 CompInteTempSensEstiUnco 5000;
BA_ "GenSigSendType" SG_ 2566912766 CompInteTempSensEstiUnco 0;
BA_ "GenSigTimeoutTime_ECU" SG_ 2566912766 InteCompOutlTempSensRead 5000;
BA_ "GenSigSendType" SG_ 2566912766 InteCompOutlTempSensRead 0;
BA_ "GenSigTimeoutTime_ECU" SG_ 2566912766 CylinderPressurePeak 5000;
BA_ "GenSigSendType" SG_ 2566912766 CylinderPressurePeak 0;
BA_ "GenSigTimeoutTime_ECU" SG_ 2566912766 ExhaManiTempTherEsti 5000;
BA_ "GenSigSendType" SG_ 2566912766 ExhaManiTempTherEsti 0;
BA_ "GenSigTimeoutTime_ECU" SG_ 2298478129 CmdBytePGN65534_CAB 500;
BA_ "GenSigTimeoutTime_ECU" SG_ 2298478129 ACCompressorRequest 500;
BA_ "GenSigSendType" SG_ 2298478129 ACCompressorRequest 0;
BA_ "GenSigTimeoutTime_ECU" SG_ 2298478129 OptrCtrlEncdrInc 500;
BA_ "GenSigSendType" SG_ 2298478129 OptrCtrlEncdrInc 0;
BA_ "GenSigTimeoutTime_ECU" SG_ 2298478129 OptrCtrlEncdrDec 500;
BA_ "GenSigSendType" SG_ 2298478129 OptrCtrlEncdrDec 0;
BA_ "GenSigTimeoutTime_ECU" SG_ 2298478129 OptrCtrlEncdr2Inc 500;
BA_ "GenSigSendType" SG_ 2298478129 OptrCtrlEncdr2Inc 0;
BA_ "GenSigTimeoutTime_ECU" SG_ 2298478129 OptrCtrlEncdr2Dec 500;
BA_ "GenSigSendType" SG_ 2298478129 OptrCtrlEncdr2Dec 0;
BA_ "GenSigTimeoutTime_ECU" SG_ 2566912038 CmdBytePGN65528_VTV 5000;
BA_ "GenSigTimeoutTime_ECU" SG_ 2566912038 FlowIndicator 5000;
BA_ "GenSigSendType" SG_ 2566912038 FlowIndicator 0;
BA_ "GenSigTimeoutTime_ECU" SG_ 2566912038 Flow1PTW 5000;
BA_ "GenSigSendType" SG_ 2566912038 Flow1PTW 0;
BA_ "GenSigTimeoutTime_ECU" SG_ 2566912038 Flow2PTW 5000;
BA_ "GenSigSendType" SG_ 2566912038 Flow2PTW 0;
BA_ "GenSigTimeoutTime_ECU" SG_ 2566912038 Flow3PTW 5000;
BA_ "GenSigSendType" SG_ 2566912038 Flow3PTW 0;
BA_ "GenSigTimeoutTime_ECU" SG_ 2566912038 Flow4PTW 5000;
BA_ "GenSigSendType" SG_ 2566912038 Flow4PTW 0;
BA_ "GenSigTimeoutTime_ECU" SG_ 2566912038 Flow5PTW 5000;
BA_ "GenSigSendType" SG_ 2566912038 Flow5PTW 0;
BA_ "GenSigTimeoutTime_ECU" SG_ 2566912038 ActiveYieldState 5000;
BA_ "GenSigSendType" SG_ 2566912038 ActiveYieldState 0;
BA_ "GenSigTimeoutTime_ECU" SG_ 2566912038 PartialTankWeightState 5000;
BA_ "GenSigSendType" SG_ 2566912038 PartialTankWeightState 0;
BA_ "GenSigTimeoutTime_ECU" SG_ 2566912038 TailBypaPercCleaGraiFilt1 5000;
BA_ "GenSigSendType" SG_ 2566912038 TailBypaPercCleaGraiFilt1 0;
BA_ "GenSigTimeoutTime_ECU" SG_ 2566912038 TailBypaPercCleaGraiFilt2 5000;
BA_ "GenSigSendType" SG_ 2566912038 TailBypaPercCleaGraiFilt2 0;
BA_ "GenSigTimeoutTime_ECU" SG_ 2566912038 IPMOperationalStatus 5000;
BA_ "GenSigSendType" SG_ 2566912038 IPMOperationalStatus 0;
BA_ "GenSigTimeoutTime_ECU" SG_ 2566912038 GQMReportingState 5000;
BA_ "GenSigSendType" SG_ 2566912038 GQMReportingState 0;
BA_ "GenSigTimeoutTime_ECU" SG_ 2566912038 CleanGrainCameraUnavailable 5000;
BA_ "GenSigSendType" SG_ 2566912038 CleanGrainCameraUnavailable 0;
BA_ "GenSigTimeoutTime_ECU" SG_ 2566912038 CleanGrainCameraHardware 5000;
BA_ "GenSigSendType" SG_ 2566912038 CleanGrainCameraHardware 0;
BA_ "GenSigTimeoutTime_ECU" SG_ 2634021630 CmdBytePGN65530_Vector_XXX 5000;
BA_ "GenSigTimeoutTime_ECU" SG_ 2634021630 ExhaManiPresSensFiltOffs 5000;
BA_ "GenSigSendType" SG_ 2634021630 ExhaManiPresSensFiltOffs 0;
BA_ "GenSigTimeoutTime_ECU" SG_ 2634021630 CompressorFlowCorrectionFactor 5000;
BA_ "GenSigSendType" SG_ 2634021630 CompressorFlowCorrectionFactor 0;
BA_ "GenSigTimeoutTime_ECU" SG_ 2634021630 WastMassFlowLongTermCorrFact 5000;
BA_ "GenSigSendType" SG_ 2634021630 WastMassFlowLongTermCorrFact 0;
BA_ "GenSigTimeoutTime_ECU" SG_ 2634021630 ExhaThroPosiLongTermCorrOffs 5000;
BA_ "GenSigSendType" SG_ 2634021630 ExhaThroPosiLongTermCorrOffs 0;
BA_ "GenSigTimeoutTime_ECU" SG_ 2634021630 AECDActiveStatusAll 5000;
BA_ "GenSigSendType" SG_ 2634021630 AECDActiveStatusAll 0;
BA_ "GenSigTimeoutTime_ECU" SG_ 2634021630 WastActuPresLongTermCorrOf 5000;
BA_ "GenSigSendType" SG_ 2634021630 WastActuPresLongTermCorrOf 0;
BA_ "GenSigTimeoutTime_ECU" SG_ 2634021630 IntaManiTempEGRFlowCorrStat 5000;
BA_ "GenSigSendType" SG_ 2634021630 IntaManiTempEGRFlowCorrStat 0;
BA_ "GenSigTimeoutTime_ECU" SG_ 2634021630 AirModeAirThrottleMode 5000;
BA_ "GenSigSendType" SG_ 2634021630 AirModeAirThrottleMode 0;
BA_ "GenSigTimeoutTime_ECU" SG_ 2634021630 AirSystObseInpuConfLeve 5000;
BA_ "GenSigSendType" SG_ 2634021630 AirSystObseInpuConfLeve 0;
BA_ "GenSigTimeoutTime_ECU" SG_ 2634021630 NOxBasedEGRFlowCorrectionState 5000;
BA_ "GenSigSendType" SG_ 2634021630 NOxBasedEGRFlowCorrectionState 0;
BA_ "GenSigTimeoutTime_ECU" SG_ 2634021630 EGRFlowCorrectionActionRequest 5000;
BA_ "GenSigSendType" SG_ 2634021630 EGRFlowCorrectionActionRequest 0;
BA_ "GenSigTimeoutTime_ECU" SG_ 2634021630 AirModeEGRValveMode 5000;
BA_ "GenSigSendType" SG_ 2634021630 AirModeEGRValveMode 0;
BA_ "GenSigTimeoutTime_ECU" SG_ 2634021630 AirModeWastegateSolenoidMode 5000;
BA_ "GenSigSendType" SG_ 2634021630 AirModeWastegateSolenoidMode 0;
BA_ "GenSigTimeoutTime_ECU" SG_ 2634021630 AirModeExhaustThrottleMode 5000;
BA_ "GenSigSendType" SG_ 2634021630 AirModeExhaustThrottleMode 0;
BA_ "GenSigTimeoutTime_ECU" SG_ 2634021630 AirModeVTGMode 5000;
BA_ "GenSigSendType" SG_ 2634021630 AirModeVTGMode 0;
BA_ "GenSigTimeoutTime_ECU" SG_ 2634021630 CharAirCoolMassFlowLongTermCorrFact 5000;
BA_ "GenSigSendType" SG_ 2634021630 CharAirCoolMassFlowLongTermCorrFact 0;
BA_ "GenSigTimeoutTime_ECU" SG_ 2634021630 EGRFlowCorrFactLongTermCorrOffs 5000;
BA_ "GenSigSendType" SG_ 2634021630 EGRFlowCorrFactLongTermCorrOffs 0;
BA_ "GenSigTimeoutTime_ECU" SG_ 2634021630 EGRFlowCorrectionFactor 5000;
BA_ "GenSigSendType" SG_ 2634021630 EGRFlowCorrectionFactor 0;
BA_ "GenSigTimeoutTime_ECU" SG_ 2634021630 TurbMapMassFlowLongTermCorrFact 5000;
BA_ "GenSigSendType" SG_ 2634021630 TurbMapMassFlowLongTermCorrFact 0;
BA_ "GenSigTimeoutTime_ECU" SG_ 2634021630 AirThroPosiLongTermCorrOffs 5000;
BA_ "GenSigSendType" SG_ 2634021630 AirThroPosiLongTermCorrOffs 0;
BA_ "GenSigTimeoutTime_ECU" SG_ 2634021630 EGRValvPosiLongTermCorrOffs 5000;
BA_ "GenSigSendType" SG_ 2634021630 EGRValvPosiLongTermCorrOffs 0;
BA_ "GenSigTimeoutTime_ECU" SG_ 2365587454 CmdBytePGN65535_Vector_XXX 5000;
BA_ "GenSigTimeoutTime_ECU" SG_ 2365587454 AutoTracWheelbase_AGSR 5000;
BA_ "GenSigSendType" SG_ 2365587454 AutoTracWheelbase_AGSR 0;
BA_ "GenSigTimeoutTime_ECU" SG_ 2365587454 AutoTracSysCtlrLoSpdLim 5000;
BA_ "GenSigSendType" SG_ 2365587454 AutoTracSysCtlrLoSpdLim 0;
BA_ "GenSigTimeoutTime_ECU" SG_ 2365587454 AutoTracSysCtlrUpSpdLim 5000;
BA_ "GenSigSendType" SG_ 2365587454 AutoTracSysCtlrUpSpdLim 0;
BA_ "GenSigTimeoutTime_ECU" SG_ 2365587454 AutoTracSysCtlrUnlimitRevCapable 5000;
BA_ "GenSigSendType" SG_ 2365587454 AutoTracSysCtlrUnlimitRevCapable 0;
BA_ "GenSigTimeoutTime_ECU" SG_ 2365587454 AuxResuCap 5000;
BA_ "GenSigSendType" SG_ 2365587454 AuxResuCap 0;
BA_ "GenSigTimeoutTime_ECU" SG_ 2365587454 WASType 5000;
BA_ "GenSigSendType" SG_ 2365587454 WASType 0;
BA_ "GenSigTimeoutTime_ECU" SG_ 2365587454 MaxReverseSpeed 5000;
BA_ "GenSigSendType" SG_ 2365587454 MaxReverseSpeed 0;
BA_ "GenSigTimeoutTime_ECU" SG_ 2365587454 ConfigMachineClass 5000;
BA_ "GenSigSendType" SG_ 2365587454 ConfigMachineClass 0;
BA_ "GenSigTimeoutTime_ECU" SG_ 2365587454 SIDType 5000;
BA_ "GenSigSendType" SG_ 2365587454 SIDType 0;
BA_ "GenSigTimeoutTime_ECU" SG_ 2365587454 ActuatorType 5000;
BA_ "GenSigSendType" SG_ 2365587454 ActuatorType 0;
BA_ "GenSigTimeoutTime_ECU" SG_ 2365587454 StarfireFwdCfg_AGSR 5000;
BA_ "GenSigSendType" SG_ 2365587454 StarfireFwdCfg_AGSR 0;
BA_ "GenSigTimeoutTime_ECU" SG_ 2432696113 CmdBytePGN65535_CAB 1000;
BA_ "GenSigTimeoutTime_ECU" SG_ 2432696113 QuickStopSwitch 1000;
BA_ "GenSigSendType" SG_ 2432696113 QuickStopSwitch 0;
BA_ "GenSigTimeoutTime_ECU" SG_ 2432696113 OperatorSeatSwitch 1000;
BA_ "GenSigSendType" SG_ 2432696113 OperatorSeatSwitch 0;
BA_ "GenSigTimeoutTime_ECU" SG_ 2566913841 CmdBytePGN65535_CAB 5000;
BA_ "GenSigTimeoutTime_ECU" SG_ 2566913841 WasherPumpCmdFrnt 5000;
BA_ "GenSigSendType" SG_ 2566913841 WasherPumpCmdFrnt 0;
BA_ "GenSigTimeoutTime_ECU" SG_ 2566913841 WasherPumpCmdRight 5000;
BA_ "GenSigSendType" SG_ 2566913841 WasherPumpCmdRight 0;
BA_ "GenSigTimeoutTime_ECU" SG_ 2566912561 CmdBytePGN65530_CAB 5000;
BA_ "GenSigTimeoutTime_ECU" SG_ 2566912561 WorkLight1LeftCmd 5000;
BA_ "GenSigSendType" SG_ 2566912561 WorkLight1LeftCmd 0;
BA_ "GenSigTimeoutTime_ECU" SG_ 2566912561 WorkLight4LeftCmd 5000;
BA_ "GenSigSendType" SG_ 2566912561 WorkLight4LeftCmd 0;
BA_ "GenSigTimeoutTime_ECU" SG_ 2566912561 WorkLight9LeftCmd 5000;
BA_ "GenSigSendType" SG_ 2566912561 WorkLight9LeftCmd 0;
BA_ "GenSigTimeoutTime_ECU" SG_ 2566912561 WorkLight10LeftCmd 5000;
BA_ "GenSigSendType" SG_ 2566912561 WorkLight10LeftCmd 0;
BA_ "GenSigTimeoutTime_ECU" SG_ 2566912561 WorkLight13LeftCmd 5000;
BA_ "GenSigSendType" SG_ 2566912561 WorkLight13LeftCmd 0;
BA_ "GenSigTimeoutTime_ECU" SG_ 2566912561 WorkLight22LeftCmd 5000;
BA_ "GenSigSendType" SG_ 2566912561 WorkLight22LeftCmd 0;
BA_ "GenSigTimeoutTime_ECU" SG_ 2566912561 WorkLight1RightCmd 5000;
BA_ "GenSigSendType" SG_ 2566912561 WorkLight1RightCmd 0;
BA_ "GenSigTimeoutTime_ECU" SG_ 2566912561 WorkLight4RightCmd 5000;
BA_ "GenSigSendType" SG_ 2566912561 WorkLight4RightCmd 0;
BA_ "GenSigTimeoutTime_ECU" SG_ 2566912561 WorkLight9RightCmd 5000;
BA_ "GenSigSendType" SG_ 2566912561 WorkLight9RightCmd 0;
BA_ "GenSigTimeoutTime_ECU" SG_ 2566912561 WorkLight10RightCmd 5000;
BA_ "GenSigSendType" SG_ 2566912561 WorkLight10RightCmd 0;
BA_ "GenSigTimeoutTime_ECU" SG_ 2566912561 WorkLight13RightCmd 5000;
BA_ "GenSigSendType" SG_ 2566912561 WorkLight13RightCmd 0;
BA_ "GenSigTimeoutTime_ECU" SG_ 2566912561 WorkLight19RightCmd 5000;
BA_ "GenSigSendType" SG_ 2566912561 WorkLight19RightCmd 0;
BA_ "GenSigTimeoutTime_ECU" SG_ 2566912561 WorkLight20RightCmd 5000;
BA_ "GenSigSendType" SG_ 2566912561 WorkLight20RightCmd 0;
BA_ "GenSigTimeoutTime_ECU" SG_ 2566912561 WorkLight21RightCmd 5000;
BA_ "GenSigSendType" SG_ 2566912561 WorkLight21RightCmd 0;
BA_ "GenSigTimeoutTime_ECU" SG_ 2566912561 WorkLight22RightCmd 5000;
BA_ "GenSigSendType" SG_ 2566912561 WorkLight22RightCmd 0;
BA_ "GenSigTimeoutTime_ECU" SG_ 2566912561 FrshAirIntTempAct 5000;
BA_ "GenSigSendType" SG_ 2566912561 FrshAirIntTempAct 0;
BA_ "GenSigTimeoutTime_ECU" SG_ 2634021118 CmdBytePGN65528_Vector_XXX 5000;
BA_ "GenSigTimeoutTime_ECU" SG_ 2634021118 AftrtrtmntSCRObsNOxCnvrsnEff 5000;
BA_ "GenSigSendType" SG_ 2634021118 AftrtrtmntSCRObsNOxCnvrsnEff 0;
BA_ "GenSigTimeoutTime_ECU" SG_ 2634021118 AftrtrtmntOutNOxTailCnt 5000;
BA_ "GenSigSendType" SG_ 2634021118 AftrtrtmntOutNOxTailCnt 0;
BA_ "GenSigTimeoutTime_ECU" SG_ 2634021118 SCRNOXCEMonState 5000;
BA_ "GenSigSendType" SG_ 2634021118 SCRNOXCEMonState 0;
BA_ "GenSigTimeoutTime_ECU" SG_ 2634021118 SCRAdapConDisable 5000;
BA_ "GenSigSendType" SG_ 2634021118 SCRAdapConDisable 0;
BA_ "GenSigTimeoutTime_ECU" SG_ 2634021118 SCRAdapConAdjFactor 5000;
BA_ "GenSigSendType" SG_ 2634021118 SCRAdapConAdjFactor 0;
BA_ "GenSigTimeoutTime_ECU" SG_ 2499803902 CmdBytePGN65530_Vector_XXX 5000;
BA_ "GenSigTimeoutTime_ECU" SG_ 2499803902 RawMedianVoltage 5000;
BA_ "GenSigSendType" SG_ 2499803902 RawMedianVoltage 0;
BA_ "GenSigTimeoutTime_ECU" SG_ 2499803902 RawMeanVoltage 5000;
BA_ "GenSigSendType" SG_ 2499803902 RawMeanVoltage 0;
BA_ "GenSigTimeoutTime_ECU" SG_ 2499803902 RawSupplyVoltage 5000;
BA_ "GenSigSendType" SG_ 2499803902 RawSupplyVoltage 0;
BA_ "GenSigTimeoutTime_ECU" SG_ 2499803902 PTWEstimatedWeight 5000;
BA_ "GenSigSendType" SG_ 2499803902 PTWEstimatedWeight 0;
BA_ "GenSigTimeoutTime_ECU" SG_ 2499803902 ActiveYieldWeight 5000;
BA_ "GenSigSendType" SG_ 2499803902 ActiveYieldWeight 0;
BA_ "GenSigTimeoutTime_ECU" SG_ 2499803902 ManualCalWeight 5000;
BA_ "GenSigSendType" SG_ 2499803902 ManualCalWeight 0;
BA_ "GenSigTimeoutTime_ECU" SG_ 2499803902 ForeMateRelaDispValu 5000;
BA_ "GenSigSendType" SG_ 2499803902 ForeMateRelaDispValu 0;
BA_ "GenSigTimeoutTime_ECU" SG_ 2499803902 BrokGraiRelaDispValu 5000;
BA_ "GenSigSendType" SG_ 2499803902 BrokGraiRelaDispValu 0;
BA_ "GenSigTimeoutTime_ECU" SG_ 2499803902 IC2SeveritySeparatorLoss 5000;
BA_ "GenSigSendType" SG_ 2499803902 IC2SeveritySeparatorLoss 0;
BA_ "GenSigTimeoutTime_ECU" SG_ 2499803902 IC2SeverityShoeLoss 5000;
BA_ "GenSigSendType" SG_ 2499803902 IC2SeverityShoeLoss 0;
BA_ "GenSigTimeoutTime_ECU" SG_ 2499803902 IC2SeverityDamagedGrain 5000;
BA_ "GenSigSendType" SG_ 2499803902 IC2SeverityDamagedGrain 0;
BA_ "GenSigTimeoutTime_ECU" SG_ 2499803902 IC2SeverityMOGLight 5000;
BA_ "GenSigSendType" SG_ 2499803902 IC2SeverityMOGLight 0;
BA_ "GenSigTimeoutTime_ECU" SG_ 2499803902 IC2SeverityMOGHeavy 5000;
BA_ "GenSigSendType" SG_ 2499803902 IC2SeverityMOGHeavy 0;
BA_ "GenSigTimeoutTime_ECU" SG_ 2499803902 IC2SeverityUnthrGrain 5000;
BA_ "GenSigSendType" SG_ 2499803902 IC2SeverityUnthrGrain 0;
BA_ "GenSigTimeoutTime_ECU" SG_ 2499803902 LeftAttaFramPresSens 5000;
BA_ "GenSigSendType" SG_ 2499803902 LeftAttaFramPresSens 0;
BA_ "GenSigTimeoutTime_ECU" SG_ 2499803902 RighAttaFramPresSens 5000;
BA_ "GenSigSendType" SG_ 2499803902 RighAttaFramPresSens 0;
BA_ "GenSigTimeoutTime_ECU" SG_ 2499803902 AttachmentFrameServiceStatus 5000;
BA_ "GenSigSendType" SG_ 2499803902 AttachmentFrameServiceStatus 0;
BA_ "GenSigTimeoutTime_ECU" SG_ 2499803902 IC2SeverityMassflow 5000;
BA_ "GenSigSendType" SG_ 2499803902 IC2SeverityMassflow 0;
BA_ "GenSigTimeoutTime_ECU" SG_ 2499803902 SOExhaustedStateModel 5000;
BA_ "GenSigSendType" SG_ 2499803902 SOExhaustedStateModel 0;
BA_ "GenSigTimeoutTime_ECU" SG_ 2499803902 SOStableStatus 5000;
BA_ "GenSigSendType" SG_ 2499803902 SOStableStatus 0;
BA_ "GenSigTimeoutTime_ECU" SG_ 2499803902 LeftWingPressureSensor 5000;
BA_ "GenSigSendType" SG_ 2499803902 LeftWingPressureSensor 0;
BA_ "GenSigTimeoutTime_ECU" SG_ 2499803902 RightWingPressureSensor 5000;
BA_ "GenSigSendType" SG_ 2499803902 RightWingPressureSensor 0;
BA_ "GenSigTimeoutTime_ECU" SG_ 2499803902 LeftWingServiceStatus 5000;
BA_ "GenSigSendType" SG_ 2499803902 LeftWingServiceStatus 0;
BA_ "GenSigTimeoutTime_ECU" SG_ 2499803902 RightWingServiceStatus 5000;
BA_ "GenSigSendType" SG_ 2499803902 RightWingServiceStatus 0;
BA_ "GenSigTimeoutTime_ECU" SG_ 2499803902 Filter1MOGLightAdjusted 5000;
BA_ "GenSigSendType" SG_ 2499803902 Filter1MOGLightAdjusted 0;
BA_ "GenSigTimeoutTime_ECU" SG_ 2499803902 Filter1MOGHeavyAdjusted 5000;
BA_ "GenSigSendType" SG_ 2499803902 Filter1MOGHeavyAdjusted 0;
BA_ "GenSigTimeoutTime_ECU" SG_ 2499803902 Filter1UnthreshedAdjusted 5000;
BA_ "GenSigSendType" SG_ 2499803902 Filter1UnthreshedAdjusted 0;
BA_ "GenSigTimeoutTime_ECU" SG_ 2499803902 ManualCalFactorInUse 5000;
BA_ "GenSigSendType" SG_ 2499803902 ManualCalFactorInUse 0;
BA_ "GenSigTimeoutTime_ECU" SG_ 2499803902 ActiveYieldCalFactorInUse 5000;
BA_ "GenSigSendType" SG_ 2499803902 ActiveYieldCalFactorInUse 0;
BA_ "GenSigTimeoutTime_ECU" SG_ 2499803902 SOAutoAdjustEnabled_CleaningFan 5000;
BA_ "GenSigSendType" SG_ 2499803902 SOAutoAdjustEnabled_CleaningFan 0;
BA_ "GenSigTimeoutTime_ECU" SG_ 2499803902 SOAutoAdjuEnabSievClea 5000;
BA_ "GenSigSendType" SG_ 2499803902 SOAutoAdjuEnabSievClea 0;
BA_ "GenSigTimeoutTime_ECU" SG_ 2499803902 SOAutoAdjuEnabChafClea 5000;
BA_ "GenSigSendType" SG_ 2499803902 SOAutoAdjuEnabChafClea 0;
BA_ "GenSigTimeoutTime_ECU" SG_ 2499803902 SOAutoAdjuEnabThreClea 5000;
BA_ "GenSigSendType" SG_ 2499803902 SOAutoAdjuEnabThreClea 0;
BA_ "GenSigTimeoutTime_ECU" SG_ 2499803902 SOAutoAdjuEnabThreSpee 5000;
BA_ "GenSigSendType" SG_ 2499803902 SOAutoAdjuEnabThreSpee 0;
BA_ "GenSigTimeoutTime_ECU" SG_ 2499803902 ReelCenterTubeFLPSysHealth 5000;
BA_ "GenSigSendType" SG_ 2499803902 ReelCenterTubeFLPSysHealth 0;
BA_ "GenSigTimeoutTime_ECU" SG_ 2499803902 NmbrCalLoads 5000;
BA_ "GenSigSendType" SG_ 2499803902 NmbrCalLoads 0;
BA_ "GenSigTimeoutTime_ECU" SG_ 2499803902 MsgSeqIndex 5000;
BA_ "GenSigSendType" SG_ 2499803902 MsgSeqIndex 0;
BA_ "GenSigTimeoutTime_ECU" SG_ 2499803902 CalLoadDesignator 5000;
BA_ "GenSigSendType" SG_ 2499803902 CalLoadDesignator 0;
BA_ "GenSigTimeoutTime_ECU" SG_ 2499803902 CalLoadSelected 5000;
BA_ "GenSigSendType" SG_ 2499803902 CalLoadSelected 0;
BA_ "GenSigTimeoutTime_ECU" SG_ 2499803902 YldMonForceSum 5000;
BA_ "GenSigSendType" SG_ 2499803902 YldMonForceSum 0;
BA_ "GenSigTimeoutTime_ECU" SG_ 2499803902 YldMonDeltaT 5000;
BA_ "GenSigSendType" SG_ 2499803902 YldMonDeltaT 0;
BA_ "GenSigTimeoutTime_ECU" SG_ 2499803902 AutoDeckplateEnable 5000;
BA_ "GenSigSendType" SG_ 2499803902 AutoDeckplateEnable 0;
BA_ "GenSigTimeoutTime_ECU" SG_ 2499803902 AutoDeckplateCmdFromHCU 5000;
BA_ "GenSigSendType" SG_ 2499803902 AutoDeckplateCmdFromHCU 0;
BA_ "GenSigTimeoutTime_ECU" SG_ 2499803902 HdrAutomationFeaturesStatus 5000;
BA_ "GenSigSendType" SG_ 2499803902 HdrAutomationFeaturesStatus 0;
BA_ "GenSigTimeoutTime_ECU" SG_ 2499803902 AutoDeckPlatTighLeveFromHCU 5000;
BA_ "GenSigSendType" SG_ 2499803902 AutoDeckPlatTighLeveFromHCU 0;
BA_ "GenSigTimeoutTime_ECU" SG_ 2499803902 AutoDeckPlateOptionInstalled 5000;
BA_ "GenSigSendType" SG_ 2499803902 AutoDeckPlateOptionInstalled 0;
BA_ "GenSigTimeoutTime_ECU" SG_ 2499803902 ForeignMaterialLimitData 5000;
BA_ "GenSigSendType" SG_ 2499803902 ForeignMaterialLimitData 0;
BA_ "GenSigTimeoutTime_ECU" SG_ 2499803902 BrokenGrainLimitData 5000;
BA_ "GenSigSendType" SG_ 2499803902 BrokenGrainLimitData 0;
BA_ "GenSigTimeoutTime_ECU" SG_ 2499803902 GrainLossRelativeDisplayedTotal 5000;
BA_ "GenSigSendType" SG_ 2499803902 GrainLossRelativeDisplayedTotal 0;
BA_ "GenSigTimeoutTime_ECU" SG_ 2499803902 TotalGrainLossAreaDefinedLimit 5000;
BA_ "GenSigSendType" SG_ 2499803902 TotalGrainLossAreaDefinedLimit 0;
BA_ "GenSigTimeoutTime_ECU" SG_ 2499803902 TotalGrainLossAreaFilter1 5000;
BA_ "GenSigSendType" SG_ 2499803902 TotalGrainLossAreaFilter1 0;
BA_ "GenSigTimeoutTime_ECU" SG_ 2499803902 TotalGrainLossMassDefinedLimit 5000;
BA_ "GenSigSendType" SG_ 2499803902 TotalGrainLossMassDefinedLimit 0;
BA_ "GenSigTimeoutTime_ECU" SG_ 2499803902 TotalGrainLossMassFilter1 5000;
BA_ "GenSigSendType" SG_ 2499803902 TotalGrainLossMassFilter1 0;
BA_ "GenSigTimeoutTime_ECU" SG_ 2499803902 SDAStatusLED_GSA_Sense 5000;
BA_ "GenSigSendType" SG_ 2499803902 SDAStatusLED_GSA_Sense 0;
BA_ "GenSigTimeoutTime_ECU" SG_ 2499803902 SDAStatusLED_GSA_Decide 5000;
BA_ "GenSigSendType" SG_ 2499803902 SDAStatusLED_GSA_Decide 0;
BA_ "GenSigTimeoutTime_ECU" SG_ 2499803902 SDAStatusLED_GSA_Act 5000;
BA_ "GenSigSendType" SG_ 2499803902 SDAStatusLED_GSA_Act 0;
BA_ "GenSigTimeoutTime_ECU" SG_ 2499803902 SDAStatusLED_HSA_Sense 5000;
BA_ "GenSigSendType" SG_ 2499803902 SDAStatusLED_HSA_Sense 0;
BA_ "GenSigTimeoutTime_ECU" SG_ 2499803902 SDAStatusLED_HSA_Decide 5000;
BA_ "GenSigSendType" SG_ 2499803902 SDAStatusLED_HSA_Decide 0;
BA_ "GenSigTimeoutTime_ECU" SG_ 2499803902 SDAStatusLED_HSA_Act 5000;
BA_ "GenSigSendType" SG_ 2499803902 SDAStatusLED_HSA_Act 0;
BA_ "GenSigTimeoutTime_ECU" SG_ 2499803902 SDAStatusLED_TSA_Sense 5000;
BA_ "GenSigSendType" SG_ 2499803902 SDAStatusLED_TSA_Sense 0;
BA_ "GenSigTimeoutTime_ECU" SG_ 2499803902 SDAStatusLED_TSA_Decide 5000;
BA_ "GenSigSendType" SG_ 2499803902 SDAStatusLED_TSA_Decide 0;
BA_ "GenSigTimeoutTime_ECU" SG_ 2499803902 SDAStatusLED_TSA_Act 5000;
BA_ "GenSigSendType" SG_ 2499803902 SDAStatusLED_TSA_Act 0;
BA_ "GenSigTimeoutTime_ECU" SG_ 2499803902 ThreshingConditionModifier 5000;
BA_ "GenSigSendType" SG_ 2499803902 ThreshingConditionModifier 0;
BA_ "GenSigTimeoutTime_ECU" SG_ 2499803902 StrawConditionModifier 5000;
BA_ "GenSigSendType" SG_ 2499803902 StrawConditionModifier 0;
BA_ "GenMsgCycleTime" BO_ 2565406513 60000;
BA_ "SingleFrame" BO_ 2565406513 1;
BA_ "GenMsgCycleTime" BO_ 2565406664 60000;
BA_ "SingleFrame" BO_ 2565406664 1;
BA_ "GenMsgCycleTime" BO_ 2565406698 60000;
BA_ "SingleFrame" BO_ 2565406698 1;
BA_ "GenMsgCycleTime" BO_ 2565406699 60000;
BA_ "SingleFrame" BO_ 2565406699 1;
BA_ "GenMsgCycleTime" BO_ 2565406555 60000;
BA_ "SingleFrame" BO_ 2565406555 1;
BA_ "GenMsgCycleTime" BO_ 2565392433 60000;
BA_ "SingleFrame" BO_ 2565392433 1;
BA_ "GenMsgCycleTime" BO_ 2565401137 60000;
BA_ "SingleFrame" BO_ 2565401137 1;
BA_ "GenMsgCycleTime" BO_ 2565401393 60000;
BA_ "SingleFrame" BO_ 2565401393 1;
BA_ "GenMsgCycleTime" BO_ 2565364529 60000;
BA_ "SingleFrame" BO_ 2565364529 1;
BA_ "GenMsgCycleTime" BO_ 2565353928 60000;
BA_ "SingleFrame" BO_ 2565353928 1;
BA_ "GenMsgCycleTime" BO_ 2565401288 60000;
BA_ "SingleFrame" BO_ 2565401288 1;
BA_ "GenMsgCycleTime" BO_ 2565401544 60000;
BA_ "SingleFrame" BO_ 2565401544 1;
BA_ "GenMsgCycleTime" BO_ 2565364680 60000;
BA_ "SingleFrame" BO_ 2565364680 1;
BA_ "GenMsgCycleTime" BO_ 2565353962 60000;
BA_ "SingleFrame" BO_ 2565353962 1;
BA_ "GenMsgCycleTime" BO_ 2565392618 60000;
BA_ "SingleFrame" BO_ 2565392618 1;
BA_ "GenMsgCycleTime" BO_ 2565401578 60000;
BA_ "SingleFrame" BO_ 2565401578 1;
BA_ "GenMsgCycleTime" BO_ 2565364714 60000;
BA_ "SingleFrame" BO_ 2565364714 1;
BA_ "GenMsgCycleTime" BO_ 2565353963 60000;
BA_ "SingleFrame" BO_ 2565353963 1;
BA_ "GenMsgCycleTime" BO_ 2565392619 60000;
BA_ "SingleFrame" BO_ 2565392619 1;
BA_ "GenMsgCycleTime" BO_ 2565401323 60000;
BA_ "SingleFrame" BO_ 2565401323 1;
BA_ "GenMsgCycleTime" BO_ 2565364715 60000;
BA_ "SingleFrame" BO_ 2565364715 1;
BA_ "GenMsgCycleTime" BO_ 2565353819 60000;
BA_ "SingleFrame" BO_ 2565353819 1;
BA_ "GenMsgCycleTime" BO_ 2565392475 60000;
BA_ "SingleFrame" BO_ 2565392475 1;
BA_ "GenMsgCycleTime" BO_ 2565401179 60000;
BA_ "SingleFrame" BO_ 2565401179 1;
BA_ "GenMsgCycleTime" BO_ 2565401435 60000;
BA_ "SingleFrame" BO_ 2565401435 1;
BA_ "GenMsgCycleTime" BO_ 2565799729 60000;
BA_ "SingleFrame" BO_ 2565799729 1;
BA_ "GenMsgCycleTime" BO_ 2565799880 60000;
BA_ "SingleFrame" BO_ 2565799880 1;
BA_ "GenMsgCycleTime" BO_ 2565799914 60000;
BA_ "SingleFrame" BO_ 2565799914 1;
BA_ "GenMsgCycleTime" BO_ 2565799915 60000;
BA_ "SingleFrame" BO_ 2565799915 1;
BA_ "GenMsgCycleTime" BO_ 2565799771 60000;
BA_ "SingleFrame" BO_ 2565799771 1;
BA_ "GenMsgCycleTime" BO_ 2566757374 1000;
BA_ "GenMsgSendType" BO_ 2566757374 0;
BA_ "GenMsgCycleTimeFast" BO_ 2566757374 1000;
BA_ "SingleFrame" BO_ 2566757374 1;
BA_ "GenMsgCycleTime" BO_ 2566805246 1000;
BA_ "GenMsgSendType" BO_ 2566805246 0;
BA_ "GenMsgCycleTimeFast" BO_ 2566805246 1000;
BA_ "SingleFrame" BO_ 2566805246 1;
BA_ "GenMsgCycleTime" BO_ 2566749182 60000;
BA_ "GenMsgSendType" BO_ 2566749182 0;
BA_ "GenMsgCycleTimeFast" BO_ 2566749182 100;
BA_ "SingleFrame" BO_ 2566749182 1;
BA_ "GenMsgCycleTime" BO_ 2566763518 500;
BA_ "GenMsgSendType" BO_ 2566763518 0;
BA_ "GenMsgCycleTimeFast" BO_ 2566763518 500;
BA_ "SingleFrame" BO_ 2566763518 1;
BA_ "GenMsgCycleTime" BO_ 2566700542 60000;
BA_ "GenMsgSendType" BO_ 2566700542 0;
BA_ "GenMsgCycleTimeFast" BO_ 2566700542 60000;
BA_ "SingleFrame" BO_ 2566700542 1;
BA_ "GenMsgCycleTime" BO_ 2565874686 50;
BA_ "GenMsgSendType" BO_ 2565874686 0;
BA_ "GenMsgCycleTimeFast" BO_ 2565874686 50;
BA_ "SingleFrame" BO_ 2565874686 1;
BA_ "GenMsgCycleTime" BO_ 2566845787 1000;
BA_ "GenMsgSendType" BO_ 2566845787 0;
BA_ "GenMsgCycleTimeFast" BO_ 2566845787 1000;
BA_ "SingleFrame" BO_ 2566845787 1;
BA_ "GenMsgCycleTime" BO_ 2564292401 60000;
BA_ "SingleFrame" BO_ 2564292401 1;
BA_ "GenMsgCycleTime" BO_ 2628399614 60000;
BA_ "GenMsgSendType" BO_ 2628399614 0;
BA_ "GenMsgCycleTimeFast" BO_ 2628399614 60000;
BA_ "SingleFrame" BO_ 2628399614 1;
BA_ "GenMsgCycleTime" BO_ 2628438270 60000;
BA_ "GenMsgSendType" BO_ 2628438270 0;
BA_ "GenMsgCycleTimeFast" BO_ 2628438270 60000;
BA_ "SingleFrame" BO_ 2628438270 1;
BA_ "GenMsgCycleTime" BO_ 2628446974 60000;
BA_ "GenMsgSendType" BO_ 2628446974 0;
BA_ "GenMsgCycleTimeFast" BO_ 2628446974 60000;
BA_ "SingleFrame" BO_ 2628446974 1;
BA_ "GenMsgCycleTime" BO_ 2628447230 60000;
BA_ "GenMsgSendType" BO_ 2628447230 0;
BA_ "GenMsgCycleTimeFast" BO_ 2628447230 60000;
BA_ "SingleFrame" BO_ 2628447230 1;
BA_ "GenMsgCycleTime" BO_ 2628410366 60000;
BA_ "GenMsgSendType" BO_ 2628410366 0;
BA_ "GenMsgCycleTimeFast" BO_ 2628410366 60000;
BA_ "SingleFrame" BO_ 2628410366 1;
BA_ "GenMsgCycleTime" BO_ 2628452350 60000;
BA_ "GenMsgSendType" BO_ 2628452350 0;
BA_ "GenMsgCycleTimeFast" BO_ 2628452350 60000;
BA_ "SingleFrame" BO_ 2628452350 1;
BA_ "GenMsgCycleTime" BO_ 2432635995 100;
BA_ "GenMsgSendType" BO_ 2432635995 0;
BA_ "GenMsgCycleTimeFast" BO_ 2432635995 100;
BA_ "SingleFrame" BO_ 2432635995 1;
BA_ "GenMsgCycleTime" BO_ 2566838321 60000;
BA_ "GenMsgCycleTime" BO_ 2566838472 60000;
BA_ "GenMsgCycleTime" BO_ 2566838506 60000;
BA_ "GenMsgCycleTime" BO_ 2566838507 60000;
BA_ "GenMsgCycleTime" BO_ 2566838363 60000;
BA_ "GenMsgCycleTime" BO_ 2298409307 100;
BA_ "GenMsgSendType" BO_ 2298409307 0;
BA_ "GenMsgCycleTimeFast" BO_ 2298409307 100;
BA_ "SingleFrame" BO_ 2298409307 1;
BA_ "GenMsgCycleTime" BO_ 2499738715 1000;
BA_ "GenMsgSendType" BO_ 2499738715 0;
BA_ "GenMsgCycleTimeFast" BO_ 2499738715 1000;
BA_ "SingleFrame" BO_ 2499738715 1;
BA_ "GenMsgCycleTime" BO_ 2566850865 60000;
BA_ "SingleFrame" BO_ 2566850865 1;
BA_ "GenMsgCycleTime" BO_ 2566851016 60000;
BA_ "SingleFrame" BO_ 2566851016 1;
BA_ "GenMsgCycleTime" BO_ 2566851050 60000;
BA_ "SingleFrame" BO_ 2566851050 1;
BA_ "GenMsgCycleTime" BO_ 2566851051 60000;
BA_ "SingleFrame" BO_ 2566851051 1;
BA_ "GenMsgCycleTime" BO_ 2566850907 60000;
BA_ "SingleFrame" BO_ 2566850907 1;
BA_ "GenMsgCycleTime" BO_ 2566730440 60000;
BA_ "SingleFrame" BO_ 2566730440 1;
BA_ "GenMsgCycleTime" BO_ 2566730474 60000;
BA_ "SingleFrame" BO_ 2566730474 1;
BA_ "GenMsgCycleTime" BO_ 2566730475 60000;
BA_ "SingleFrame" BO_ 2566730475 1;
BA_ "GenMsgCycleTime" BO_ 2566730331 60000;
BA_ "SingleFrame" BO_ 2566730331 1;
BA_ "GenMsgCycleTime" BO_ 2562719537 60000;
BA_ "SingleFrame" BO_ 2562719537 1;
BA_ "GenMsgCycleTime" BO_ 2562719722 60000;
BA_ "SingleFrame" BO_ 2562719722 1;
BA_ "GenMsgCycleTime" BO_ 2562719723 60000;
BA_ "SingleFrame" BO_ 2562719723 1;
BA_ "GenMsgCycleTime" BO_ 2562719579 60000;
BA_ "SingleFrame" BO_ 2562719579 1;
BA_ "GenMsgCycleTime" BO_ 2566749438 1000;
BA_ "GenMsgSendType" BO_ 2566749438 0;
BA_ "GenMsgCycleTimeFast" BO_ 2566749438 1000;
BA_ "SingleFrame" BO_ 2566749438 1;
BA_ "GenMsgCycleTime" BO_ 2566719270 1000;
BA_ "GenMsgSendType" BO_ 2566719270 0;
BA_ "GenMsgCycleTimeFast" BO_ 2566719270 100;
BA_ "SingleFrame" BO_ 2566719270 1;
BA_ "GenMsgCycleTime" BO_ 2566837041 60000;
BA_ "SingleFrame" BO_ 2566837041 1;
BA_ "GenMsgCycleTime" BO_ 2566837192 60000;
BA_ "SingleFrame" BO_ 2566837192 1;
BA_ "GenMsgCycleTime" BO_ 2566837226 60000;
BA_ "SingleFrame" BO_ 2566837226 1;
BA_ "GenMsgCycleTime" BO_ 2566837227 60000;
BA_ "SingleFrame" BO_ 2566837227 1;
BA_ "GenMsgCycleTime" BO_ 2566837083 60000;
BA_ "SingleFrame" BO_ 2566837083 1;
BA_ "GenMsgCycleTime" BO_ 2564816894 60000;
BA_ "GenMsgSendType" BO_ 2564816894 0;
BA_ "GenMsgCycleTimeFast" BO_ 2564816894 60000;
BA_ "SingleFrame" BO_ 2564816894 1;
BA_ "GenMsgCycleTime" BO_ 2566834737 60000;
BA_ "SingleFrame" BO_ 2566834737 1;
BA_ "GenMsgCycleTime" BO_ 2566834888 60000;
BA_ "SingleFrame" BO_ 2566834888 1;
BA_ "GenMsgCycleTime" BO_ 2566834922 60000;
BA_ "SingleFrame" BO_ 2566834922 1;
BA_ "GenMsgCycleTime" BO_ 2566834923 60000;
BA_ "SingleFrame" BO_ 2566834923 1;
BA_ "GenMsgCycleTime" BO_ 2566834779 60000;
BA_ "SingleFrame" BO_ 2566834779 1;
BA_ "GenMsgCycleTime" BO_ 2566834993 60000;
BA_ "SingleFrame" BO_ 2566834993 1;
BA_ "GenMsgCycleTime" BO_ 2566835144 60000;
BA_ "SingleFrame" BO_ 2566835144 1;
BA_ "GenMsgCycleTime" BO_ 2566835178 60000;
BA_ "SingleFrame" BO_ 2566835178 1;
BA_ "GenMsgCycleTime" BO_ 2566835179 60000;
BA_ "SingleFrame" BO_ 2566835179 1;
BA_ "GenMsgCycleTime" BO_ 2566835035 60000;
BA_ "SingleFrame" BO_ 2566835035 1;
BA_ "GenMsgCycleTime" BO_ 2566835249 60000;
BA_ "SingleFrame" BO_ 2566835249 1;
BA_ "GenMsgCycleTime" BO_ 2566835400 60000;
BA_ "SingleFrame" BO_ 2566835400 1;
BA_ "GenMsgCycleTime" BO_ 2566835434 60000;
BA_ "SingleFrame" BO_ 2566835434 1;
BA_ "GenMsgCycleTime" BO_ 2566835435 60000;
BA_ "SingleFrame" BO_ 2566835435 1;
BA_ "GenMsgCycleTime" BO_ 2566835291 60000;
BA_ "SingleFrame" BO_ 2566835291 1;
BA_ "GenMsgCycleTime" BO_ 2566835690 60000;
BA_ "GenMsgCycleTime" BO_ 2566835691 60000;
BA_ "GenMsgCycleTime" BO_ 2566835547 60000;
BA_ "GenMsgCycleTime" BO_ 2566835761 60000;
BA_ "SingleFrame" BO_ 2566835761 1;
BA_ "GenMsgCycleTime" BO_ 2566835912 60000;
BA_ "SingleFrame" BO_ 2566835912 1;
BA_ "GenMsgCycleTime" BO_ 2566835946 60000;
BA_ "SingleFrame" BO_ 2566835946 1;
BA_ "GenMsgCycleTime" BO_ 2566835947 60000;
BA_ "SingleFrame" BO_ 2566835947 1;
BA_ "GenMsgCycleTime" BO_ 2566835803 60000;
BA_ "SingleFrame" BO_ 2566835803 1;
BA_ "GenMsgCycleTime" BO_ 2566767921 60000;
BA_ "SingleFrame" BO_ 2566767921 1;
BA_ "GenMsgCycleTime" BO_ 2566768072 60000;
BA_ "SingleFrame" BO_ 2566768072 1;
BA_ "GenMsgCycleTime" BO_ 2566768106 60000;
BA_ "SingleFrame" BO_ 2566768106 1;
BA_ "GenMsgCycleTime" BO_ 2566768107 60000;
BA_ "SingleFrame" BO_ 2566768107 1;
BA_ "GenMsgCycleTime" BO_ 2566768088 60000;
BA_ "GenMsgSendType" BO_ 2566768088 0;
BA_ "GenMsgCycleTimeFast" BO_ 2566768088 60000;
BA_ "SingleFrame" BO_ 2566768088 1;
BA_ "GenMsgCycleTime" BO_ 2566767963 60000;
BA_ "SingleFrame" BO_ 2566767963 1;
BA_ "GenMsgCycleTime" BO_ 2565326897 60000;
BA_ "SingleFrame" BO_ 2565326897 1;
BA_ "GenMsgCycleTime" BO_ 2565335601 60000;
BA_ "SingleFrame" BO_ 2565335601 1;
BA_ "GenMsgCycleTime" BO_ 2565335857 60000;
BA_ "SingleFrame" BO_ 2565335857 1;
BA_ "GenMsgCycleTime" BO_ 2565298993 60000;
BA_ "SingleFrame" BO_ 2565298993 1;
BA_ "GenMsgCycleTime" BO_ 2565288392 60000;
BA_ "SingleFrame" BO_ 2565288392 1;
BA_ "GenMsgCycleTime" BO_ 2565335752 60000;
BA_ "SingleFrame" BO_ 2565335752 1;
BA_ "GenMsgCycleTime" BO_ 2565336008 60000;
BA_ "SingleFrame" BO_ 2565336008 1;
BA_ "GenMsgCycleTime" BO_ 2565299144 60000;
BA_ "SingleFrame" BO_ 2565299144 1;
BA_ "GenMsgCycleTime" BO_ 2565288426 60000;
BA_ "SingleFrame" BO_ 2565288426 1;
BA_ "GenMsgCycleTime" BO_ 2565327082 60000;
BA_ "SingleFrame" BO_ 2565327082 1;
BA_ "GenMsgCycleTime" BO_ 2565336042 60000;
BA_ "SingleFrame" BO_ 2565336042 1;
BA_ "GenMsgCycleTime" BO_ 2565299178 60000;
BA_ "SingleFrame" BO_ 2565299178 1;
BA_ "GenMsgCycleTime" BO_ 2565288427 60000;
BA_ "SingleFrame" BO_ 2565288427 1;
BA_ "GenMsgCycleTime" BO_ 2565327083 60000;
BA_ "SingleFrame" BO_ 2565327083 1;
BA_ "GenMsgCycleTime" BO_ 2565335787 60000;
BA_ "SingleFrame" BO_ 2565335787 1;
BA_ "GenMsgCycleTime" BO_ 2565299179 60000;
BA_ "SingleFrame" BO_ 2565299179 1;
BA_ "GenMsgCycleTime" BO_ 2565288283 60000;
BA_ "SingleFrame" BO_ 2565288283 1;
BA_ "GenMsgCycleTime" BO_ 2565326939 60000;
BA_ "SingleFrame" BO_ 2565326939 1;
BA_ "GenMsgCycleTime" BO_ 2565335643 60000;
BA_ "SingleFrame" BO_ 2565335643 1;
BA_ "GenMsgCycleTime" BO_ 2565335899 60000;
BA_ "SingleFrame" BO_ 2565335899 1;
BA_ "GenMsgCycleTime" BO_ 2565340977 60000;
BA_ "SingleFrame" BO_ 2565340977 1;
BA_ "GenMsgCycleTime" BO_ 2565341128 60000;
BA_ "SingleFrame" BO_ 2565341128 1;
BA_ "GenMsgCycleTime" BO_ 2565341162 60000;
BA_ "SingleFrame" BO_ 2565341162 1;
BA_ "GenMsgCycleTime" BO_ 2565341163 60000;
BA_ "SingleFrame" BO_ 2565341163 1;
BA_ "GenMsgCycleTime" BO_ 2565341019 60000;
BA_ "SingleFrame" BO_ 2565341019 1;
BA_ "GenMsgCycleTime" BO_ 2364539995 20;
BA_ "GenMsgSendType" BO_ 2364539995 0;
BA_ "GenMsgCycleTimeFast" BO_ 2364539995 20;
BA_ "SingleFrame" BO_ 2364539995 1;
BA_ "GenMsgCycleTime" BO_ 2364539902 50;
BA_ "GenMsgSendType" BO_ 2364539902 0;
BA_ "GenMsgCycleTimeFast" BO_ 2364539902 50;
BA_ "SingleFrame" BO_ 2364539902 1;
BA_ "GenMsgCycleTime" BO_ 2566840318 100;
BA_ "GenMsgSendType" BO_ 2566840318 0;
BA_ "GenMsgCycleTimeFast" BO_ 2566840318 100;
BA_ "SingleFrame" BO_ 2566840318 1;
BA_ "GenMsgCycleTime" BO_ 2662541034 60000;
BA_ "GenMsgCycleTime" BO_ 2662591014 60000;
BA_ "GenMsgCycleTime" BO_ 2662596586 60000;
BA_ "GenMsgCycleTime" BO_ 2662596390 60000;
BA_ "GenMsgCycleTime" BO_ 2566844414 500;
BA_ "GenMsgSendType" BO_ 2566844414 0;
BA_ "GenMsgCycleTimeFast" BO_ 2566844414 500;
BA_ "SingleFrame" BO_ 2566844414 1;
BA_ "GenMsgCycleTime" BO_ 2566841854 60000;
BA_ "GenMsgSendType" BO_ 2566841854 0;
BA_ "GenMsgCycleTimeFast" BO_ 2566841854 60000;
BA_ "SingleFrame" BO_ 2566841854 1;
BA_ "GenMsgCycleTime" BO_ 2566843995 1000;
BA_ "GenMsgSendType" BO_ 2566843995 0;
BA_ "GenMsgCycleTimeFast" BO_ 2566843995 1000;
BA_ "SingleFrame" BO_ 2566843995 1;
BA_ "GenMsgCycleTime" BO_ 2432537179 250;
BA_ "GenMsgSendType" BO_ 2432537179 0;
BA_ "GenMsgCycleTimeFast" BO_ 2432537179 100;
BA_ "SingleFrame" BO_ 2432537179 1;
BA_ "GenMsgCycleTime" BO_ 2431708465 1000;
BA_ "GenMsgSendType" BO_ 2431708465 0;
BA_ "GenMsgCycleTimeFast" BO_ 2431708465 100;
BA_ "SingleFrame" BO_ 2431708465 1;
BA_ "GenMsgCycleTime" BO_ 2431708651 1000;
BA_ "GenMsgSendType" BO_ 2431708651 0;
BA_ "GenMsgCycleTimeFast" BO_ 2431708651 100;
BA_ "SingleFrame" BO_ 2431708651 1;
BA_ "GenMsgCycleTime" BO_ 2431708507 1000;
BA_ "GenMsgSendType" BO_ 2431708507 0;
BA_ "GenMsgCycleTimeFast" BO_ 2431708507 100;
BA_ "SingleFrame" BO_ 2431708507 1;
BA_ "GenMsgCycleTime" BO_ 2566809947 1000;
BA_ "GenMsgSendType" BO_ 2566809947 0;
BA_ "GenMsgCycleTimeFast" BO_ 2566809947 1000;
BA_ "SingleFrame" BO_ 2566809947 1;
BA_ "GenMsgCycleTime" BO_ 2563309361 60000;
BA_ "SingleFrame" BO_ 2563309361 1;
BA_ "GenMsgCycleTime" BO_ 2563309512 60000;
BA_ "SingleFrame" BO_ 2563309512 1;
BA_ "GenMsgCycleTime" BO_ 2563309546 60000;
BA_ "SingleFrame" BO_ 2563309546 1;
BA_ "GenMsgCycleTime" BO_ 2563309547 60000;
BA_ "SingleFrame" BO_ 2563309547 1;
BA_ "GenMsgCycleTime" BO_ 2563309403 60000;
BA_ "SingleFrame" BO_ 2563309403 1;
BA_ "GenMsgCycleTime" BO_ 2563295281 60000;
BA_ "SingleFrame" BO_ 2563295281 1;
BA_ "GenMsgCycleTime" BO_ 2563303985 60000;
BA_ "SingleFrame" BO_ 2563303985 1;
BA_ "GenMsgCycleTime" BO_ 2563304241 60000;
BA_ "SingleFrame" BO_ 2563304241 1;
BA_ "GenMsgCycleTime" BO_ 2563267377 60000;
BA_ "SingleFrame" BO_ 2563267377 1;
BA_ "GenMsgCycleTime" BO_ 2563256776 60000;
BA_ "SingleFrame" BO_ 2563256776 1;
BA_ "GenMsgCycleTime" BO_ 2563304136 60000;
BA_ "SingleFrame" BO_ 2563304136 1;
BA_ "GenMsgCycleTime" BO_ 2563304392 60000;
BA_ "SingleFrame" BO_ 2563304392 1;
BA_ "GenMsgCycleTime" BO_ 2563267528 60000;
BA_ "SingleFrame" BO_ 2563267528 1;
BA_ "GenMsgCycleTime" BO_ 2563256810 60000;
BA_ "SingleFrame" BO_ 2563256810 1;
BA_ "GenMsgCycleTime" BO_ 2563295466 60000;
BA_ "SingleFrame" BO_ 2563295466 1;
BA_ "GenMsgCycleTime" BO_ 2563304426 60000;
BA_ "SingleFrame" BO_ 2563304426 1;
BA_ "GenMsgCycleTime" BO_ 2563267562 60000;
BA_ "SingleFrame" BO_ 2563267562 1;
BA_ "GenMsgCycleTime" BO_ 2563256811 60000;
BA_ "SingleFrame" BO_ 2563256811 1;
BA_ "GenMsgCycleTime" BO_ 2563295467 60000;
BA_ "SingleFrame" BO_ 2563295467 1;
BA_ "GenMsgCycleTime" BO_ 2563304171 60000;
BA_ "SingleFrame" BO_ 2563304171 1;
BA_ "GenMsgCycleTime" BO_ 2563267563 60000;
BA_ "SingleFrame" BO_ 2563267563 1;
BA_ "GenMsgCycleTime" BO_ 2563256667 60000;
BA_ "SingleFrame" BO_ 2563256667 1;
BA_ "GenMsgCycleTime" BO_ 2563295323 60000;
BA_ "SingleFrame" BO_ 2563295323 1;
BA_ "GenMsgCycleTime" BO_ 2563304027 60000;
BA_ "SingleFrame" BO_ 2563304027 1;
BA_ "GenMsgCycleTime" BO_ 2563304283 60000;
BA_ "SingleFrame" BO_ 2563304283 1;
BA_ "GenMsgCycleTime" BO_ 2563243825 60000;
BA_ "SingleFrame" BO_ 2563243825 1;
BA_ "GenMsgCycleTime" BO_ 2563243976 60000;
BA_ "SingleFrame" BO_ 2563243976 1;
BA_ "GenMsgCycleTime" BO_ 2563244010 60000;
BA_ "SingleFrame" BO_ 2563244010 1;
BA_ "GenMsgCycleTime" BO_ 2563244011 60000;
BA_ "SingleFrame" BO_ 2563244011 1;
BA_ "GenMsgCycleTime" BO_ 2563243867 60000;
BA_ "SingleFrame" BO_ 2563243867 1;
BA_ "GenMsgCycleTime" BO_ 2563229745 60000;
BA_ "SingleFrame" BO_ 2563229745 1;
BA_ "GenMsgCycleTime" BO_ 2563238449 60000;
BA_ "SingleFrame" BO_ 2563238449 1;
BA_ "GenMsgCycleTime" BO_ 2563238705 60000;
BA_ "SingleFrame" BO_ 2563238705 1;
BA_ "GenMsgCycleTime" BO_ 2563201841 60000;
BA_ "SingleFrame" BO_ 2563201841 1;
BA_ "GenMsgCycleTime" BO_ 2563191240 60000;
BA_ "SingleFrame" BO_ 2563191240 1;
BA_ "GenMsgCycleTime" BO_ 2563238600 60000;
BA_ "SingleFrame" BO_ 2563238600 1;
BA_ "GenMsgCycleTime" BO_ 2563238856 60000;
BA_ "SingleFrame" BO_ 2563238856 1;
BA_ "GenMsgCycleTime" BO_ 2563201992 60000;
BA_ "SingleFrame" BO_ 2563201992 1;
BA_ "GenMsgCycleTime" BO_ 2563191274 60000;
BA_ "SingleFrame" BO_ 2563191274 1;
BA_ "GenMsgCycleTime" BO_ 2563229930 60000;
BA_ "SingleFrame" BO_ 2563229930 1;
BA_ "GenMsgCycleTime" BO_ 2563238890 60000;
BA_ "SingleFrame" BO_ 2563238890 1;
BA_ "GenMsgCycleTime" BO_ 2563202026 60000;
BA_ "SingleFrame" BO_ 2563202026 1;
BA_ "GenMsgCycleTime" BO_ 2563191275 60000;
BA_ "SingleFrame" BO_ 2563191275 1;
BA_ "GenMsgCycleTime" BO_ 2563229931 60000;
BA_ "SingleFrame" BO_ 2563229931 1;
BA_ "GenMsgCycleTime" BO_ 2563238635 60000;
BA_ "SingleFrame" BO_ 2563238635 1;
BA_ "GenMsgCycleTime" BO_ 2563202027 60000;
BA_ "SingleFrame" BO_ 2563202027 1;
BA_ "GenMsgCycleTime" BO_ 2563191131 60000;
BA_ "SingleFrame" BO_ 2563191131 1;
BA_ "GenMsgCycleTime" BO_ 2563229787 60000;
BA_ "SingleFrame" BO_ 2563229787 1;
BA_ "GenMsgCycleTime" BO_ 2563238491 60000;
BA_ "SingleFrame" BO_ 2563238491 1;
BA_ "GenMsgCycleTime" BO_ 2563238747 60000;
BA_ "SingleFrame" BO_ 2563238747 1;
BA_ "GenMsgCycleTime" BO_ 2628517681 60000;
BA_ "SingleFrame" BO_ 2628517681 1;
BA_ "GenMsgCycleTime" BO_ 2628517832 60000;
BA_ "SingleFrame" BO_ 2628517832 1;
BA_ "GenMsgCycleTime" BO_ 2628517866 60000;
BA_ "SingleFrame" BO_ 2628517866 1;
BA_ "GenMsgCycleTime" BO_ 2628517867 60000;
BA_ "SingleFrame" BO_ 2628517867 1;
BA_ "GenMsgCycleTime" BO_ 2628517723 60000;
BA_ "SingleFrame" BO_ 2628517723 1;
BA_ "GenMsgCycleTime" BO_ 2628503601 60000;
BA_ "SingleFrame" BO_ 2628503601 1;
BA_ "GenMsgCycleTime" BO_ 2628512305 60000;
BA_ "SingleFrame" BO_ 2628512305 1;
BA_ "GenMsgCycleTime" BO_ 2628512561 60000;
BA_ "SingleFrame" BO_ 2628512561 1;
BA_ "GenMsgCycleTime" BO_ 2628475697 60000;
BA_ "SingleFrame" BO_ 2628475697 1;
BA_ "GenMsgCycleTime" BO_ 2628465096 60000;
BA_ "SingleFrame" BO_ 2628465096 1;
BA_ "GenMsgCycleTime" BO_ 2628512456 60000;
BA_ "SingleFrame" BO_ 2628512456 1;
BA_ "GenMsgCycleTime" BO_ 2628512712 60000;
BA_ "SingleFrame" BO_ 2628512712 1;
BA_ "GenMsgCycleTime" BO_ 2628475848 60000;
BA_ "SingleFrame" BO_ 2628475848 1;
BA_ "GenMsgCycleTime" BO_ 2628465130 60000;
BA_ "SingleFrame" BO_ 2628465130 1;
BA_ "GenMsgCycleTime" BO_ 2628503786 60000;
BA_ "SingleFrame" BO_ 2628503786 1;
BA_ "GenMsgCycleTime" BO_ 2628512746 60000;
BA_ "SingleFrame" BO_ 2628512746 1;
BA_ "GenMsgCycleTime" BO_ 2628475882 60000;
BA_ "SingleFrame" BO_ 2628475882 1;
BA_ "GenMsgCycleTime" BO_ 2628465131 60000;
BA_ "SingleFrame" BO_ 2628465131 1;
BA_ "GenMsgCycleTime" BO_ 2628503787 60000;
BA_ "SingleFrame" BO_ 2628503787 1;
BA_ "GenMsgCycleTime" BO_ 2628512491 60000;
BA_ "SingleFrame" BO_ 2628512491 1;
BA_ "GenMsgCycleTime" BO_ 2628475883 60000;
BA_ "SingleFrame" BO_ 2628475883 1;
BA_ "GenMsgCycleTime" BO_ 2628464987 60000;
BA_ "SingleFrame" BO_ 2628464987 1;
BA_ "GenMsgCycleTime" BO_ 2628503643 60000;
BA_ "SingleFrame" BO_ 2628503643 1;
BA_ "GenMsgCycleTime" BO_ 2628512347 60000;
BA_ "SingleFrame" BO_ 2628512347 1;
BA_ "GenMsgCycleTime" BO_ 2628512603 60000;
BA_ "SingleFrame" BO_ 2628512603 1;
BA_ "GenMsgCycleTime" BO_ 2662475498 60000;
BA_ "GenMsgCycleTime" BO_ 2662525478 60000;
BA_ "GenMsgCycleTime" BO_ 2662531050 60000;
BA_ "GenMsgCycleTime" BO_ 2662530854 60000;
BA_ "GenMsgCycleTime" BO_ 2566842878 5000;
BA_ "GenMsgSendType" BO_ 2566842878 0;
BA_ "GenMsgCycleTimeFast" BO_ 2566842878 5000;
BA_ "SingleFrame" BO_ 2566842878 1;
BA_ "GenMsgCycleTime" BO_ 2566845182 100;
BA_ "GenMsgSendType" BO_ 2566845182 0;
BA_ "GenMsgCycleTimeFast" BO_ 2566845182 100;
BA_ "SingleFrame" BO_ 2566845182 1;
BA_ "GenMsgCycleTime" BO_ 2360147966 100;
BA_ "GenMsgSendType" BO_ 2360147966 0;
BA_ "GenMsgCycleTimeFast" BO_ 2360147966 100;
BA_ "SingleFrame" BO_ 2360147966 1;
BA_ "GenMsgCycleTime" BO_ 2360213286 100;
BA_ "GenMsgSendType" BO_ 2360213286 0;
BA_ "GenMsgCycleTimeFast" BO_ 2360213286 100;
BA_ "SingleFrame" BO_ 2360213286 1;
BA_ "GenMsgCycleTime" BO_ 2365528881 50;
BA_ "GenMsgSendType" BO_ 2365528881 0;
BA_ "GenMsgCycleTimeFast" BO_ 2365528881 50;
BA_ "SingleFrame" BO_ 2365528881 1;
BA_ "GenMsgCycleTime" BO_ 2361850878 100;
BA_ "GenMsgSendType" BO_ 2361850878 0;
BA_ "GenMsgCycleTimeFast" BO_ 2361850878 100;
BA_ "SingleFrame" BO_ 2361850878 1;
BA_ "GenMsgCycleTime" BO_ 2361851902 100;
BA_ "GenMsgSendType" BO_ 2361851902 0;
BA_ "GenMsgCycleTimeFast" BO_ 2361851902 100;
BA_ "SingleFrame" BO_ 2361851902 1;
BA_ "GenMsgCycleTime" BO_ 2566846206 500;
BA_ "GenMsgSendType" BO_ 2566846206 0;
BA_ "GenMsgCycleTimeFast" BO_ 2566846206 500;
BA_ "SingleFrame" BO_ 2566846206 1;
BA_ "GenMsgCycleTime" BO_ 2566734536 60000;
BA_ "SingleFrame" BO_ 2566734536 1;
BA_ "GenMsgCycleTime" BO_ 2566734570 60000;
BA_ "SingleFrame" BO_ 2566734570 1;
BA_ "GenMsgCycleTime" BO_ 2566734571 60000;
BA_ "SingleFrame" BO_ 2566734571 1;
BA_ "GenMsgCycleTime" BO_ 2566734427 60000;
BA_ "SingleFrame" BO_ 2566734427 1;
BA_ "GenMsgCycleTime" BO_ 2566878001 60000;
BA_ "SingleFrame" BO_ 2566878001 1;
BA_ "GenMsgCycleTime" BO_ 2566878152 60000;
BA_ "SingleFrame" BO_ 2566878152 1;
BA_ "GenMsgCycleTime" BO_ 2566878186 60000;
BA_ "SingleFrame" BO_ 2566878186 1;
BA_ "GenMsgCycleTime" BO_ 2566878187 60000;
BA_ "SingleFrame" BO_ 2566878187 1;
BA_ "GenMsgCycleTime" BO_ 2566878043 60000;
BA_ "SingleFrame" BO_ 2566878043 1;
BA_ "GenMsgCycleTime" BO_ 2365582427 100;
BA_ "GenMsgSendType" BO_ 2365582427 0;
BA_ "GenMsgCycleTimeFast" BO_ 2365582427 100;
BA_ "SingleFrame" BO_ 2365582427 1;
BA_ "GenMsgCycleTime" BO_ 2566786865 60000;
BA_ "SingleFrame" BO_ 2566786865 1;
BA_ "GenMsgCycleTime" BO_ 2566787016 60000;
BA_ "SingleFrame" BO_ 2566787016 1;
BA_ "GenMsgCycleTime" BO_ 2566787050 60000;
BA_ "SingleFrame" BO_ 2566787050 1;
BA_ "GenMsgCycleTime" BO_ 2566787051 60000;
BA_ "SingleFrame" BO_ 2566787051 1;
BA_ "GenMsgCycleTime" BO_ 2566786907 60000;
BA_ "SingleFrame" BO_ 2566786907 1;
BA_ "GenMsgCycleTime" BO_ 2662465514 60000;
BA_ "GenMsgCycleTime" BO_ 2662409962 60000;
BA_ "GenMsgCycleTime" BO_ 2662459942 60000;
BA_ "GenMsgCycleTime" BO_ 2662465318 60000;
BA_ "GenMsgCycleTime" BO_ 2365473073 1000;
BA_ "GenMsgSendType" BO_ 2365473073 0;
BA_ "GenMsgCycleTimeFast" BO_ 2365473073 1000;
BA_ "SingleFrame" BO_ 2365473073 1;
BA_ "GenMsgCycleTime" BO_ 2566801386 520;
BA_ "GenMsgSendType" BO_ 2566801386 0;
BA_ "GenMsgCycleTimeFast" BO_ 2566801386 520;
BA_ "SingleFrame" BO_ 2566801386 1;
BA_ "GenMsgCycleTime" BO_ 2566801387 520;
BA_ "GenMsgSendType" BO_ 2566801387 0;
BA_ "GenMsgCycleTimeFast" BO_ 2566801387 520;
BA_ "SingleFrame" BO_ 2566801387 1;
BA_ "GenMsgCycleTime" BO_ 2566801243 520;
BA_ "GenMsgSendType" BO_ 2566801243 0;
BA_ "GenMsgCycleTimeFast" BO_ 2566801243 520;
BA_ "SingleFrame" BO_ 2566801243 1;
BA_ "GenMsgCycleTime" BO_ 2662727658 60000;
BA_ "GenMsgCycleTime" BO_ 2662672106 60000;
BA_ "GenMsgCycleTime" BO_ 2662722086 60000;
BA_ "GenMsgCycleTime" BO_ 2662727462 60000;
BA_ "GenMsgCycleTime" BO_ 2564423473 60000;
BA_ "SingleFrame" BO_ 2564423473 1;
BA_ "GenMsgCycleTime" BO_ 2564423624 60000;
BA_ "SingleFrame" BO_ 2564423624 1;
BA_ "GenMsgCycleTime" BO_ 2564423658 60000;
BA_ "SingleFrame" BO_ 2564423658 1;
BA_ "GenMsgCycleTime" BO_ 2564423659 60000;
BA_ "SingleFrame" BO_ 2564423659 1;
BA_ "GenMsgCycleTime" BO_ 2564423515 60000;
BA_ "SingleFrame" BO_ 2564423515 1;
BA_ "GenMsgCycleTime" BO_ 2564357937 60000;
BA_ "SingleFrame" BO_ 2564357937 1;
BA_ "GenMsgCycleTime" BO_ 2564358088 60000;
BA_ "SingleFrame" BO_ 2564358088 1;
BA_ "GenMsgCycleTime" BO_ 2564358122 60000;
BA_ "SingleFrame" BO_ 2564358122 1;
BA_ "GenMsgCycleTime" BO_ 2564358123 60000;
BA_ "SingleFrame" BO_ 2564358123 1;
BA_ "GenMsgCycleTime" BO_ 2564357979 60000;
BA_ "SingleFrame" BO_ 2564357979 1;
BA_ "GenMsgCycleTime" BO_ 2662399978 60000;
BA_ "GenMsgCycleTime" BO_ 2662344426 60000;
BA_ "GenMsgCycleTime" BO_ 2662394406 60000;
BA_ "GenMsgCycleTime" BO_ 2662399782 60000;
BA_ "GenMsgCycleTime" BO_ 2362179377 60000;
BA_ "SingleFrame" BO_ 2362179377 1;
BA_ "GenMsgCycleTime" BO_ 2362179528 60000;
BA_ "SingleFrame" BO_ 2362179528 1;
BA_ "GenMsgCycleTime" BO_ 2362179562 60000;
BA_ "SingleFrame" BO_ 2362179562 1;
BA_ "GenMsgCycleTime" BO_ 2362179563 60000;
BA_ "SingleFrame" BO_ 2362179563 1;
BA_ "GenMsgCycleTime" BO_ 2362179419 60000;
BA_ "SingleFrame" BO_ 2362179419 1;
BA_ "GenMsgCycleTime" BO_ 2566688200 60000;
BA_ "SingleFrame" BO_ 2566688200 1;
BA_ "GenMsgCycleTime" BO_ 2566688234 60000;
BA_ "SingleFrame" BO_ 2566688234 1;
BA_ "GenMsgCycleTime" BO_ 2566688235 60000;
BA_ "SingleFrame" BO_ 2566688235 1;
BA_ "GenMsgCycleTime" BO_ 2566688091 60000;
BA_ "SingleFrame" BO_ 2566688091 1;
BA_ "GenMsgCycleTime" BO_ 2365528299 100;
BA_ "SingleFrame" BO_ 2365528299 1;
BA_ "GenMsgCycleTime" BO_ 2563374897 60000;
BA_ "SingleFrame" BO_ 2563374897 1;
BA_ "GenMsgCycleTime" BO_ 2563375048 60000;
BA_ "SingleFrame" BO_ 2563375048 1;
BA_ "GenMsgCycleTime" BO_ 2563375082 60000;
BA_ "SingleFrame" BO_ 2563375082 1;
BA_ "GenMsgCycleTime" BO_ 2563375083 60000;
BA_ "SingleFrame" BO_ 2563375083 1;
BA_ "GenMsgCycleTime" BO_ 2563374939 60000;
BA_ "SingleFrame" BO_ 2563374939 1;
BA_ "GenMsgCycleTime" BO_ 2563360817 60000;
BA_ "SingleFrame" BO_ 2563360817 1;
BA_ "GenMsgCycleTime" BO_ 2563369521 60000;
BA_ "SingleFrame" BO_ 2563369521 1;
BA_ "GenMsgCycleTime" BO_ 2563369777 60000;
BA_ "SingleFrame" BO_ 2563369777 1;
BA_ "GenMsgCycleTime" BO_ 2563332913 60000;
BA_ "SingleFrame" BO_ 2563332913 1;
BA_ "GenMsgCycleTime" BO_ 2563322312 60000;
BA_ "SingleFrame" BO_ 2563322312 1;
BA_ "GenMsgCycleTime" BO_ 2563369672 60000;
BA_ "SingleFrame" BO_ 2563369672 1;
BA_ "GenMsgCycleTime" BO_ 2563369928 60000;
BA_ "SingleFrame" BO_ 2563369928 1;
BA_ "GenMsgCycleTime" BO_ 2563333064 60000;
BA_ "SingleFrame" BO_ 2563333064 1;
BA_ "GenMsgCycleTime" BO_ 2563322346 60000;
BA_ "SingleFrame" BO_ 2563322346 1;
BA_ "GenMsgCycleTime" BO_ 2563361002 60000;
BA_ "SingleFrame" BO_ 2563361002 1;
BA_ "GenMsgCycleTime" BO_ 2563369962 60000;
BA_ "SingleFrame" BO_ 2563369962 1;
BA_ "GenMsgCycleTime" BO_ 2563333098 60000;
BA_ "SingleFrame" BO_ 2563333098 1;
BA_ "GenMsgCycleTime" BO_ 2563322347 60000;
BA_ "SingleFrame" BO_ 2563322347 1;
BA_ "GenMsgCycleTime" BO_ 2563361003 60000;
BA_ "SingleFrame" BO_ 2563361003 1;
BA_ "GenMsgCycleTime" BO_ 2563369707 60000;
BA_ "SingleFrame" BO_ 2563369707 1;
BA_ "GenMsgCycleTime" BO_ 2563333099 60000;
BA_ "SingleFrame" BO_ 2563333099 1;
BA_ "GenMsgCycleTime" BO_ 2563322203 60000;
BA_ "SingleFrame" BO_ 2563322203 1;
BA_ "GenMsgCycleTime" BO_ 2563360859 60000;
BA_ "SingleFrame" BO_ 2563360859 1;
BA_ "GenMsgCycleTime" BO_ 2563369563 60000;
BA_ "SingleFrame" BO_ 2563369563 1;
BA_ "GenMsgCycleTime" BO_ 2563369819 60000;
BA_ "SingleFrame" BO_ 2563369819 1;
BA_ "GenMsgCycleTime" BO_ 2565537585 60000;
BA_ "SingleFrame" BO_ 2565537585 1;
BA_ "GenMsgCycleTime" BO_ 2565537736 60000;
BA_ "SingleFrame" BO_ 2565537736 1;
BA_ "GenMsgCycleTime" BO_ 2565537770 60000;
BA_ "SingleFrame" BO_ 2565537770 1;
BA_ "GenMsgCycleTime" BO_ 2565537771 60000;
BA_ "SingleFrame" BO_ 2565537771 1;
BA_ "GenMsgCycleTime" BO_ 2565537627 60000;
BA_ "SingleFrame" BO_ 2565537627 1;
BA_ "GenMsgCycleTime" BO_ 2565537574 60000;
BA_ "SingleFrame" BO_ 2565537574 1;
BA_ "GenMsgCycleTime" BO_ 2358116145 60000;
BA_ "SingleFrame" BO_ 2358116145 1;
BA_ "GenMsgCycleTime" BO_ 2358116296 60000;
BA_ "SingleFrame" BO_ 2358116296 1;
BA_ "GenMsgCycleTime" BO_ 2358116330 60000;
BA_ "SingleFrame" BO_ 2358116330 1;
BA_ "GenMsgCycleTime" BO_ 2358116331 60000;
BA_ "SingleFrame" BO_ 2358116331 1;
BA_ "GenMsgCycleTime" BO_ 2358116187 60000;
BA_ "SingleFrame" BO_ 2358116187 1;
BA_ "GenMsgCycleTime" BO_ 2358102065 60000;
BA_ "SingleFrame" BO_ 2358102065 1;
BA_ "GenMsgCycleTime" BO_ 2358110769 60000;
BA_ "SingleFrame" BO_ 2358110769 1;
BA_ "GenMsgCycleTime" BO_ 2358111025 60000;
BA_ "SingleFrame" BO_ 2358111025 1;
BA_ "GenMsgCycleTime" BO_ 2358074161 60000;
BA_ "SingleFrame" BO_ 2358074161 1;
BA_ "GenMsgCycleTime" BO_ 2358063560 60000;
BA_ "SingleFrame" BO_ 2358063560 1;
BA_ "GenMsgCycleTime" BO_ 2358110920 60000;
BA_ "SingleFrame" BO_ 2358110920 1;
BA_ "GenMsgCycleTime" BO_ 2358111176 60000;
BA_ "SingleFrame" BO_ 2358111176 1;
BA_ "GenMsgCycleTime" BO_ 2358074312 60000;
BA_ "SingleFrame" BO_ 2358074312 1;
BA_ "GenMsgCycleTime" BO_ 2358063594 60000;
BA_ "SingleFrame" BO_ 2358063594 1;
BA_ "GenMsgCycleTime" BO_ 2358102250 60000;
BA_ "SingleFrame" BO_ 2358102250 1;
BA_ "GenMsgCycleTime" BO_ 2358111210 60000;
BA_ "SingleFrame" BO_ 2358111210 1;
BA_ "GenMsgCycleTime" BO_ 2358074346 60000;
BA_ "SingleFrame" BO_ 2358074346 1;
BA_ "GenMsgCycleTime" BO_ 2358063595 60000;
BA_ "SingleFrame" BO_ 2358063595 1;
BA_ "GenMsgCycleTime" BO_ 2358102251 60000;
BA_ "SingleFrame" BO_ 2358102251 1;
BA_ "GenMsgCycleTime" BO_ 2358110955 60000;
BA_ "SingleFrame" BO_ 2358110955 1;
BA_ "GenMsgCycleTime" BO_ 2358074347 60000;
BA_ "SingleFrame" BO_ 2358074347 1;
BA_ "GenMsgCycleTime" BO_ 2358063451 60000;
BA_ "SingleFrame" BO_ 2358063451 1;
BA_ "GenMsgCycleTime" BO_ 2358102107 60000;
BA_ "SingleFrame" BO_ 2358102107 1;
BA_ "GenMsgCycleTime" BO_ 2358110811 60000;
BA_ "SingleFrame" BO_ 2358110811 1;
BA_ "GenMsgCycleTime" BO_ 2358111067 60000;
BA_ "SingleFrame" BO_ 2358111067 1;
BA_ "GenMsgCycleTime" BO_ 2358181681 60000;
BA_ "SingleFrame" BO_ 2358181681 1;
BA_ "GenMsgCycleTime" BO_ 2358181832 60000;
BA_ "SingleFrame" BO_ 2358181832 1;
BA_ "GenMsgCycleTime" BO_ 2358181866 60000;
BA_ "SingleFrame" BO_ 2358181866 1;
BA_ "GenMsgCycleTime" BO_ 2358181867 60000;
BA_ "SingleFrame" BO_ 2358181867 1;
BA_ "GenMsgCycleTime" BO_ 2358181723 60000;
BA_ "SingleFrame" BO_ 2358181723 1;
BA_ "GenMsgCycleTime" BO_ 2358167601 60000;
BA_ "SingleFrame" BO_ 2358167601 1;
BA_ "GenMsgCycleTime" BO_ 2358176305 60000;
BA_ "SingleFrame" BO_ 2358176305 1;
BA_ "GenMsgCycleTime" BO_ 2358176561 60000;
BA_ "SingleFrame" BO_ 2358176561 1;
BA_ "GenMsgCycleTime" BO_ 2358139697 60000;
BA_ "SingleFrame" BO_ 2358139697 1;
BA_ "GenMsgCycleTime" BO_ 2358129096 60000;
BA_ "SingleFrame" BO_ 2358129096 1;
BA_ "GenMsgCycleTime" BO_ 2358176456 60000;
BA_ "SingleFrame" BO_ 2358176456 1;
BA_ "GenMsgCycleTime" BO_ 2358176712 60000;
BA_ "SingleFrame" BO_ 2358176712 1;
BA_ "GenMsgCycleTime" BO_ 2358139848 60000;
BA_ "SingleFrame" BO_ 2358139848 1;
BA_ "GenMsgCycleTime" BO_ 2358129130 60000;
BA_ "SingleFrame" BO_ 2358129130 1;
BA_ "GenMsgCycleTime" BO_ 2358167786 60000;
BA_ "SingleFrame" BO_ 2358167786 1;
BA_ "GenMsgCycleTime" BO_ 2358176746 60000;
BA_ "SingleFrame" BO_ 2358176746 1;
BA_ "GenMsgCycleTime" BO_ 2358139882 60000;
BA_ "SingleFrame" BO_ 2358139882 1;
BA_ "GenMsgCycleTime" BO_ 2358129131 60000;
BA_ "SingleFrame" BO_ 2358129131 1;
BA_ "GenMsgCycleTime" BO_ 2358167787 60000;
BA_ "SingleFrame" BO_ 2358167787 1;
BA_ "GenMsgCycleTime" BO_ 2358176491 60000;
BA_ "SingleFrame" BO_ 2358176491 1;
BA_ "GenMsgCycleTime" BO_ 2358139883 60000;
BA_ "SingleFrame" BO_ 2358139883 1;
BA_ "GenMsgCycleTime" BO_ 2358128987 60000;
BA_ "SingleFrame" BO_ 2358128987 1;
BA_ "GenMsgCycleTime" BO_ 2358167643 60000;
BA_ "SingleFrame" BO_ 2358167643 1;
BA_ "GenMsgCycleTime" BO_ 2358176347 60000;
BA_ "SingleFrame" BO_ 2358176347 1;
BA_ "GenMsgCycleTime" BO_ 2358176603 60000;
BA_ "SingleFrame" BO_ 2358176603 1;
BA_ "GenMsgCycleTime" BO_ 2566838833 60000;
BA_ "SingleFrame" BO_ 2566838833 1;
BA_ "GenMsgCycleTime" BO_ 2566838984 60000;
BA_ "SingleFrame" BO_ 2566838984 1;
BA_ "GenMsgCycleTime" BO_ 2566839018 60000;
BA_ "SingleFrame" BO_ 2566839018 1;
BA_ "GenMsgCycleTime" BO_ 2566839019 60000;
BA_ "SingleFrame" BO_ 2566839019 1;
BA_ "GenMsgCycleTime" BO_ 2566839000 60000;
BA_ "SingleFrame" BO_ 2566839000 1;
BA_ "GenMsgCycleTime" BO_ 2566838875 60000;
BA_ "SingleFrame" BO_ 2566838875 1;
BA_ "GenMsgCycleTime" BO_ 2662662122 60000;
BA_ "SingleFrame" BO_ 2662662122 1;
BA_ "GenMsgCycleTime" BO_ 2662606570 60000;
BA_ "SingleFrame" BO_ 2662606570 1;
BA_ "GenMsgCycleTime" BO_ 2662656550 60000;
BA_ "SingleFrame" BO_ 2662656550 1;
BA_ "GenMsgCycleTime" BO_ 2662661926 60000;
BA_ "SingleFrame" BO_ 2662661926 1;
BA_ "GenMsgCycleTime" BO_ 2515538171 1000;
BA_ "GenMsgSendType" BO_ 2515538171 0;
BA_ "GenMsgCycleTimeFast" BO_ 2515538171 1000;
BA_ "SingleFrame" BO_ 2515538171 1;
BA_ "GenMsgCycleTime" BO_ 2632777521 60000;
BA_ "SingleFrame" BO_ 2632777521 1;
BA_ "GenMsgCycleTime" BO_ 2632777672 60000;
BA_ "SingleFrame" BO_ 2632777672 1;
BA_ "GenMsgCycleTime" BO_ 2632777706 60000;
BA_ "SingleFrame" BO_ 2632777706 1;
BA_ "GenMsgCycleTime" BO_ 2632777707 60000;
BA_ "SingleFrame" BO_ 2632777707 1;
BA_ "GenMsgCycleTime" BO_ 2632777563 60000;
BA_ "SingleFrame" BO_ 2632777563 1;
BA_ "GenMsgCycleTime" BO_ 2632777510 60000;
BA_ "SingleFrame" BO_ 2632777510 1;
BA_ "GenMsgCycleTime" BO_ 2632711985 60000;
BA_ "SingleFrame" BO_ 2632711985 1;
BA_ "GenMsgCycleTime" BO_ 2632712136 60000;
BA_ "SingleFrame" BO_ 2632712136 1;
BA_ "GenMsgCycleTime" BO_ 2632712170 60000;
BA_ "SingleFrame" BO_ 2632712170 1;
BA_ "GenMsgCycleTime" BO_ 2632712171 60000;
BA_ "SingleFrame" BO_ 2632712171 1;
BA_ "GenMsgCycleTime" BO_ 2632712027 60000;
BA_ "SingleFrame" BO_ 2632712027 1;
BA_ "GenMsgCycleTime" BO_ 2632711974 60000;
BA_ "SingleFrame" BO_ 2632711974 1;
BA_ "GenMsgCycleTime" BO_ 2564549610 60000;
BA_ "SingleFrame" BO_ 2564549610 1;
BA_ "GenMsgCycleTime" BO_ 2564512746 60000;
BA_ "SingleFrame" BO_ 2564512746 1;
BA_ "GenMsgCycleTime" BO_ 2564549355 60000;
BA_ "SingleFrame" BO_ 2564549355 1;
BA_ "GenMsgCycleTime" BO_ 2564512747 60000;
BA_ "SingleFrame" BO_ 2564512747 1;
BA_ "GenMsgCycleTime" BO_ 2564549211 60000;
BA_ "SingleFrame" BO_ 2564549211 1;
BA_ "GenMsgCycleTime" BO_ 2564549467 60000;
BA_ "SingleFrame" BO_ 2564549467 1;
BA_ "GenMsgCycleTime" BO_ 2564554730 60000;
BA_ "SingleFrame" BO_ 2564554730 1;
BA_ "GenMsgCycleTime" BO_ 2564554731 60000;
BA_ "SingleFrame" BO_ 2564554731 1;
BA_ "GenMsgCycleTime" BO_ 2564554587 60000;
BA_ "SingleFrame" BO_ 2564554587 1;
BA_ "GenMsgCycleTime" BO_ 2564489194 60000;
BA_ "SingleFrame" BO_ 2564489194 1;
BA_ "GenMsgCycleTime" BO_ 2564489195 60000;
BA_ "SingleFrame" BO_ 2564489195 1;
BA_ "GenMsgCycleTime" BO_ 2564489051 60000;
BA_ "SingleFrame" BO_ 2564489051 1;
BA_ "GenMsgCycleTime" BO_ 2564484074 60000;
BA_ "SingleFrame" BO_ 2564484074 1;
BA_ "GenMsgCycleTime" BO_ 2564447210 60000;
BA_ "SingleFrame" BO_ 2564447210 1;
BA_ "GenMsgCycleTime" BO_ 2564483819 60000;
BA_ "SingleFrame" BO_ 2564483819 1;
BA_ "GenMsgCycleTime" BO_ 2564447211 60000;
BA_ "SingleFrame" BO_ 2564447211 1;
BA_ "GenMsgCycleTime" BO_ 2564483675 60000;
BA_ "SingleFrame" BO_ 2564483675 1;
BA_ "GenMsgCycleTime" BO_ 2564483931 60000;
BA_ "SingleFrame" BO_ 2564483931 1;
BA_ "GenMsgCycleTime" BO_ 2365515814 200;
BA_ "GenMsgSendType" BO_ 2365515814 0;
BA_ "GenMsgCycleTimeFast" BO_ 2365515814 200;
BA_ "SingleFrame" BO_ 2365515814 1;
BA_ "GenMsgCycleTime" BO_ 2633952305 60000;
BA_ "SingleFrame" BO_ 2633952305 1;
BA_ "GenMsgCycleTime" BO_ 2633952456 60000;
BA_ "SingleFrame" BO_ 2633952456 1;
BA_ "GenMsgCycleTime" BO_ 2633952490 60000;
BA_ "SingleFrame" BO_ 2633952490 1;
BA_ "GenMsgCycleTime" BO_ 2633952491 60000;
BA_ "SingleFrame" BO_ 2633952491 1;
BA_ "GenMsgCycleTime" BO_ 2633952347 60000;
BA_ "SingleFrame" BO_ 2633952347 1;
BA_ "GenMsgCycleTime" BO_ 2499700827 1000;
BA_ "GenMsgSendType" BO_ 2499700827 0;
BA_ "GenMsgCycleTimeFast" BO_ 2499700827 1000;
BA_ "SingleFrame" BO_ 2499700827 1;
BA_ "GenMsgCycleTime" BO_ 2566842161 5000;
BA_ "GenMsgSendType" BO_ 2566842161 0;
BA_ "GenMsgCycleTimeFast" BO_ 2566842161 100;
BA_ "SingleFrame" BO_ 2566842161 1;
BA_ "GenMsgCycleTime" BO_ 2632370225 60000;
BA_ "SingleFrame" BO_ 2632370225 1;
BA_ "GenMsgCycleTime" BO_ 2632378929 60000;
BA_ "SingleFrame" BO_ 2632378929 1;
BA_ "GenMsgCycleTime" BO_ 2632379185 60000;
BA_ "SingleFrame" BO_ 2632379185 1;
BA_ "GenMsgCycleTime" BO_ 2632342321 60000;
BA_ "SingleFrame" BO_ 2632342321 1;
BA_ "GenMsgCycleTime" BO_ 2632331720 60000;
BA_ "SingleFrame" BO_ 2632331720 1;
BA_ "GenMsgCycleTime" BO_ 2632379080 60000;
BA_ "SingleFrame" BO_ 2632379080 1;
BA_ "GenMsgCycleTime" BO_ 2632379336 60000;
BA_ "SingleFrame" BO_ 2632379336 1;
BA_ "GenMsgCycleTime" BO_ 2632342472 60000;
BA_ "SingleFrame" BO_ 2632342472 1;
BA_ "GenMsgCycleTime" BO_ 2632331754 60000;
BA_ "SingleFrame" BO_ 2632331754 1;
BA_ "GenMsgCycleTime" BO_ 2632370410 60000;
BA_ "SingleFrame" BO_ 2632370410 1;
BA_ "GenMsgCycleTime" BO_ 2632379370 60000;
BA_ "SingleFrame" BO_ 2632379370 1;
BA_ "GenMsgCycleTime" BO_ 2632342506 60000;
BA_ "SingleFrame" BO_ 2632342506 1;
BA_ "GenMsgCycleTime" BO_ 2632331755 60000;
BA_ "SingleFrame" BO_ 2632331755 1;
BA_ "GenMsgCycleTime" BO_ 2632370411 60000;
BA_ "SingleFrame" BO_ 2632370411 1;
BA_ "GenMsgCycleTime" BO_ 2632379115 60000;
BA_ "SingleFrame" BO_ 2632379115 1;
BA_ "GenMsgCycleTime" BO_ 2632342507 60000;
BA_ "SingleFrame" BO_ 2632342507 1;
BA_ "GenMsgCycleTime" BO_ 2632331611 60000;
BA_ "SingleFrame" BO_ 2632331611 1;
BA_ "GenMsgCycleTime" BO_ 2632370267 60000;
BA_ "SingleFrame" BO_ 2632370267 1;
BA_ "GenMsgCycleTime" BO_ 2632378971 60000;
BA_ "SingleFrame" BO_ 2632378971 1;
BA_ "GenMsgCycleTime" BO_ 2632379227 60000;
BA_ "SingleFrame" BO_ 2632379227 1;
BA_ "GenMsgCycleTime" BO_ 2632384305 60000;
BA_ "SingleFrame" BO_ 2632384305 1;
BA_ "GenMsgCycleTime" BO_ 2632384456 60000;
BA_ "SingleFrame" BO_ 2632384456 1;
BA_ "GenMsgCycleTime" BO_ 2632384490 60000;
BA_ "SingleFrame" BO_ 2632384490 1;
BA_ "GenMsgCycleTime" BO_ 2632384491 60000;
BA_ "SingleFrame" BO_ 2632384491 1;
BA_ "GenMsgCycleTime" BO_ 2632384347 60000;
BA_ "SingleFrame" BO_ 2632384347 1;
BA_ "GenMsgCycleTime" BO_ 2365475070 120;
BA_ "GenMsgSendType" BO_ 2365475070 0;
BA_ "GenMsgCycleTimeFast" BO_ 2365475070 120;
BA_ "SingleFrame" BO_ 2365475070 1;
BA_ "GenMsgCycleTime" BO_ 2566786353 60000;
BA_ "SingleFrame" BO_ 2566786353 1;
BA_ "GenMsgCycleTime" BO_ 2566786504 60000;
BA_ "SingleFrame" BO_ 2566786504 1;
BA_ "GenMsgCycleTime" BO_ 2566786538 60000;
BA_ "SingleFrame" BO_ 2566786538 1;
BA_ "GenMsgCycleTime" BO_ 2566786539 60000;
BA_ "SingleFrame" BO_ 2566786539 1;
BA_ "GenMsgCycleTime" BO_ 2566786395 60000;
BA_ "SingleFrame" BO_ 2566786395 1;
BA_ "GenMsgCycleTime" BO_ 2566786097 60000;
BA_ "SingleFrame" BO_ 2566786097 1;
BA_ "GenMsgCycleTime" BO_ 2566786248 60000;
BA_ "SingleFrame" BO_ 2566786248 1;
BA_ "GenMsgCycleTime" BO_ 2566786282 60000;
BA_ "SingleFrame" BO_ 2566786282 1;
BA_ "GenMsgCycleTime" BO_ 2566786283 60000;
BA_ "SingleFrame" BO_ 2566786283 1;
BA_ "GenMsgCycleTime" BO_ 2566786139 60000;
BA_ "SingleFrame" BO_ 2566786139 1;
BA_ "GenMsgCycleTime" BO_ 2559377386 60000;
BA_ "SingleFrame" BO_ 2559377386 1;
BA_ "GenMsgCycleTime" BO_ 2559377387 60000;
BA_ "SingleFrame" BO_ 2559377387 1;
BA_ "GenMsgCycleTime" BO_ 2559377401 60000;
BA_ "SingleFrame" BO_ 2559377401 1;
BA_ "GenMsgCycleTime" BO_ 2559377402 60000;
BA_ "SingleFrame" BO_ 2559377402 1;
BA_ "GenMsgCycleTime" BO_ 2559377243 60000;
BA_ "SingleFrame" BO_ 2559377243 1;
BA_ "GenMsgCycleTime" BO_ 2559377370 60000;
BA_ "SingleFrame" BO_ 2559377370 1;
BA_ "GenMsgCycleTime" BO_ 2559311816 60000;
BA_ "SingleFrame" BO_ 2559311816 1;
BA_ "GenMsgCycleTime" BO_ 2559311850 60000;
BA_ "SingleFrame" BO_ 2559311850 1;
BA_ "GenMsgCycleTime" BO_ 2559311851 60000;
BA_ "SingleFrame" BO_ 2559311851 1;
BA_ "GenMsgCycleTime" BO_ 2559311865 60000;
BA_ "SingleFrame" BO_ 2559311865 1;
BA_ "GenMsgCycleTime" BO_ 2559311866 60000;
BA_ "SingleFrame" BO_ 2559311866 1;
BA_ "GenMsgCycleTime" BO_ 2559311707 60000;
BA_ "SingleFrame" BO_ 2559311707 1;
BA_ "GenMsgCycleTime" BO_ 2559311834 60000;
BA_ "SingleFrame" BO_ 2559311834 1;
BA_ "GenMsgCycleTime" BO_ 2559363306 60000;
BA_ "SingleFrame" BO_ 2559363306 1;
BA_ "GenMsgCycleTime" BO_ 2559372266 60000;
BA_ "SingleFrame" BO_ 2559372266 1;
BA_ "GenMsgCycleTime" BO_ 2559375850 60000;
BA_ "SingleFrame" BO_ 2559375850 1;
BA_ "GenMsgCycleTime" BO_ 2559376106 60000;
BA_ "SingleFrame" BO_ 2559376106 1;
BA_ "GenMsgCycleTime" BO_ 2559335402 60000;
BA_ "SingleFrame" BO_ 2559335402 1;
BA_ "GenMsgCycleTime" BO_ 2559367914 60000;
BA_ "SingleFrame" BO_ 2559367914 1;
BA_ "GenMsgCycleTime" BO_ 2559363307 60000;
BA_ "SingleFrame" BO_ 2559363307 1;
BA_ "GenMsgCycleTime" BO_ 2559372011 60000;
BA_ "SingleFrame" BO_ 2559372011 1;
BA_ "GenMsgCycleTime" BO_ 2559375851 60000;
BA_ "SingleFrame" BO_ 2559375851 1;
BA_ "GenMsgCycleTime" BO_ 2559376107 60000;
BA_ "SingleFrame" BO_ 2559376107 1;
BA_ "GenMsgCycleTime" BO_ 2559335403 60000;
BA_ "SingleFrame" BO_ 2559335403 1;
BA_ "GenMsgCycleTime" BO_ 2559367915 60000;
BA_ "SingleFrame" BO_ 2559367915 1;
BA_ "GenMsgCycleTime" BO_ 2559363322 60000;
BA_ "SingleFrame" BO_ 2559363322 1;
BA_ "GenMsgCycleTime" BO_ 2559372026 60000;
BA_ "SingleFrame" BO_ 2559372026 1;
BA_ "GenMsgCycleTime" BO_ 2559372282 60000;
BA_ "SingleFrame" BO_ 2559372282 1;
BA_ "GenMsgCycleTime" BO_ 2559375866 60000;
BA_ "SingleFrame" BO_ 2559375866 1;
BA_ "GenMsgCycleTime" BO_ 2559335418 60000;
BA_ "SingleFrame" BO_ 2559335418 1;
BA_ "GenMsgCycleTime" BO_ 2559367930 60000;
BA_ "SingleFrame" BO_ 2559367930 1;
BA_ "GenMsgCycleTime" BO_ 2559363321 60000;
BA_ "SingleFrame" BO_ 2559363321 1;
BA_ "GenMsgCycleTime" BO_ 2559372025 60000;
BA_ "SingleFrame" BO_ 2559372025 1;
BA_ "GenMsgCycleTime" BO_ 2559372281 60000;
BA_ "SingleFrame" BO_ 2559372281 1;
BA_ "GenMsgCycleTime" BO_ 2559376121 60000;
BA_ "SingleFrame" BO_ 2559376121 1;
BA_ "GenMsgCycleTime" BO_ 2559335417 60000;
BA_ "SingleFrame" BO_ 2559335417 1;
BA_ "GenMsgCycleTime" BO_ 2559367929 60000;
BA_ "SingleFrame" BO_ 2559367929 1;
BA_ "GenMsgCycleTime" BO_ 2559363163 60000;
BA_ "SingleFrame" BO_ 2559363163 1;
BA_ "GenMsgCycleTime" BO_ 2559371867 60000;
BA_ "SingleFrame" BO_ 2559371867 1;
BA_ "GenMsgCycleTime" BO_ 2559372123 60000;
BA_ "SingleFrame" BO_ 2559372123 1;
BA_ "GenMsgCycleTime" BO_ 2559375707 60000;
BA_ "SingleFrame" BO_ 2559375707 1;
BA_ "GenMsgCycleTime" BO_ 2559375963 60000;
BA_ "SingleFrame" BO_ 2559375963 1;
BA_ "GenMsgCycleTime" BO_ 2559367771 60000;
BA_ "SingleFrame" BO_ 2559367771 1;
BA_ "GenMsgCycleTime" BO_ 2559363290 60000;
BA_ "SingleFrame" BO_ 2559363290 1;
BA_ "GenMsgCycleTime" BO_ 2559371994 60000;
BA_ "SingleFrame" BO_ 2559371994 1;
BA_ "GenMsgCycleTime" BO_ 2559372250 60000;
BA_ "SingleFrame" BO_ 2559372250 1;
BA_ "GenMsgCycleTime" BO_ 2559375834 60000;
BA_ "SingleFrame" BO_ 2559375834 1;
BA_ "GenMsgCycleTime" BO_ 2559376090 60000;
BA_ "SingleFrame" BO_ 2559376090 1;
BA_ "GenMsgCycleTime" BO_ 2559335386 60000;
BA_ "SingleFrame" BO_ 2559335386 1;
BA_ "GenMsgCycleTime" BO_ 2559306440 60000;
BA_ "SingleFrame" BO_ 2559306440 1;
BA_ "GenMsgCycleTime" BO_ 2559306696 60000;
BA_ "SingleFrame" BO_ 2559306696 1;
BA_ "GenMsgCycleTime" BO_ 2559310280 60000;
BA_ "SingleFrame" BO_ 2559310280 1;
BA_ "GenMsgCycleTime" BO_ 2559310536 60000;
BA_ "SingleFrame" BO_ 2559310536 1;
BA_ "GenMsgCycleTime" BO_ 2559269832 60000;
BA_ "SingleFrame" BO_ 2559269832 1;
BA_ "GenMsgCycleTime" BO_ 2559302344 60000;
BA_ "SingleFrame" BO_ 2559302344 1;
BA_ "GenMsgCycleTime" BO_ 2559306730 60000;
BA_ "SingleFrame" BO_ 2559306730 1;
BA_ "GenMsgCycleTime" BO_ 2559310314 60000;
BA_ "SingleFrame" BO_ 2559310314 1;
BA_ "GenMsgCycleTime" BO_ 2559310570 60000;
BA_ "SingleFrame" BO_ 2559310570 1;
BA_ "GenMsgCycleTime" BO_ 2559269866 60000;
BA_ "SingleFrame" BO_ 2559269866 1;
BA_ "GenMsgCycleTime" BO_ 2559302378 60000;
BA_ "SingleFrame" BO_ 2559302378 1;
BA_ "GenMsgCycleTime" BO_ 2559306475 60000;
BA_ "SingleFrame" BO_ 2559306475 1;
BA_ "GenMsgCycleTime" BO_ 2559310315 60000;
BA_ "SingleFrame" BO_ 2559310315 1;
BA_ "GenMsgCycleTime" BO_ 2559310571 60000;
BA_ "SingleFrame" BO_ 2559310571 1;
BA_ "GenMsgCycleTime" BO_ 2559269867 60000;
BA_ "SingleFrame" BO_ 2559269867 1;
BA_ "GenMsgCycleTime" BO_ 2559302379 60000;
BA_ "SingleFrame" BO_ 2559302379 1;
BA_ "GenMsgCycleTime" BO_ 2559306490 60000;
BA_ "SingleFrame" BO_ 2559306490 1;
BA_ "GenMsgCycleTime" BO_ 2559306746 60000;
BA_ "SingleFrame" BO_ 2559306746 1;
BA_ "GenMsgCycleTime" BO_ 2559310330 60000;
BA_ "SingleFrame" BO_ 2559310330 1;
BA_ "GenMsgCycleTime" BO_ 2559269882 60000;
BA_ "SingleFrame" BO_ 2559269882 1;
BA_ "GenMsgCycleTime" BO_ 2559302394 60000;
BA_ "SingleFrame" BO_ 2559302394 1;
BA_ "GenMsgCycleTime" BO_ 2559306489 60000;
BA_ "SingleFrame" BO_ 2559306489 1;
BA_ "GenMsgCycleTime" BO_ 2559306745 60000;
BA_ "SingleFrame" BO_ 2559306745 1;
BA_ "GenMsgCycleTime" BO_ 2559310585 60000;
BA_ "SingleFrame" BO_ 2559310585 1;
BA_ "GenMsgCycleTime" BO_ 2559269881 60000;
BA_ "SingleFrame" BO_ 2559269881 1;
BA_ "GenMsgCycleTime" BO_ 2559302393 60000;
BA_ "SingleFrame" BO_ 2559302393 1;
BA_ "GenMsgCycleTime" BO_ 2559306331 60000;
BA_ "SingleFrame" BO_ 2559306331 1;
BA_ "GenMsgCycleTime" BO_ 2559306587 60000;
BA_ "SingleFrame" BO_ 2559306587 1;
BA_ "GenMsgCycleTime" BO_ 2559310171 60000;
BA_ "SingleFrame" BO_ 2559310171 1;
BA_ "GenMsgCycleTime" BO_ 2559310427 60000;
BA_ "SingleFrame" BO_ 2559310427 1;
BA_ "GenMsgCycleTime" BO_ 2559302235 60000;
BA_ "SingleFrame" BO_ 2559302235 1;
BA_ "GenMsgCycleTime" BO_ 2559306458 60000;
BA_ "SingleFrame" BO_ 2559306458 1;
BA_ "GenMsgCycleTime" BO_ 2559306714 60000;
BA_ "SingleFrame" BO_ 2559306714 1;
BA_ "GenMsgCycleTime" BO_ 2559310298 60000;
BA_ "SingleFrame" BO_ 2559310298 1;
BA_ "GenMsgCycleTime" BO_ 2559310554 60000;
BA_ "SingleFrame" BO_ 2559310554 1;
BA_ "GenMsgCycleTime" BO_ 2559269850 60000;
BA_ "SingleFrame" BO_ 2559269850 1;
BA_ "GenMsgCycleTime" BO_ 2566912766 1000;
BA_ "GenMsgSendType" BO_ 2566912766 0;
BA_ "GenMsgCycleTimeFast" BO_ 2566912766 1000;
BA_ "SingleFrame" BO_ 2566912766 1;
BA_ "GenMsgCycleTime" BO_ 2298478129 100;
BA_ "GenMsgSendType" BO_ 2298478129 0;
BA_ "GenMsgCycleTimeFast" BO_ 2298478129 100;
BA_ "SingleFrame" BO_ 2298478129 1;
BA_ "GenMsgCycleTime" BO_ 2566912038 1000;
BA_ "GenMsgSendType" BO_ 2566912038 0;
BA_ "GenMsgCycleTimeFast" BO_ 2566912038 1000;
BA_ "SingleFrame" BO_ 2566912038 1;
BA_ "GenMsgCycleTime" BO_ 2634021630 1000;
BA_ "GenMsgSendType" BO_ 2634021630 0;
BA_ "GenMsgCycleTimeFast" BO_ 2634021630 1000;
BA_ "SingleFrame" BO_ 2634021630 1;
BA_ "GenMsgCycleTime" BO_ 2365587454 1000;
BA_ "GenMsgSendType" BO_ 2365587454 0;
BA_ "GenMsgCycleTimeFast" BO_ 2365587454 1000;
BA_ "SingleFrame" BO_ 2365587454 1;
BA_ "GenMsgCycleTime" BO_ 2432696113 200;
BA_ "GenMsgSendType" BO_ 2432696113 0;
BA_ "GenMsgCycleTimeFast" BO_ 2432696113 40;
BA_ "SingleFrame" BO_ 2432696113 1;
BA_ "GenMsgCycleTime" BO_ 2566913841 1000;
BA_ "GenMsgSendType" BO_ 2566913841 0;
BA_ "GenMsgCycleTimeFast" BO_ 2566913841 100;
BA_ "SingleFrame" BO_ 2566913841 1;
BA_ "GenMsgCycleTime" BO_ 2566912561 1000;
BA_ "GenMsgSendType" BO_ 2566912561 0;
BA_ "GenMsgCycleTimeFast" BO_ 2566912561 100;
BA_ "SingleFrame" BO_ 2566912561 1;
BA_ "GenMsgCycleTime" BO_ 2634021118 1000;
BA_ "GenMsgSendType" BO_ 2634021118 0;
BA_ "GenMsgCycleTimeFast" BO_ 2634021118 1000;
BA_ "SingleFrame" BO_ 2634021118 1;
BA_ "GenMsgCycleTime" BO_ 2499803902 1000;
BA_ "GenMsgSendType" BO_ 2499803902 0;
BA_ "GenMsgCycleTimeFast" BO_ 2499803902 1000;
BA_ "SingleFrame" BO_ 2499803902 1;
BA_ "NmStationAddress" BU_ CAB 49;
BA_ "NmJ1939AAC" BU_ CAB 1;
BA_ "NmJ1939IndustryGroup" BU_ CAB 2;
BA_ "NmJ1939System" BU_ CAB 7;
BA_ "NmJ1939Function" BU_ CAB 37;
BA_ "NmJ1939ManufacturerCode" BU_ CAB 33;
BA_ "NmJ1939IdentityNumber" BU_ CAB 4933;
BA_ "ECU" BU_ CAB "Wallplate";
BA_ "NmStationAddress" BU_ FED 234;
BA_ "NmJ1939AAC" BU_ FED 1;
BA_ "NmJ1939IndustryGroup" BU_ FED 2;
BA_ "NmJ1939System" BU_ FED 7;
BA_ "NmJ1939Function" BU_ FED 132;
BA_ "NmJ1939ECUInstance" BU_ FED 1;
BA_ "NmJ1939ManufacturerCode" BU_ FED 33;
BA_ "NmJ1939IdentityNumber" BU_ FED 234315;
BA_ "ECU" BU_ FED "A66_FEDC";
BA_ "NmStationAddress" BU_ HAD 235;
BA_ "NmJ1939AAC" BU_ HAD 1;
BA_ "NmJ1939IndustryGroup" BU_ HAD 2;
BA_ "NmJ1939System" BU_ HAD 7;
BA_ "NmJ1939Function" BU_ HAD 132;
BA_ "NmJ1939ManufacturerCode" BU_ HAD 33;
BA_ "NmJ1939IdentityNumber" BU_ HAD 235319;
BA_ "ECU" BU_ HAD "A67_HADC";
BA_ "NmStationAddress" BU_ JDL 251;
BA_ "NmJ1939Function" BU_ JDL 130;
BA_ "NmJ1939ManufacturerCode" BU_ JDL 33;
BA_ "NmJ1939IdentityNumber" BU_ JDL 251326;
BA_ "ECU" BU_ JDL "A81___WWHC";
BA_ "NmStationAddress" BU_ OBT 249;
BA_ "NmJ1939Function" BU_ OBT 129;
BA_ "NmJ1939ManufacturerCode" BU_ OBT 33;
BA_ "NmJ1939IdentityNumber" BU_ OBT 249331;
BA_ "ECU" BU_ OBT "OBT1";
BA_ "NmStationAddress" BU_ OBT_FA 250;
BA_ "NmJ1939Function" BU_ OBT_FA 129;
BA_ "NmJ1939ECUInstance" BU_ OBT_FA 1;
BA_ "NmJ1939ManufacturerCode" BU_ OBT_FA 33;
BA_ "NmJ1939IdentityNumber" BU_ OBT_FA 250332;
BA_ "ECU" BU_ OBT_FA "OBT_FA";
BA_ "NmStationAddress" BU_ PDU 40;
BA_ "NmJ1939AAC" BU_ PDU 1;
BA_ "NmJ1939IndustryGroup" BU_ PDU 2;
BA_ "NmJ1939System" BU_ PDU 7;
BA_ "NmJ1939Function" BU_ PDU 19;
BA_ "NmJ1939ManufacturerCode" BU_ PDU 33;
BA_ "NmJ1939IdentityNumber" BU_ PDU 40336;
BA_ "ECU" BU_ PDU "A90_NGPD";
BA_ "NmStationAddress" BU_ POD 91;
BA_ "NmJ1939AAC" BU_ POD 1;
BA_ "NmJ1939IndustryGroup" BU_ POD 2;
BA_ "NmJ1939System" BU_ POD 7;
BA_ "NmJ1939Function" BU_ POD 79;
BA_ "NmJ1939ManufacturerCode" BU_ POD 33;
BA_ "NmJ1939IdentityNumber" BU_ POD 91337;
BA_ "ECU" BU_ POD "A68_PODC";
BA_ "NmStationAddress" BU_ VTV 38;
BA_ "NmJ1939AAC" BU_ VTV 1;
BA_ "NmJ1939IndustryGroup" BU_ VTV 2;
BA_ "NmJ1939System" BU_ VTV 1;
BA_ "NmJ1939Function" BU_ VTV 29;
BA_ "NmJ1939ManufacturerCode" BU_ VTV 33;
BA_ "NmJ1939IdentityNumber" BU_ VTV 38346;
BA_ "ECU" BU_ VTV "A55___WWHC";
BA_ "NmStationAddress" BU_ XCP 218;
BA_ "NmJ1939IndustryGroup" BU_ XCP 2;
BA_ "NmJ1939Function" BU_ XCP 47;
BA_ "NmJ1939ManufacturerCode" BU_ XCP 33;
BA_ "NmJ1939IdentityNumber" BU_ XCP 218148;
BA_ "ECU" BU_ XCP "XCP";
BA_ "NmStationAddress" BU_ DC1 200;
BA_ "NmJ1939AAC" BU_ DC1 1;
BA_ "NmJ1939IndustryGroup" BU_ DC1 2;
BA_ "NmJ1939System" BU_ DC1 7;
BA_ "NmJ1939Function" BU_ DC1 25;
BA_ "NmJ1939ManufacturerCode" BU_ DC1 33;
BA_ "NmJ1939IdentityNumber" BU_ DC1 1059;
BA_ "ECU" BU_ DC1 "A60_DC1";
BA_ "NmStationAddress" BU_ MTU 216;
BA_ "NmJ1939SystemInstance" BU_ MTU 1;
BA_ "NmJ1939Function" BU_ MTU 28;
BA_ "NmJ1939FunctionInstance" BU_ MTU 1;
BA_ "NmJ1939ManufacturerCode" BU_ MTU 33;
BA_ "NmJ1939IdentityNumber" BU_ MTU 13171;
BA_ "ECU" BU_ MTU "MTU_EngineEmissionMTG";
BA_ "DBName"   "VehB1";
BA_ "SAE_J1939_75_SpecVersion"   "2022-05";
BA_ "SAE_J1939_21_SpecVersion"   "2022-05";
BA_ "SAE_J1939_73_SpecVersion"   "2022-05";
BA_ "SAE_J1939_71_SpecVersion"   "2022-05";
VAL_ 2566757374 AftrtrtmntDEFProp 0 " Urea concentration too high" 1 " Urea concentration too low" 2 " Fluid is diesel" 3 " Diesel exhaust fluid is proper mixture" 13 " Not able to determine diesel exhaust fluid property fluid type unknown" 14 " Error" 15 " Not Available" ;
VAL_ 2566805246 AftrtrtmntSCROptrIndcmntSevrty 0 " No inducement active" 1 " Inducement level 1" 2 " Inducement level 2" 3 " Inducement level 3" 4 " Inducement level 4" 5 " Inducement level 5" 6 " Error" 7 " Not Available" ;
VAL_ 2566805246 AftrtrtmntDEFTankLoLvlInd 0 " OFF" 1 " ON_Solid" 4 " ON_FastBlink_1Hz" 6 " Reserved" 7 " Error" ;
VAL_ 2432635995 HarvestSmartPauseResumeCmd 0 " DEM_Pause" 1 " DEM_Resume" 2 " DEM_Error" 3 " DEM_NotAvailable" ;
VAL_ 2298409307 BrakeSwitch 0 " Released" 1 " Depressed" 2 " Error" 3 " NotAvailable" ;
VAL_ 2566749438 CANExhstSysHighTempLmpCmd 0 " Off" 1 " On__Solid" 6 " RsrvdStds" 7 " NoAction" ;
VAL_ 2566719270 EngRedStopLmpCmd 0 " En_OnOff2States_Off" 1 " En_OnOff2States_On" 2 " En_OnOff2States_Error" 3 " En_OnOff2States_NotAvailable" ;
VAL_ 2364539995 EngineTorqueMode 0 " Low idle governor no request default mode" 1 " Accelerator Pedal" 2 " Cruise Control" 3 " PTO Governor" 4 " Road Speed Governing" 5 " ASR Control" 6 " Transmission Control" 7 " ABS Conrol" 8 " Torque Limiting" 9 " High Speed Governor" 10 " Brake System Electronic" 11 " Remote Accelerator" 14 " Other" 12 " Not defined 1" 13 " Not defined 2" 15 " Not available" ;
VAL_ 2364539995 EngStarterMode 0 " Start not requested" 1 " Starter not active gear not engaged" 2 " Starter active gear engaged" 3 " Start finished starter not active after having been actively engaged after 50ms mode goes to 0000" 4 " Starter inhibited due to engine already running" 5 " Starter inhibited due to engine not ready for start preheating" 6 " Starter inhibited due to driveline engaged or other transmission inhibit" 7 " Starter inhibited due to active immobilizer" 8 " Start inhibited due to starter over temp" 12 " Starter inhibited reason unknown" 13 " Error legacy implementation only use 1110 instead" 14 " Error" 15 " Not available" ;
VAL_ 2364539902 AccelPedalLoIdleSw 0 " Not in low idle condition" 1 " In low idle condition" 2 " Error" 3 " Not_available_or_ not_installed" ;
VAL_ 2364539902 AccelPedalKckdownSw 0 " Kickdown passive" 1 " Kickdown active" 2 " Error" 3 " Not available or not installed" ;
VAL_ 2364539902 RoadSpdLimState 0 " DEM_Not_active" 1 " DEM_Active" 2 " DEM_Error" 3 " DEM_Not_availablenot_installed" ;
VAL_ 2364539902 AccelPedal2LoIdleSw 0 " Not in low idle condition" 1 " In low idle condition" 2 " Error" 3 " Not available or not installed" ;
VAL_ 2364539902 VehAccelRateLimState 0 " DEM_Not_active" 1 " DEM_Active" 2 " DEM_Error" 3 " DEM_Not_availablenot_installed" ;
VAL_ 2364539902 MomEngMaxPwrEnblFdbk 0 " Disabled" 1 " Supported" 2 " Error" 3 " Not Available" ;
VAL_ 2364539902 DPFThrmlMngmntActive 0 " DEM_Not_active" 1 " DEM_Active" 2 " Rsrvd_Stds" 3 " DEM_Not_availablenot_installed" ;
VAL_ 2364539902 SCRThrmlMngmntActv 0 " DEM_Not_active" 1 " DEM_Active" 2 " Rsrvd_Stds" 3 " DEM_Not_availablenot_installed" ;
VAL_ 2566840318 AftertreatmentIntakeDewPnt 0 " Not Exceeded" 1 " Exceeded" 2 " Error" 3 " Not Available" ;
VAL_ 2566840318 AftertreatmentExhaustDewPnt 0 " Not Exceeded" 1 " Exceeded" 2 " Error" 3 " Not Available" ;
VAL_ 2566840318 Aftertreatment2IntakeDewPnt 0 " Not Exceeded" 1 " Exceeded" 2 " Error" 3 " Not Available" ;
VAL_ 2566840318 Aftertreatment2ExhDewPnt 0 " Not Exceeded" 1 " Exceeded" 2 " Error" 3 " Not Available" ;
VAL_ 2432537179 EngOpState 0 " DEM_Engine_Stopped" 1 " DEM_PreStart" 2 " DEM_Starting" 3 " DEM_WarmUp" 4 " DEM_Running" 5 " DEM_Cooldown" 6 " DEM_Engine_Stopping" 7 " DEM_PostRun" 14 " DEM_RsrvdStds" 15 " DEM_Dont_caretake_no_action" ;
VAL_ 2431708465 EngineStartRequest 0 " Start not requested" 1 " Start requested operator type" 2 " Start requested automatic type" 3 " Not available" ;
VAL_ 2431708651 EngineStartConsent 0 " DEM_No_consent" 1 " DEM_Consent_to_operatorrequested_start_only" 2 " DEM_Consent_to_automatic_start_only" 3 " DEM_Consent_to_both_operatorrequested_and_automatic_start" 6 " DEM_Error" 7 " DEM_Not_availablenot_installed" ;
VAL_ 2431708507 EngineStartConsent 0 " DEM_No_consent" 1 " DEM_Consent_to_operatorrequested_start_only" 2 " DEM_Consent_to_automatic_start_only" 3 " DEM_Consent_to_both_operatorrequested_and_automatic_start" 6 " DEM_Error" 7 " DEM_Not_availablenot_installed" ;
VAL_ 2360147966 MechSysLockout 0 " EnTwoStNo" 1 " EnTwoStYes" 2 " EnTwoStErr" 3 " EnTwoStNotAvl" ;
VAL_ 2360147966 StrgSysReadiness 0 " EnTwoStNo" 1 " EnTwoStYes" 2 " EnTwoStErr" 3 " EnTwoStNotAvl" ;
VAL_ 2360147966 StrgInputPstnState 0 " EnTwoStNo" 1 " EnTwoStYes" 2 " EnTwoStErr" 3 " EnTwoStNotAvl" ;
VAL_ 2360147966 ReqResetCmdState 0 " EnTwoStNo" 1 " EnTwoStYes" 2 " EnTwoStErr" 3 " EnTwoStNotAvl" ;
VAL_ 2360147966 GuideLimState 0 " EnNavLimStNotLimd" 1 " EnNavLimStOpertLimd" 2 " EnNavLimStLimdHi" 3 " EnNavLimStLimdLo" 6 " EnNavLimStErr" 7 " EnNavLimStUkwn" ;
VAL_ 2360147966 GuideSysCmdExitRsnCode 0 " ATECNoCode" 1 " ATECTransmissionInPark" 2 " ATECFICAFault" 3 " ATECWhlSpdSlow" 4 " ATECAltGuidanceActive" 5 " ATECIncorrectGear" 13 " ATECCmdMsdTimeout" 250 " ATECLastTransitionOk" 16 " ATECAuthDenied" 21 " ATECWhlSpdFast" 22 " ATECOilTempTooLow" 23 " ATECDiagMode" 24 " ATECCtrlState" 25 " ATECResumeNotPressed" 26 " ATECCurvatureNotMatched" 50 " ATECInvalidCommand" 51 " ATECNoOperatorPresence" 52 " ATECImpReleasedControl" 53 " ATECGlobalStop" 54 " ATECOperatorOverride" 62 " ATECECError" 63 " ATECECNotAvailable" 64 " ATECStartUp" 65 " ATECShutDown" 66 " ATECAutoTracShutdown" 67 " ATECEngineOff" 68 " ATECNotCalibrated" 69 " ATECVoltagenotStable" 70 " ATECOperatorPresenceDataBad" 71 " ATECResumeSwitchDataBad" 72 " ATECVehStateMsgMissing" 73 " ATECVehStateMsgBadData" 74 " ATECAdvGuidanceStatusMsgMissing" 75 " ATECAdvGuidanceStatusMsgBadData" 76 " ATECActiveInReverseTimeout" 77 " ATECGPSWheelSpeedMismatch" 78 " ATECNoValidTrack" 79 " ATECInvalidGPS" 80 " ATECShutdownStateFaulted" 81 " ATECGSDDataFaulted" 82 " ATECExtGuidanceStatusMsgFaulted" 83 " ATECExtGuidanceStatusExtendedMsgFaulted" 84 " ATECVehDirSpeedMsgFaulted" 85 " ATECVehRollYawMsgFaulted" 86 " ATECTCMMsgFaulted" 87 " ATECLateralError" 88 " ATECHeadingError" 89 " ATECTrackNumChanged" 90 " ATECTCMInactive" 91 " ATECRSGPSTransitionTooLarge" 92 " ATECRSOutOfRow" 93 " ATECRSGreenstarTrackingFault" 94 " ATECRSSensorFault" 95 " ATECRSGPSFault" 100 " ATECTransportMode" 101 " ATECAuxPumpOn" 102 " ATECBoomsFolded" 103 " ATECHeaderNotEngaged" 104 " ATECFourWheelSteerTimeout" 105 " ATECCrabSteering" 254 " ATECEC8BitError" 255 " ATECEC8BitNotAvailable" ;
VAL_ 2360213286 CurvatureCmdState 0 " EnCrvtCmdStNotIntdToSteer" 1 " EnCrvtCmdStIntdToSteer" 2 " EnCrvtCmdStErr" 3 " EnCrvtCmdStNoActn" ;
VAL_ 2365528881 SAS_Mask 0 " SASKostalUnavailable" 1 " SASKostalAvailable" ;
VAL_ 2365528881 SAS_SensorType 0 " SASTypeKostalInvalid_Typ1" 1 " SASTypeKostalInvalid_Typ0" 2 " SASTypeKostalInvalid_Typ2" 3 " SASTypeKostalValid" ;
VAL_ 2365528881 SAS_CalibrationStatus 0 " SASKostalCalibrationStatusValid" 1 " SASKostalCalibrationStatusInvalid_1" 2 " SASKostalCalibrationStatusInvalid_2" 3 " SASKostalCalibrationStatusInvalid_3" ;
VAL_ 2365528881 SAS_DataIsValid 0 " SASKostalDataInvalid" 1 " SASKostalDataValid" ;
VAL_ 2361850878 HeaderLiftValveStateFeedback 0 " DEM_Block" 1 " DEM_Extend" 2 " DEM_Retract" 14 " DEM_Error" 15 " DEM_Not_Available" ;
VAL_ 2361851902 HeaderLiftValveStateFeedback 0 " DEM_Block" 1 " DEM_Extend" 2 " DEM_Retract" 14 " DEM_Error" 15 " DEM_Not_Available" ;
VAL_ 2365582427 RightTurnSignalLightsCommand 0 " DEM_Deactivate" 1 " DEM_Activate" 2 " DEM_Reserved__Stds" 3 " DEM_Dont_caretake_no_action" ;
VAL_ 2365582427 LeftTurnSignalLightsCommand 0 " DEM_Deactivate" 1 " DEM_Activate" 2 " DEM_Reserved__Stds" 3 " DEM_Dont_caretake_no_action" ;
VAL_ 2365582427 TrlrIndLightCmd 0 " DEM_Deactivate" 1 " DEM_Activate" 2 " DEM_Reserved__Stds" 3 " DEM_Dont_caretake_no_action" ;
VAL_ 2365473073 RotatingBeaconLightCommand 0 " Deactivate" 1 " Activate" 2 " Reserved_Stds" 3 " Not Available" ;
VAL_ 2365473073 LeftStopLightCommand 0 " Deactivate" 1 " Activate" 2 " Reserved_Stds" 3 " Not Available" ;
VAL_ 2365473073 MarkerLightCommand 0 " Deactivate" 1 " Activate" 2 " Reserved_Stds" 3 " Not Available" ;
VAL_ 2566801386 MaintainActuatorPower 0 " DEM_Off" 1 " DEM_On" 2 " DEM_Error" 3 " DEM_Not_available_or_not_installed" ;
VAL_ 2566801386 MaintainECUPower 0 " DEM_Off" 1 " DEM_On" 2 " DEM_Error" 3 " DEM_Not_available_or_not_installed" ;
VAL_ 2566801386 ImplementWorkState 0 " Disengaged" 1 " Engaged" 2 " Error" 3 " NotAvailable" ;
VAL_ 2566801386 ImplementParkState 0 " CannotDisconnect" 1 " DisconnectReady" 2 " Error" 3 " NotAvailable" ;
VAL_ 2566801386 ImplementTransportState 0 " NotTrasportReady" 1 " TrasportReady" 2 " Error" 3 " NotAvailable" ;
VAL_ 2566801387 MaintainActuatorPower 0 " DEM_Off" 1 " DEM_On" 2 " DEM_Error" 3 " DEM_Not_available_or_not_installed" ;
VAL_ 2566801387 MaintainECUPower 0 " DEM_Off" 1 " DEM_On" 2 " DEM_Error" 3 " DEM_Not_available_or_not_installed" ;
VAL_ 2566801387 ImplementWorkState 0 " Disengaged" 1 " Engaged" 2 " Error" 3 " NotAvailable" ;
VAL_ 2566801387 ImplementParkState 0 " CannotDisconnect" 1 " DisconnectReady" 2 " Error" 3 " NotAvailable" ;
VAL_ 2566801387 ImplementTransportState 0 " NotTrasportReady" 1 " TrasportReady" 2 " Error" 3 " NotAvailable" ;
VAL_ 2566801243 MaintainActuatorPower 0 " DEM_Off" 1 " DEM_On" 2 " DEM_Error" 3 " DEM_Not_available_or_not_installed" ;
VAL_ 2566801243 ImplementWorkState 0 " Disengaged" 1 " Engaged" 2 " Error" 3 " NotAvailable" ;
VAL_ 2566801243 ImplementParkState 0 " CannotDisconnect" 1 " DisconnectReady" 2 " Error" 3 " NotAvailable" ;
VAL_ 2566801243 ImplementTransportState 0 " NotTrasportReady" 1 " TrasportReady" 2 " Error" 3 " NotAvailable" ;
VAL_ 2515538171 TimeSource_SDC 0 " GPS" 1 " GLONASS" 2 " WWV or Radio Station" 3 " Local Cesium Clock" 4 " Local Rubidium Clock" 5 " Local Crystal Clock" 15 " Null" ;
VAL_ 2499700827 HydOilFilterRestrictionSwitch 0 " DEM_Not_restricted" 1 " DEM_Restricted" 2 " DEM_Error" 3 " DEM_Not_availablenot_installed" ;
VAL_ 2566912766 CmdBytePGN65530_Vector_XXX 329 "AcceleratedDOCSCRTemperatures " 585 "AcceleratedDPFSCROutletNOx " 20483 "AirSystemObserverCorrectionFactors1 " 20739 "AirSystemObserverPlausibility1 " 20995 "AirSystemObserverPlausibility2 " 21507 "EngineTemperaturesAndPressures " 17409 "MTGAftertreatmentControl1 " 17153 "MTGEngineConsumptionAndOperation " ;
VAL_ 2298478129 CmdBytePGN65534_CAB 5 "ACsystem " 253 "OperatorControlsEncoders " ;
VAL_ 2298478129 ACCompressorRequest 0 " DEM_Off" 1 " DEM_On" 2 " DEM_Reserved__Stds" 3 " DEM_Dont_caretake_no_action" ;
VAL_ 2566912038 CmdBytePGN65528_VTV 106 "Active_Yield_Assist_Status " 202 "Grain_Quality_Diagnostic_Information_#1 " 198 "TailingsBypassCleanGrainInformation1 " ;
VAL_ 2566912038 ActiveYieldState 0 " En_ActiveYieldState_User_Disabled" 1 " En_ActiveYieldState_Disabled_Unsupported_Crop_Type" 2 " En_ActiveYieldState_Disabled_Option_Not_Installed" 3 " En_ActiveYieldState_Enabled_Supported_Crop" 5 " En_ActiveYieldState_Disabled_CropChangedToSupported" 14 " En_ActiveYieldState_AY_State_Error" 15 " En_ActiveYieldState_AY_State_NotAvailable" ;
VAL_ 2566912038 IPMOperationalStatus 0 " Standby" 1 " Operational with both cameras" 2 " IPM Error State" 3 " Reprogramming" 4 " Operational with Grain Bypass camera only" 5 " Operational with Tailings Bypass camera only" 14 " Error" 15 " Not available or not installed" ;
VAL_ 2566912038 GQMReportingState 0 " DTC inactive" 1 " DTC active" ;
VAL_ 2566912038 CleanGrainCameraUnavailable 0 " DTC inactive" 1 " DTC active" ;
VAL_ 2566912038 CleanGrainCameraHardware 0 " DTC inactive" 1 " DTC active" ;
VAL_ 2634021630 CmdBytePGN65530_Vector_XXX 22019 "ActuatorAirModes " 21763 "AirSystemStates " 22275 "AirSystemObserverCorrectionFactors2 " 21251 "AirSystemObserverCorrectionFactors3 " ;
VAL_ 2365587454 CmdBytePGN65535_Vector_XXX 147 "Advanced_Guidance_Status_Response " ;
VAL_ 2365587454 AutoTracSysCtlrUnlimitRevCapable 0 " EnTwoStNo" 1 " EnTwoStYes" 2 " EnTwoStErr" 3 " EnTwoStNotAvl" ;
VAL_ 2365587454 AuxResuCap 0 " EnTwoStNo" 1 " EnTwoStYes" 2 " EnTwoStErr" 3 " EnTwoStNotAvl" ;
VAL_ 2365587454 WASType 0 " MacCrvtSnsrTypExternal" 1 " MacCrvtSnsrTyp90DegDualPWM" 2 " MacCrvtSnsrTyp120DegDualPWM" 3 " MacCrvtSnsrTyp180DegDualPWM" 4 " MacCrvtSnsrTyp240DegDualPWM" 5 " MacCrvtSnsrTyp90DegDualAn" 6 " MacCrvtSnsrTyp120DegDualAn" 7 " MacCrvtSnsrTyp180DegDualAn" 8 " MacCrvtSnsrTyp240DegDualAn" 9 " MacCrvtSnsrTypATCMotEncder" 10 " MacCrvtSnsrTyp135DegDualAn" 11 " MacCrvtSnsrTyp139DegDualAn" 14 " MacCrvtSnsrTypErr" 15 " MacCrvtSnsrTypUkwn" ;
VAL_ 2365587454 ConfigMachineClass 0 " MacClassDefault" 1 " MacClassTractorRowCrop" 2 " MacClassArticulated" 3 " MacClassTractor2Tracks" 4 " MacClassCombine" 5 " MacClassCotton" 6 " MacClassSPFH" 7 " MacClassSugarcane" 8 " MacClassWindrower" 9 " MacClassWetSprayer" 10 " MacClassDrySprayer" 11 " MacClassSpreader" 12 " MacClassUtilityVehicle" ;
VAL_ 2365587454 SIDType 0 " SteerInpDevTypExt" 1 " SteerInpDevTypCANSID" 2 " SteerInpDevTypBEIDualChPWM" 3 " SteerInpDevTypATCFlowSwt" 6 " SteerInpDevTypErr" 7 " SteerInpDevTypUkwn" ;
VAL_ 2365587454 ActuatorType 0 " CM_CanActrTypExtActr" 1 " CM_CanActrTypFEMAVlv" 2 " CM_CanActrTypDanfossVlv" 3 " CM_CanActrTypCANDanfossVlv" 4 " CM_CanActrTypATCMot" 6 " CM_CanActrTypErr" 7 " CM_CanActrTypUkwn" ;
VAL_ 2365587454 StarfireFwdCfg_AGSR 0 " StarFireFwdCfgOff" 1 " StarFireFwdCfgCAN2ToCAN1" 2 " StarFireFwdCfgCAN2ToEth" 3 " StarFireFwdCfgEthToCAN1AndCan2" 6 " StarFireFwdCfgErr" 7 " StarFireFwdCfgUkwn" ;
VAL_ 2432696113 CmdBytePGN65535_CAB 6 "ArmrestCoverMatrixInputs1Combine " 236 "OperatorSeatData " ;
VAL_ 2432696113 QuickStopSwitch 0 " DEM_Off" 1 " DEM_On" 2 " DEM_Error" 3 " DEM_Not_available_or_not_installed" ;
VAL_ 2432696113 OperatorSeatSwitch 0 " DEM_Operator_Not_Present" 1 " DEM_Operator_Present" 2 " DEM_Error" 3 " DEM_Not_Available" ;
VAL_ 2566913841 CmdBytePGN65535_CAB 135 "ArmrestControlUnitStatus2 " ;
VAL_ 2566913841 WasherPumpCmdFrnt 0 " Off" 1 " On" 2 " Error" 3 " NotAvailable" ;
VAL_ 2566913841 WasherPumpCmdRight 0 " Off" 1 " On" 2 " Error" 3 " NotAvailable" ;
VAL_ 2566912561 CmdBytePGN65530_CAB 38914 "ATCSystemTemperatures1 " 28673 "JD_Configurable_Lighting_Command_-_Left_Hand_Work_Lights " 28929 "JD_Configurable_Lighting_Command_-_Right_Hand_Work_Lights " ;
VAL_ 2566912561 WorkLight1LeftCmd 0 " Deactivate" 1 " Activate" 2 " Reserved_Stds" 3 " Dont_care_take_no_action" ;
VAL_ 2566912561 WorkLight4LeftCmd 0 " Deactivate" 1 " Activate" 2 " Reserved_Stds" 3 " Dont_care_take_no_action" ;
VAL_ 2566912561 WorkLight9LeftCmd 0 " Deactivate" 1 " Activate" 2 " Reserved_Stds" 3 " Dont_care_take_no_action" ;
VAL_ 2566912561 WorkLight10LeftCmd 0 " Deactivate" 1 " Activate" 2 " Reserved_Stds" 3 " Dont_care_take_no_action" ;
VAL_ 2566912561 WorkLight13LeftCmd 0 " Deactivate" 1 " Activate" 2 " Reserved_Stds" 3 " Dont_care_take_no_action" ;
VAL_ 2566912561 WorkLight22LeftCmd 0 " Deactivate" 1 " Activate" 2 " Reserved_Stds" 3 " Dont_care_take_no_action" ;
VAL_ 2566912561 WorkLight1RightCmd 0 " Deactivate" 1 " Activate" 2 " Reserved_Stds" 3 " Dont_care_take_no_action" ;
VAL_ 2566912561 WorkLight4RightCmd 0 " Deactivate" 1 " Activate" 2 " Reserved_Stds" 3 " Dont_care_take_no_action" ;
VAL_ 2566912561 WorkLight9RightCmd 0 " Deactivate" 1 " Activate" 2 " Reserved_Stds" 3 " Dont_care_take_no_action" ;
VAL_ 2566912561 WorkLight10RightCmd 0 " Deactivate" 1 " Activate" 2 " Reserved_Stds" 3 " Dont_care_take_no_action" ;
VAL_ 2566912561 WorkLight13RightCmd 0 " Deactivate" 1 " Activate" 2 " Reserved_Stds" 3 " Dont_care_take_no_action" ;
VAL_ 2566912561 WorkLight19RightCmd 0 " Deactivate" 1 " Activate" 2 " Reserved_Stds" 3 " Dont_care_take_no_action" ;
VAL_ 2566912561 WorkLight20RightCmd 0 " Deactivate" 1 " Activate" 2 " Reserved_Stds" 3 " Dont_care_take_no_action" ;
VAL_ 2566912561 WorkLight21RightCmd 0 " Deactivate" 1 " Activate" 2 " Reserved_Stds" 3 " Dont_care_take_no_action" ;
VAL_ 2566912561 WorkLight22RightCmd 0 " Deactivate" 1 " Activate" 2 " Reserved_Stds" 3 " Dont_care_take_no_action" ;
VAL_ 2634021118 CmdBytePGN65528_Vector_XXX 150 "ATNOxCEStatistics " ;
VAL_ 2634021118 SCRNOXCEMonState 0 " Idle" 1 " Run" 2 " Standby" 3 " NotAvailable" ;
VAL_ 2634021118 SCRAdapConDisable 0 " EnBooleanFalse" 1 " EnBooleanTrue" 2 " EnBooleanError" 3 " EnBooleanNotAvailable" ;
VAL_ 2499803902 CmdBytePGN65530_Vector_XXX 1799 "AttachmentFramePressureSensors " 21505 "AutoDeckPlateParameters3 " 16131 "Calibration_Load_Information_#4 " 770 "Estimated_Harvested_Weight " 2310 "Filter1MOGAdjusted " 31232 "GrainLossAreaInformation " 31488 "GrainLossMassInformation " 30976 "HarvestMetrics1 " 1286 "HarvestMetrics2 " 4102 "HSAAutoAdjustEnableStatus " 36610 "HSAConditionModifiers " 1542 "HSASeverity " 1798 "HSASeverity2 " 13057 "PerceptionSystemStatus " 34560 "SDAStatusLED1 " 34816 "SDAStatusLED2 " 2054 "SODataMessage " 2055 "WingPressureSensors " 2818 "Yield_Calibration_Factor " 514 "Yield_Monitoring_System_Information " ;
VAL_ 2499803902 AttachmentFrameServiceStatus 0 " En_PressureStatus_Pressurized" 1 " En_PressureStatus_PressureLow" 2 " En_PressureStatus_Drained" 3 " En_PressureStatus_Faulted" 14 " En_PressureStatus_Error" 15 " En_PressureStatus_NotAvailable" ;
VAL_ 2499803902 SOExhaustedStateModel 0 " Not Active" 1 " Active" ;
VAL_ 2499803902 SOStableStatus 0 " Counter Not Met" 1 " Counter Met" ;
VAL_ 2499803902 LeftWingServiceStatus 0 " En_PressureStatus_Pressurized" 1 " En_PressureStatus_PressureLow" 2 " En_PressureStatus_Drained" 3 " En_PressureStatus_Faulted" 14 " En_PressureStatus_Error" 15 " En_PressureStatus_NotAvailable" ;
VAL_ 2499803902 RightWingServiceStatus 0 " En_PressureStatus_Pressurized" 1 " En_PressureStatus_PressureLow" 2 " En_PressureStatus_Drained" 3 " En_PressureStatus_Faulted" 14 " En_PressureStatus_Error" 15 " En_PressureStatus_NotAvailable" ;
VAL_ 2499803902 SOAutoAdjustEnabled_CleaningFan 0 " Disabled" 1 " Enabled" ;
VAL_ 2499803902 SOAutoAdjuEnabSievClea 0 " Disabled" 1 " Enabled" ;
VAL_ 2499803902 SOAutoAdjuEnabChafClea 0 " Disabled" 1 " Enabled" ;
VAL_ 2499803902 SOAutoAdjuEnabThreClea 0 " Disabled" 1 " Enabled" ;
VAL_ 2499803902 SOAutoAdjuEnabThreSpee 0 " Disabled" 1 " Enabled" ;
VAL_ 2499803902 ReelCenterTubeFLPSysHealth 0 " OK" 1 " Fail" 2 " Degraded" 3 " Unknown" 14 " Error" 15 " Not available_not installed" ;
VAL_ 2499803902 NmbrCalLoads 0 " Zero or Reserved" 1 " One" 2 " Two" 3 " Three" 4 " Four" 5 " Five" 6 " Six" 7 " Seven" 8 " Eight" 9 " Nine" 10 " Ten" 11 " Eleven" 12 " Twelve" 13 " Thirteen" 14 " Reserved" 15 " Dont Care No Action" ;
VAL_ 2499803902 MsgSeqIndex 0 " Zero or Reserved" 1 " One" 2 " Two" 3 " Three" 4 " Four" 5 " Five" 6 " Six" 7 " Seven" 8 " Eight" 9 " Nine" 10 " Ten" 11 " Eleven" 12 " Twelve" 13 " Thirteen" 14 " Error" 15 " Not Available" ;
VAL_ 2499803902 CalLoadDesignator 0 " Zero or Reserved" 1 " One" 2 " Two" 3 " Three" 4 " Four" 5 " Five" 6 " Six" 7 " Seven" 8 " Eight" 9 " Nine" 10 " Ten" 11 " Eleven" 12 " Twelve" 13 " Thirteen" 14 " Reserved" 15 " Dont Care No Action" ;
VAL_ 2499803902 CalLoadSelected 0 " No" 1 " Yes" 2 " Error" 3 " Not available or not installed" ;
VAL_ 2499803902 AutoDeckplateEnable 0 " Disabled" 1 " Enabled" 2 " Error" 3 " Not Available" ;
VAL_ 2499803902 AutoDeckplateCmdFromHCU 0 " Off" 1 " On" 2 " Error" 3 " Not Available" ;
VAL_ 2499803902 HdrAutomationFeaturesStatus 1 " RecommendedFeatureEnabled" 2 " CustomFeatureEnabled" 3 " RecommendedFeatureError" 4 " CustomFeatureError" 14 " Error" 15 " NotAvailable" ;
VAL_ 2499803902 AutoDeckPlatTighLeveFromHCU 1 " Level1" 2 " Level2" 3 " Level3" 4 " Level4" 5 " Level5" 14 " Error" 15 " NotAvailable" ;
VAL_ 2499803902 AutoDeckPlateOptionInstalled 0 " False" 1 " True" 2 " Error" 3 " NotAvailable" ;
VAL_ 2499803902 SDAStatusLED_GSA_Sense 0 " Green" 1 " Blue" 2 " Amber" 3 " Red" 4 " Gray" 14 " Error" 15 " Not Available" ;
VAL_ 2499803902 SDAStatusLED_GSA_Decide 0 " Green" 1 " Blue" 2 " Amber" 3 " Red" 4 " Gray" 14 " Error" 15 " Not Available" ;
VAL_ 2499803902 SDAStatusLED_GSA_Act 0 " Green" 1 " Blue" 2 " Amber" 3 " Red" 4 " Gray" 14 " Error" 15 " Not Available" ;
VAL_ 2499803902 SDAStatusLED_HSA_Sense 0 " Green" 1 " Blue" 2 " Amber" 3 " Red" 4 " Gray" 14 " Error" 15 " Not Available" ;
VAL_ 2499803902 SDAStatusLED_HSA_Decide 0 " Green" 1 " Blue" 2 " Amber" 3 " Red" 4 " Gray" 14 " Error" 15 " Not Available" ;
VAL_ 2499803902 SDAStatusLED_HSA_Act 0 " Green" 1 " Blue" 2 " Amber" 3 " Red" 4 " Gray" 14 " Error" 15 " Not Available" ;
VAL_ 2499803902 SDAStatusLED_TSA_Sense 0 " Green" 1 " Blue" 2 " Amber" 3 " Red" 4 " Gray" 14 " Error" 15 " Not Available" ;
VAL_ 2499803902 SDAStatusLED_TSA_Decide 0 " Green" 1 " Blue" 2 " Amber" 3 " Red" 4 " Gray" 14 " Error" 15 " Not Available" ;
VAL_ 2499803902 SDAStatusLED_TSA_Act 0 " Green" 1 " Blue" 2 " Amber" 3 " Red" 4 " Gray" 14 " Error" 15 " Not Available" ;
VAL_ 2499803902 ThreshingConditionModifier 0 " Difficult" 1 " Normal" 2 " Easy" 14 " Error" 15 " Not Available" ;
VAL_ 2499803902 StrawConditionModifier 0 " Tough or High Moisture" 1 " Normal" 2 " Brittle or Dry" 14 " Error" 15 " Not Available" ;
